[part 15 of 15: packages /ComponentTypes to /RecDataType]
AUTOSAR XML (schema 4-3-0)
package /ComponentTypes  (continued)
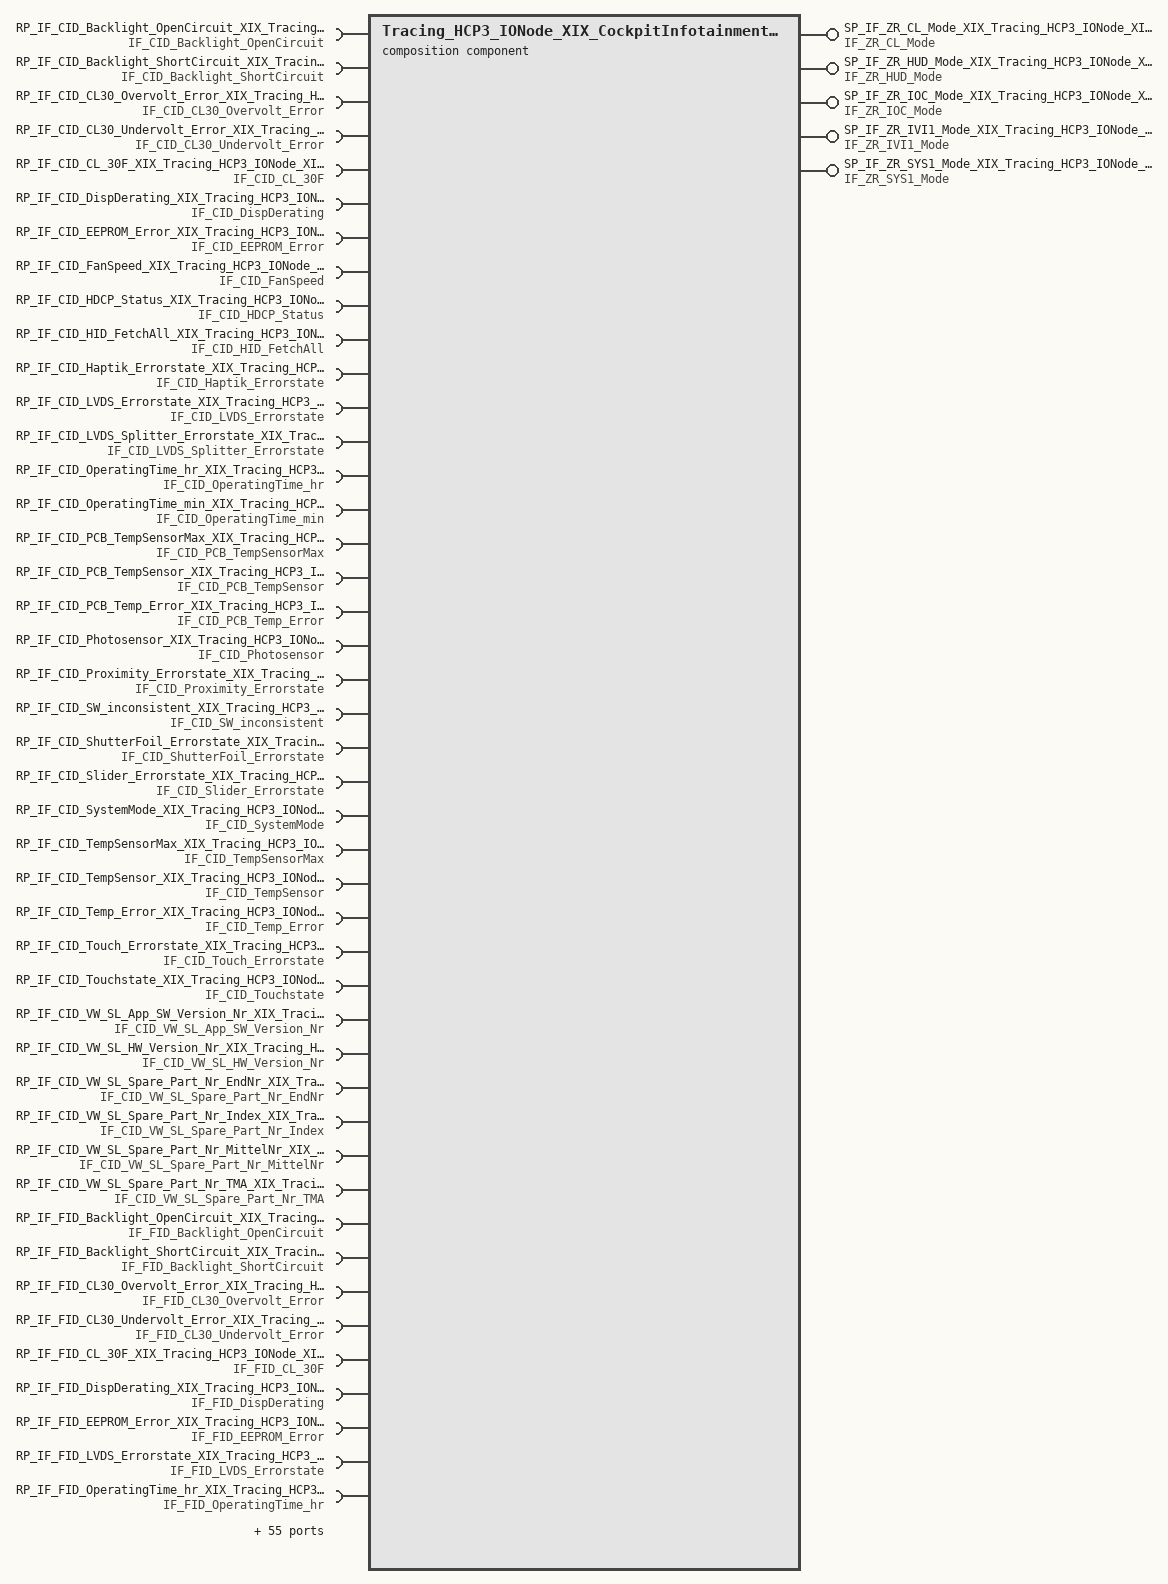
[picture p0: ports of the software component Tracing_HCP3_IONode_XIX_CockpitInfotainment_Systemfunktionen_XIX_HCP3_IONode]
  composition sw component type Tracing_HCP3_IONode_XIX_CockpitInfotainment_Systemfunktionen_XIX_HCP3_IONode
    5 x provide port:
      SP_IF_ZR_CL_Mode_XIX_Tracing_HCP3_IONode_XIX_CockpitInfotainment_Systemfunktionen_XIX_HCP3_IONode: provided-interface=IF_ZR_CL_Mode
      SP_IF_ZR_HUD_Mode_XIX_Tracing_HCP3_IONode_XIX_CockpitInfotainment_Systemfunktionen_XIX_HCP3_IONode: provided-interface=IF_ZR_HUD_Mode
      SP_IF_ZR_IOC_Mode_XIX_Tracing_HCP3_IONode_XIX_CockpitInfotainment_Systemfunktionen_XIX_HCP3_IONode: provided-interface=IF_ZR_IOC_Mode
      SP_IF_ZR_IVI1_Mode_XIX_Tracing_HCP3_IONode_XIX_CockpitInfotainment_Systemfunktionen_XIX_HCP3_IONode: provided-interface=IF_ZR_IVI1_Mode
      SP_IF_ZR_SYS1_Mode_XIX_Tracing_HCP3_IONode_XIX_CockpitInfotainment_Systemfunktionen_XIX_HCP3_IONode: provided-interface=IF_ZR_SYS1_Mode
    99 x require port:
      RP_IF_CID_Backlight_OpenCircuit_XIX_Tracing_HCP3_IONode_XIX_CockpitInfotainment_Systemfunktionen_XIX_HCP3_IONode: required-interface=IF_CID_Backlight_OpenCircuit
      RP_IF_CID_Backlight_ShortCircuit_XIX_Tracing_HCP3_IONode_XIX_CockpitInfotainment_Systemfunktionen_XIX_HCP3_IONode: required-interface=IF_CID_Backlight_ShortCircuit
      RP_IF_CID_CL30_Overvolt_Error_XIX_Tracing_HCP3_IONode_XIX_CockpitInfotainment_Systemfunktionen_XIX_HCP3_IONode: required-interface=IF_CID_CL30_Overvolt_Error
      RP_IF_CID_CL30_Undervolt_Error_XIX_Tracing_HCP3_IONode_XIX_CockpitInfotainment_Systemfunktionen_XIX_HCP3_IONode: required-interface=IF_CID_CL30_Undervolt_Error
      RP_IF_CID_CL_30F_XIX_Tracing_HCP3_IONode_XIX_CockpitInfotainment_Systemfunktionen_XIX_HCP3_IONode: required-interface=IF_CID_CL_30F
      RP_IF_CID_DispDerating_XIX_Tracing_HCP3_IONode_XIX_CockpitInfotainment_Systemfunktionen_XIX_HCP3_IONode: required-interface=IF_CID_DispDerating
      RP_IF_CID_EEPROM_Error_XIX_Tracing_HCP3_IONode_XIX_CockpitInfotainment_Systemfunktionen_XIX_HCP3_IONode: required-interface=IF_CID_EEPROM_Error
      RP_IF_CID_FanSpeed_XIX_Tracing_HCP3_IONode_XIX_CockpitInfotainment_Systemfunktionen_XIX_HCP3_IONode: required-interface=IF_CID_FanSpeed
      RP_IF_CID_HDCP_Status_XIX_Tracing_HCP3_IONode_XIX_CockpitInfotainment_Systemfunktionen_XIX_HCP3_IONode: required-interface=IF_CID_HDCP_Status
      RP_IF_CID_HID_FetchAll_XIX_Tracing_HCP3_IONode_XIX_CockpitInfotainment_Systemfunktionen_XIX_HCP3_IONode: required-interface=IF_CID_HID_FetchAll
      RP_IF_CID_Haptik_Errorstate_XIX_Tracing_HCP3_IONode_XIX_CockpitInfotainment_Systemfunktionen_XIX_HCP3_IONode: required-interface=IF_CID_Haptik_Errorstate
      RP_IF_CID_LVDS_Errorstate_XIX_Tracing_HCP3_IONode_XIX_CockpitInfotainment_Systemfunktionen_XIX_HCP3_IONode: required-interface=IF_CID_LVDS_Errorstate
      RP_IF_CID_LVDS_Splitter_Errorstate_XIX_Tracing_HCP3_IONode_XIX_CockpitInfotainment_Systemfunktionen_XIX_HCP3_IONode: required-interface=IF_CID_LVDS_Splitter_Errorstate
      RP_IF_CID_OperatingTime_hr_XIX_Tracing_HCP3_IONode_XIX_CockpitInfotainment_Systemfunktionen_XIX_HCP3_IONode: required-interface=IF_CID_OperatingTime_hr
      RP_IF_CID_OperatingTime_min_XIX_Tracing_HCP3_IONode_XIX_CockpitInfotainment_Systemfunktionen_XIX_HCP3_IONode: required-interface=IF_CID_OperatingTime_min
      RP_IF_CID_PCB_TempSensorMax_XIX_Tracing_HCP3_IONode_XIX_CockpitInfotainment_Systemfunktionen_XIX_HCP3_IONode: required-interface=IF_CID_PCB_TempSensorMax
      RP_IF_CID_PCB_TempSensor_XIX_Tracing_HCP3_IONode_XIX_CockpitInfotainment_Systemfunktionen_XIX_HCP3_IONode: required-interface=IF_CID_PCB_TempSensor
      RP_IF_CID_PCB_Temp_Error_XIX_Tracing_HCP3_IONode_XIX_CockpitInfotainment_Systemfunktionen_XIX_HCP3_IONode: required-interface=IF_CID_PCB_Temp_Error
      RP_IF_CID_Photosensor_XIX_Tracing_HCP3_IONode_XIX_CockpitInfotainment_Systemfunktionen_XIX_HCP3_IONode: required-interface=IF_CID_Photosensor
      RP_IF_CID_Proximity_Errorstate_XIX_Tracing_HCP3_IONode_XIX_CockpitInfotainment_Systemfunktionen_XIX_HCP3_IONode: required-interface=IF_CID_Proximity_Errorstate
      RP_IF_CID_SW_inconsistent_XIX_Tracing_HCP3_IONode_XIX_CockpitInfotainment_Systemfunktionen_XIX_HCP3_IONode: required-interface=IF_CID_SW_inconsistent
      RP_IF_CID_ShutterFoil_Errorstate_XIX_Tracing_HCP3_IONode_XIX_CockpitInfotainment_Systemfunktionen_XIX_HCP3_IONode: required-interface=IF_CID_ShutterFoil_Errorstate
      RP_IF_CID_Slider_Errorstate_XIX_Tracing_HCP3_IONode_XIX_CockpitInfotainment_Systemfunktionen_XIX_HCP3_IONode: required-interface=IF_CID_Slider_Errorstate
      RP_IF_CID_SystemMode_XIX_Tracing_HCP3_IONode_XIX_CockpitInfotainment_Systemfunktionen_XIX_HCP3_IONode: required-interface=IF_CID_SystemMode
      RP_IF_CID_TempSensorMax_XIX_Tracing_HCP3_IONode_XIX_CockpitInfotainment_Systemfunktionen_XIX_HCP3_IONode: required-interface=IF_CID_TempSensorMax
      RP_IF_CID_TempSensor_XIX_Tracing_HCP3_IONode_XIX_CockpitInfotainment_Systemfunktionen_XIX_HCP3_IONode: required-interface=IF_CID_TempSensor
      RP_IF_CID_Temp_Error_XIX_Tracing_HCP3_IONode_XIX_CockpitInfotainment_Systemfunktionen_XIX_HCP3_IONode: required-interface=IF_CID_Temp_Error
      RP_IF_CID_Touch_Errorstate_XIX_Tracing_HCP3_IONode_XIX_CockpitInfotainment_Systemfunktionen_XIX_HCP3_IONode: required-interface=IF_CID_Touch_Errorstate
      RP_IF_CID_Touchstate_XIX_Tracing_HCP3_IONode_XIX_CockpitInfotainment_Systemfunktionen_XIX_HCP3_IONode: required-interface=IF_CID_Touchstate
      RP_IF_CID_VW_SL_App_SW_Version_Nr_XIX_Tracing_HCP3_IONode_XIX_CockpitInfotainment_Systemfunktionen_XIX_HCP3_IONode: required-interface=IF_CID_VW_SL_App_SW_Version_Nr
      RP_IF_CID_VW_SL_HW_Version_Nr_XIX_Tracing_HCP3_IONode_XIX_CockpitInfotainment_Systemfunktionen_XIX_HCP3_IONode: required-interface=IF_CID_VW_SL_HW_Version_Nr
      RP_IF_CID_VW_SL_Spare_Part_Nr_EndNr_XIX_Tracing_HCP3_IONode_XIX_CockpitInfotainment_Systemfunktionen_XIX_HCP3_IONode: required-interface=IF_CID_VW_SL_Spare_Part_Nr_EndNr
      RP_IF_CID_VW_SL_Spare_Part_Nr_Index_XIX_Tracing_HCP3_IONode_XIX_CockpitInfotainment_Systemfunktionen_XIX_HCP3_IONode: required-interface=IF_CID_VW_SL_Spare_Part_Nr_Index
      RP_IF_CID_VW_SL_Spare_Part_Nr_MittelNr_XIX_Tracing_HCP3_IONode_XIX_CockpitInfotainment_Systemfunktionen_XIX_HCP3_IONode: required-interface=IF_CID_VW_SL_Spare_Part_Nr_MittelNr
      RP_IF_CID_VW_SL_Spare_Part_Nr_TMA_XIX_Tracing_HCP3_IONode_XIX_CockpitInfotainment_Systemfunktionen_XIX_HCP3_IONode: required-interface=IF_CID_VW_SL_Spare_Part_Nr_TMA
      RP_IF_FID_Backlight_OpenCircuit_XIX_Tracing_HCP3_IONode_XIX_CockpitInfotainment_Systemfunktionen_XIX_HCP3_IONode: required-interface=IF_FID_Backlight_OpenCircuit
      RP_IF_FID_Backlight_ShortCircuit_XIX_Tracing_HCP3_IONode_XIX_CockpitInfotainment_Systemfunktionen_XIX_HCP3_IONode: required-interface=IF_FID_Backlight_ShortCircuit
      RP_IF_FID_CL30_Overvolt_Error_XIX_Tracing_HCP3_IONode_XIX_CockpitInfotainment_Systemfunktionen_XIX_HCP3_IONode: required-interface=IF_FID_CL30_Overvolt_Error
      RP_IF_FID_CL30_Undervolt_Error_XIX_Tracing_HCP3_IONode_XIX_CockpitInfotainment_Systemfunktionen_XIX_HCP3_IONode: required-interface=IF_FID_CL30_Undervolt_Error
      RP_IF_FID_CL_30F_XIX_Tracing_HCP3_IONode_XIX_CockpitInfotainment_Systemfunktionen_XIX_HCP3_IONode: required-interface=IF_FID_CL_30F
      RP_IF_FID_DispDerating_XIX_Tracing_HCP3_IONode_XIX_CockpitInfotainment_Systemfunktionen_XIX_HCP3_IONode: required-interface=IF_FID_DispDerating
      RP_IF_FID_EEPROM_Error_XIX_Tracing_HCP3_IONode_XIX_CockpitInfotainment_Systemfunktionen_XIX_HCP3_IONode: required-interface=IF_FID_EEPROM_Error
      RP_IF_FID_LVDS_Errorstate_XIX_Tracing_HCP3_IONode_XIX_CockpitInfotainment_Systemfunktionen_XIX_HCP3_IONode: required-interface=IF_FID_LVDS_Errorstate
      RP_IF_FID_OperatingTime_hr_XIX_Tracing_HCP3_IONode_XIX_CockpitInfotainment_Systemfunktionen_XIX_HCP3_IONode: required-interface=IF_FID_OperatingTime_hr
      RP_IF_FID_OperatingTime_min_XIX_Tracing_HCP3_IONode_XIX_CockpitInfotainment_Systemfunktionen_XIX_HCP3_IONode: required-interface=IF_FID_OperatingTime_min
      RP_IF_FID_PCB_TempSensorMax_XIX_Tracing_HCP3_IONode_XIX_CockpitInfotainment_Systemfunktionen_XIX_HCP3_IONode: required-interface=IF_FID_PCB_TempSensorMax
      RP_IF_FID_PCB_TempSensor_XIX_Tracing_HCP3_IONode_XIX_CockpitInfotainment_Systemfunktionen_XIX_HCP3_IONode: required-interface=IF_FID_PCB_TempSensor
      RP_IF_FID_PCB_Temp_Error_XIX_Tracing_HCP3_IONode_XIX_CockpitInfotainment_Systemfunktionen_XIX_HCP3_IONode: required-interface=IF_FID_PCB_Temp_Error
      RP_IF_FID_Photosensor_XIX_Tracing_HCP3_IONode_XIX_CockpitInfotainment_Systemfunktionen_XIX_HCP3_IONode: required-interface=IF_FID_Photosensor
      RP_IF_FID_SW_inconsistent_XIX_Tracing_HCP3_IONode_XIX_CockpitInfotainment_Systemfunktionen_XIX_HCP3_IONode: required-interface=IF_FID_SW_inconsistent
      RP_IF_FID_SystemMode_XIX_Tracing_HCP3_IONode_XIX_CockpitInfotainment_Systemfunktionen_XIX_HCP3_IONode: required-interface=IF_FID_SystemMode
      RP_IF_FID_TempSensorMax_XIX_Tracing_HCP3_IONode_XIX_CockpitInfotainment_Systemfunktionen_XIX_HCP3_IONode: required-interface=IF_FID_TempSensorMax
      RP_IF_FID_TempSensor_XIX_Tracing_HCP3_IONode_XIX_CockpitInfotainment_Systemfunktionen_XIX_HCP3_IONode: required-interface=IF_FID_TempSensor
      RP_IF_FID_Temp_Error_XIX_Tracing_HCP3_IONode_XIX_CockpitInfotainment_Systemfunktionen_XIX_HCP3_IONode: required-interface=IF_FID_Temp_Error
      RP_IF_LSR_CL30_Overvolt_Error_XIX_Tracing_HCP3_IONode_XIX_CockpitInfotainment_Systemfunktionen_XIX_HCP3_IONode: required-interface=IF_LSR_CL30_Overvolt_Error
      RP_IF_LSR_CL30_Undervoltage_Error_XIX_Tracing_HCP3_IONode_XIX_CockpitInfotainment_Systemfunktionen_XIX_HCP3_IONode: required-interface=IF_LSR_CL30_Undervoltage_Error
      RP_IF_LSR_SystemMode_XIX_Tracing_HCP3_IONode_XIX_CockpitInfotainment_Systemfunktionen_XIX_HCP3_IONode: required-interface=IF_LSR_SystemMode
      RP_IF_LSR_VW_SL_App_SW_Version_Nr_XIX_Tracing_HCP3_IONode_XIX_CockpitInfotainment_Systemfunktionen_XIX_HCP3_IONode: required-interface=IF_LSR_VW_SL_App_SW_Version_Nr
      RP_IF_LSR_VW_SL_HW_Version_Nr_XIX_Tracing_HCP3_IONode_XIX_CockpitInfotainment_Systemfunktionen_XIX_HCP3_IONode: required-interface=IF_LSR_VW_SL_HW_Version_Nr
      RP_IF_LSR_VW_SL_Spare_Part_Nr_EndNr_XIX_Tracing_HCP3_IONode_XIX_CockpitInfotainment_Systemfunktionen_XIX_HCP3_IONode: required-interface=IF_LSR_VW_SL_Spare_Part_Nr_EndNr
      RP_IF_LSR_VW_SL_Spare_Part_Nr_Index_XIX_Tracing_HCP3_IONode_XIX_CockpitInfotainment_Systemfunktionen_XIX_HCP3_IONode: required-interface=IF_LSR_VW_SL_Spare_Part_Nr_Index
      RP_IF_LSR_VW_SL_Spare_Part_Nr_MittelNr_XIX_Tracing_HCP3_IONode_XIX_CockpitInfotainment_Systemfunktionen_XIX_HCP3_IONode: required-interface=IF_LSR_VW_SL_Spare_Part_Nr_MittelNr
      RP_IF_LSR_VW_SL_Spare_Part_Nr_TMA_XIX_Tracing_HCP3_IONode_XIX_CockpitInfotainment_Systemfunktionen_XIX_HCP3_IONode: required-interface=IF_LSR_VW_SL_Spare_Part_Nr_TMA
      RP_IF_LSR_dimming_PWM_XIX_Tracing_HCP3_IONode_XIX_CockpitInfotainment_Systemfunktionen_XIX_HCP3_IONode: required-interface=IF_LSR_dimming_PWM
      RP_IF_LSR_dimming_post_carriage_XIX_Tracing_HCP3_IONode_XIX_CockpitInfotainment_Systemfunktionen_XIX_HCP3_IONode: required-interface=IF_LSR_dimming_post_carriage
      RP_IF_PID_Backlight_OpenCircuit_XIX_Tracing_HCP3_IONode_XIX_CockpitInfotainment_Systemfunktionen_XIX_HCP3_IONode: required-interface=IF_PID_Backlight_OpenCircuit
      RP_IF_PID_Backlight_ShortCircuit_XIX_Tracing_HCP3_IONode_XIX_CockpitInfotainment_Systemfunktionen_XIX_HCP3_IONode: required-interface=IF_PID_Backlight_ShortCircuit
      RP_IF_PID_CL30_Overvoltage_Error_XIX_Tracing_HCP3_IONode_XIX_CockpitInfotainment_Systemfunktionen_XIX_HCP3_IONode: required-interface=IF_PID_CL30_Overvoltage_Error
      RP_IF_PID_CL30_Undervoltage_Error_XIX_Tracing_HCP3_IONode_XIX_CockpitInfotainment_Systemfunktionen_XIX_HCP3_IONode: required-interface=IF_PID_CL30_Undervoltage_Error
      RP_IF_PID_CL_30F_XIX_Tracing_HCP3_IONode_XIX_CockpitInfotainment_Systemfunktionen_XIX_HCP3_IONode: required-interface=IF_PID_CL_30F
      RP_IF_PID_DispDerating_XIX_Tracing_HCP3_IONode_XIX_CockpitInfotainment_Systemfunktionen_XIX_HCP3_IONode: required-interface=IF_PID_DispDerating
      RP_IF_PID_EEPROM_Error_XIX_Tracing_HCP3_IONode_XIX_CockpitInfotainment_Systemfunktionen_XIX_HCP3_IONode: required-interface=IF_PID_EEPROM_Error
      RP_IF_PID_FanSpeed_XIX_Tracing_HCP3_IONode_XIX_CockpitInfotainment_Systemfunktionen_XIX_HCP3_IONode: required-interface=IF_PID_FanSpeed
      RP_IF_PID_HDCP_Status_XIX_Tracing_HCP3_IONode_XIX_CockpitInfotainment_Systemfunktionen_XIX_HCP3_IONode: required-interface=IF_PID_HDCP_Status
      RP_IF_PID_Haptik_Errorstate_XIX_Tracing_HCP3_IONode_XIX_CockpitInfotainment_Systemfunktionen_XIX_HCP3_IONode: required-interface=IF_PID_Haptik_Errorstate
      RP_IF_PID_LVDS_Errorstate_XIX_Tracing_HCP3_IONode_XIX_CockpitInfotainment_Systemfunktionen_XIX_HCP3_IONode: required-interface=IF_PID_LVDS_Errorstate
      RP_IF_PID_LVDS_Splitter_Errorstate_XIX_Tracing_HCP3_IONode_XIX_CockpitInfotainment_Systemfunktionen_XIX_HCP3_IONode: required-interface=IF_PID_LVDS_Splitter_Errorstate
      RP_IF_PID_OperatingTime_hr_XIX_Tracing_HCP3_IONode_XIX_CockpitInfotainment_Systemfunktionen_XIX_HCP3_IONode: required-interface=IF_PID_OperatingTime_hr
      RP_IF_PID_OperatingTime_min_XIX_Tracing_HCP3_IONode_XIX_CockpitInfotainment_Systemfunktionen_XIX_HCP3_IONode: required-interface=IF_PID_OperatingTime_min
      RP_IF_PID_PCB_TempSensorMax_XIX_Tracing_HCP3_IONode_XIX_CockpitInfotainment_Systemfunktionen_XIX_HCP3_IONode: required-interface=IF_PID_PCB_TempSensorMax
      RP_IF_PID_PCB_TempSensor_XIX_Tracing_HCP3_IONode_XIX_CockpitInfotainment_Systemfunktionen_XIX_HCP3_IONode: required-interface=IF_PID_PCB_TempSensor
      RP_IF_PID_PCB_Temp_Error_XIX_Tracing_HCP3_IONode_XIX_CockpitInfotainment_Systemfunktionen_XIX_HCP3_IONode: required-interface=IF_PID_PCB_Temp_Error
      RP_IF_PID_Photosensor_XIX_Tracing_HCP3_IONode_XIX_CockpitInfotainment_Systemfunktionen_XIX_HCP3_IONode: required-interface=IF_PID_Photosensor
      RP_IF_PID_Proximity_Errorstate_XIX_Tracing_HCP3_IONode_XIX_CockpitInfotainment_Systemfunktionen_XIX_HCP3_IONode: required-interface=IF_PID_Proximity_Errorstate
      RP_IF_PID_SW_inconsistent_XIX_Tracing_HCP3_IONode_XIX_CockpitInfotainment_Systemfunktionen_XIX_HCP3_IONode: required-interface=IF_PID_SW_inconsistent
      RP_IF_PID_ShutterFoil_Errorstate_XIX_Tracing_HCP3_IONode_XIX_CockpitInfotainment_Systemfunktionen_XIX_HCP3_IONode: required-interface=IF_PID_ShutterFoil_Errorstate
      RP_IF_PID_Slider_Errorstate_XIX_Tracing_HCP3_IONode_XIX_CockpitInfotainment_Systemfunktionen_XIX_HCP3_IONode: required-interface=IF_PID_Slider_Errorstate
      RP_IF_PID_SystemMode_XIX_Tracing_HCP3_IONode_XIX_CockpitInfotainment_Systemfunktionen_XIX_HCP3_IONode: required-interface=IF_PID_SystemMode
      RP_IF_PID_TempSensorMax_XIX_Tracing_HCP3_IONode_XIX_CockpitInfotainment_Systemfunktionen_XIX_HCP3_IONode: required-interface=IF_PID_TempSensorMax
      RP_IF_PID_TempSensor_XIX_Tracing_HCP3_IONode_XIX_CockpitInfotainment_Systemfunktionen_XIX_HCP3_IONode: required-interface=IF_PID_TempSensor
      RP_IF_PID_Temp_Error_XIX_Tracing_HCP3_IONode_XIX_CockpitInfotainment_Systemfunktionen_XIX_HCP3_IONode: required-interface=IF_PID_Temp_Error
      RP_IF_PID_Touch_Errorstate_XIX_Tracing_HCP3_IONode_XIX_CockpitInfotainment_Systemfunktionen_XIX_HCP3_IONode: required-interface=IF_PID_Touch_Errorstate
      RP_IF_PID_Touchstate_XIX_Tracing_HCP3_IONode_XIX_CockpitInfotainment_Systemfunktionen_XIX_HCP3_IONode: required-interface=IF_PID_Touchstate
      RP_IF_PID_VW_SL_App_SW_Version_Nr_XIX_Tracing_HCP3_IONode_XIX_CockpitInfotainment_Systemfunktionen_XIX_HCP3_IONode: required-interface=IF_PID_VW_SL_App_SW_Version_Nr
      RP_IF_PID_VW_SL_HW_Version_Nr_XIX_Tracing_HCP3_IONode_XIX_CockpitInfotainment_Systemfunktionen_XIX_HCP3_IONode: required-interface=IF_PID_VW_SL_HW_Version_Nr
      RP_IF_PID_VW_SL_Spare_Part_Nr_EndNr_XIX_Tracing_HCP3_IONode_XIX_CockpitInfotainment_Systemfunktionen_XIX_HCP3_IONode: required-interface=IF_PID_VW_SL_Spare_Part_Nr_EndNr
      RP_IF_PID_VW_SL_Spare_Part_Nr_Index_XIX_Tracing_HCP3_IONode_XIX_CockpitInfotainment_Systemfunktionen_XIX_HCP3_IONode: required-interface=IF_PID_VW_SL_Spare_Part_Nr_Index
      RP_IF_PID_VW_SL_Spare_Part_Nr_MittelNr_XIX_Tracing_HCP3_IONode_XIX_CockpitInfotainment_Systemfunktionen_XIX_HCP3_IONode: required-interface=IF_PID_VW_SL_Spare_Part_Nr_MittelNr
      RP_IF_PID_VW_SL_Spare_Part_Nr_TMA_XIX_Tracing_HCP3_IONode_XIX_CockpitInfotainment_Systemfunktionen_XIX_HCP3_IONode: required-interface=IF_PID_VW_SL_Spare_Part_Nr_TMA
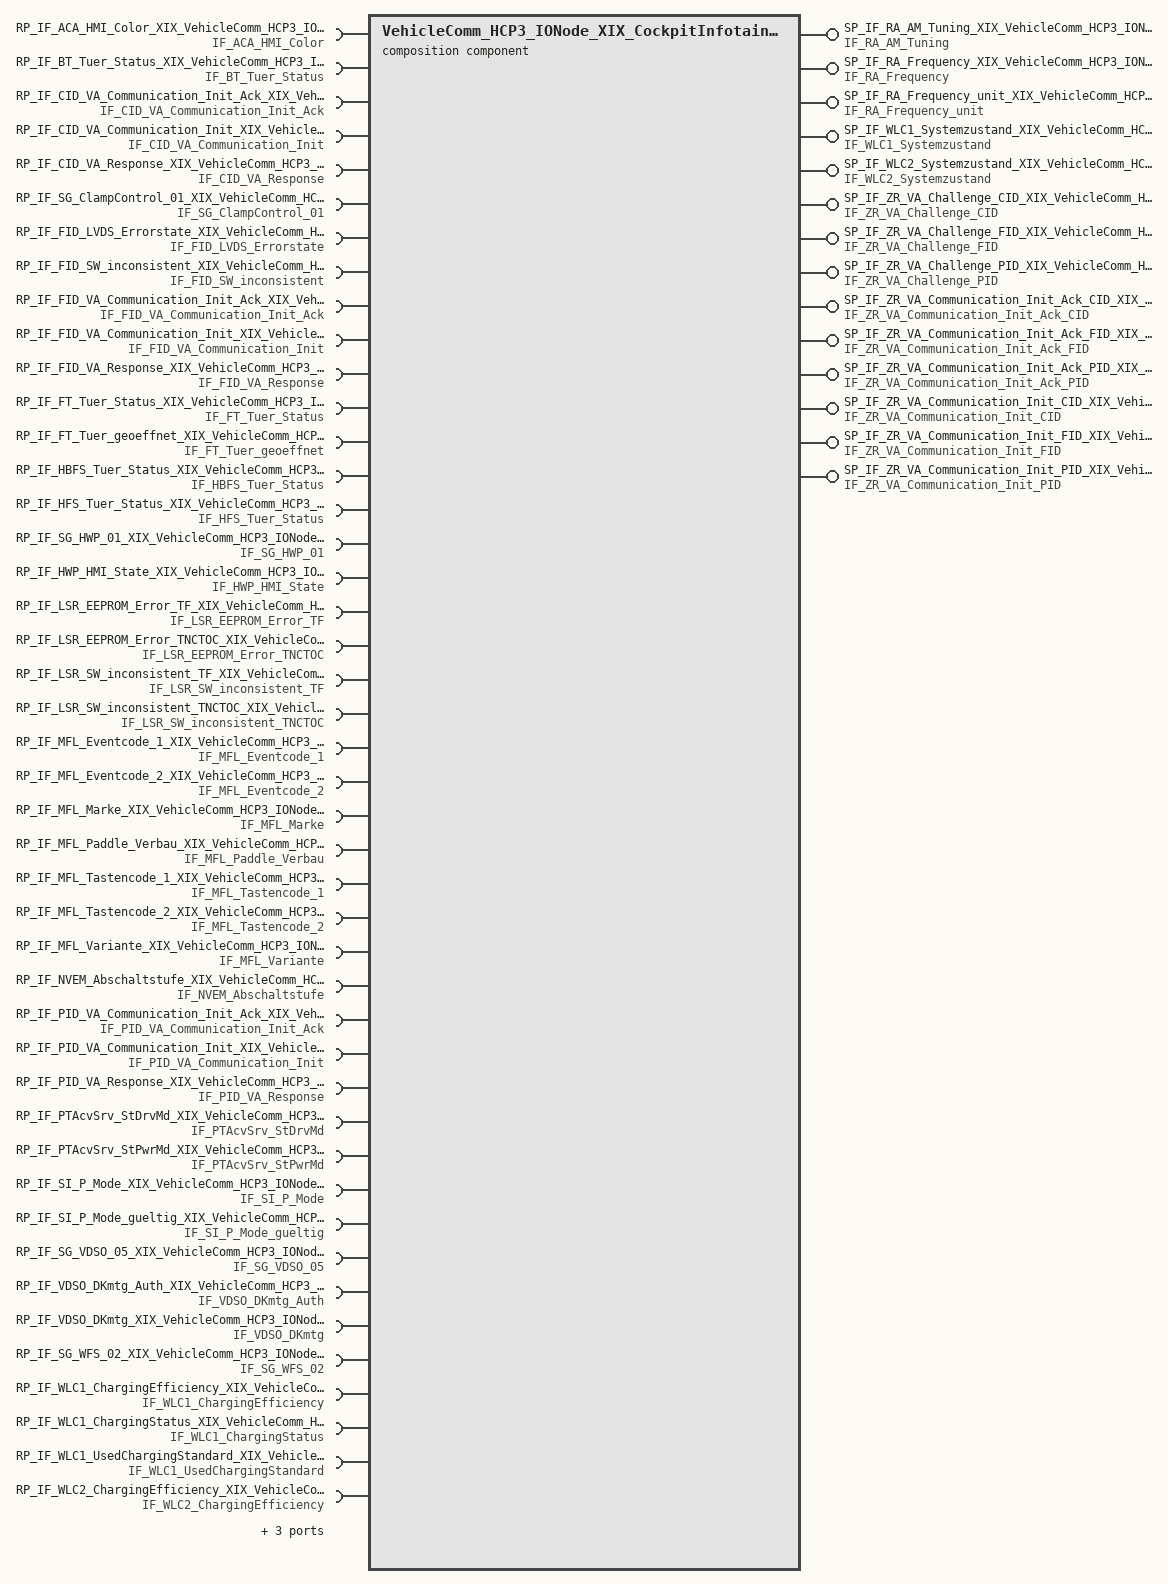
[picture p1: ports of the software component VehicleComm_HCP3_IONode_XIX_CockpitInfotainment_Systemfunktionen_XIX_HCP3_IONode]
  composition sw component type VehicleComm_HCP3_IONode_XIX_CockpitInfotainment_Systemfunktionen_XIX_HCP3_IONode
    14 x provide port:
      SP_IF_RA_AM_Tuning_XIX_VehicleComm_HCP3_IONode_XIX_CockpitInfotainment_Systemfunktionen_XIX_HCP3_IONode: provided-interface=IF_RA_AM_Tuning
      SP_IF_RA_Frequency_XIX_VehicleComm_HCP3_IONode_XIX_CockpitInfotainment_Systemfunktionen_XIX_HCP3_IONode: provided-interface=IF_RA_Frequency
      SP_IF_RA_Frequency_unit_XIX_VehicleComm_HCP3_IONode_XIX_CockpitInfotainment_Systemfunktionen_XIX_HCP3_IONode: provided-interface=IF_RA_Frequency_unit
      SP_IF_WLC1_Systemzustand_XIX_VehicleComm_HCP3_IONode_XIX_CockpitInfotainment_Systemfunktionen_XIX_HCP3_IONode: provided-interface=IF_WLC1_Systemzustand
      SP_IF_WLC2_Systemzustand_XIX_VehicleComm_HCP3_IONode_XIX_CockpitInfotainment_Systemfunktionen_XIX_HCP3_IONode: provided-interface=IF_WLC2_Systemzustand
      SP_IF_ZR_VA_Challenge_CID_XIX_VehicleComm_HCP3_IONode_XIX_CockpitInfotainment_Systemfunktionen_XIX_HCP3_IONode: provided-interface=IF_ZR_VA_Challenge_CID
      SP_IF_ZR_VA_Challenge_FID_XIX_VehicleComm_HCP3_IONode_XIX_CockpitInfotainment_Systemfunktionen_XIX_HCP3_IONode: provided-interface=IF_ZR_VA_Challenge_FID
      SP_IF_ZR_VA_Challenge_PID_XIX_VehicleComm_HCP3_IONode_XIX_CockpitInfotainment_Systemfunktionen_XIX_HCP3_IONode: provided-interface=IF_ZR_VA_Challenge_PID
      SP_IF_ZR_VA_Communication_Init_Ack_CID_XIX_VehicleComm_HCP3_IONode_XIX_CockpitInfotainment_Systemfunktionen_XIX_HCP3_IONode: provided-interface=IF_ZR_VA_Communication_Init_Ack_CID
      SP_IF_ZR_VA_Communication_Init_Ack_FID_XIX_VehicleComm_HCP3_IONode_XIX_CockpitInfotainment_Systemfunktionen_XIX_HCP3_IONode: provided-interface=IF_ZR_VA_Communication_Init_Ack_FID
      SP_IF_ZR_VA_Communication_Init_Ack_PID_XIX_VehicleComm_HCP3_IONode_XIX_CockpitInfotainment_Systemfunktionen_XIX_HCP3_IONode: provided-interface=IF_ZR_VA_Communication_Init_Ack_PID
      SP_IF_ZR_VA_Communication_Init_CID_XIX_VehicleComm_HCP3_IONode_XIX_CockpitInfotainment_Systemfunktionen_XIX_HCP3_IONode: provided-interface=IF_ZR_VA_Communication_Init_CID
      SP_IF_ZR_VA_Communication_Init_FID_XIX_VehicleComm_HCP3_IONode_XIX_CockpitInfotainment_Systemfunktionen_XIX_HCP3_IONode: provided-interface=IF_ZR_VA_Communication_Init_FID
      SP_IF_ZR_VA_Communication_Init_PID_XIX_VehicleComm_HCP3_IONode_XIX_CockpitInfotainment_Systemfunktionen_XIX_HCP3_IONode: provided-interface=IF_ZR_VA_Communication_Init_PID
    47 x require port:
      RP_IF_ACA_HMI_Color_XIX_VehicleComm_HCP3_IONode_XIX_CockpitInfotainment_Systemfunktionen_XIX_HCP3_IONode: required-interface=IF_ACA_HMI_Color
      RP_IF_BT_Tuer_Status_XIX_VehicleComm_HCP3_IONode_XIX_CockpitInfotainment_Systemfunktionen_XIX_HCP3_IONode: required-interface=IF_BT_Tuer_Status
      RP_IF_CID_VA_Communication_Init_Ack_XIX_VehicleComm_HCP3_IONode_XIX_CockpitInfotainment_Systemfunktionen_XIX_HCP3_IONode: required-interface=IF_CID_VA_Communication_Init_Ack
      RP_IF_CID_VA_Communication_Init_XIX_VehicleComm_HCP3_IONode_XIX_CockpitInfotainment_Systemfunktionen_XIX_HCP3_IONode: required-interface=IF_CID_VA_Communication_Init
      RP_IF_CID_VA_Response_XIX_VehicleComm_HCP3_IONode_XIX_CockpitInfotainment_Systemfunktionen_XIX_HCP3_IONode: required-interface=IF_CID_VA_Response
      RP_IF_SG_ClampControl_01_XIX_VehicleComm_HCP3_IONode_XIX_CockpitInfotainment_Systemfunktionen_XIX_HCP3_IONode: required-interface=IF_SG_ClampControl_01
      RP_IF_FID_LVDS_Errorstate_XIX_VehicleComm_HCP3_IONode_XIX_CockpitInfotainment_Systemfunktionen_XIX_HCP3_IONode: required-interface=IF_FID_LVDS_Errorstate
      RP_IF_FID_SW_inconsistent_XIX_VehicleComm_HCP3_IONode_XIX_CockpitInfotainment_Systemfunktionen_XIX_HCP3_IONode: required-interface=IF_FID_SW_inconsistent
      RP_IF_FID_VA_Communication_Init_Ack_XIX_VehicleComm_HCP3_IONode_XIX_CockpitInfotainment_Systemfunktionen_XIX_HCP3_IONode: required-interface=IF_FID_VA_Communication_Init_Ack
      RP_IF_FID_VA_Communication_Init_XIX_VehicleComm_HCP3_IONode_XIX_CockpitInfotainment_Systemfunktionen_XIX_HCP3_IONode: required-interface=IF_FID_VA_Communication_Init
      RP_IF_FID_VA_Response_XIX_VehicleComm_HCP3_IONode_XIX_CockpitInfotainment_Systemfunktionen_XIX_HCP3_IONode: required-interface=IF_FID_VA_Response
      RP_IF_FT_Tuer_Status_XIX_VehicleComm_HCP3_IONode_XIX_CockpitInfotainment_Systemfunktionen_XIX_HCP3_IONode: required-interface=IF_FT_Tuer_Status
      RP_IF_FT_Tuer_geoeffnet_XIX_VehicleComm_HCP3_IONode_XIX_CockpitInfotainment_Systemfunktionen_XIX_HCP3_IONode: required-interface=IF_FT_Tuer_geoeffnet
      RP_IF_HBFS_Tuer_Status_XIX_VehicleComm_HCP3_IONode_XIX_CockpitInfotainment_Systemfunktionen_XIX_HCP3_IONode: required-interface=IF_HBFS_Tuer_Status
      RP_IF_HFS_Tuer_Status_XIX_VehicleComm_HCP3_IONode_XIX_CockpitInfotainment_Systemfunktionen_XIX_HCP3_IONode: required-interface=IF_HFS_Tuer_Status
      RP_IF_SG_HWP_01_XIX_VehicleComm_HCP3_IONode_XIX_CockpitInfotainment_Systemfunktionen_XIX_HCP3_IONode: required-interface=IF_SG_HWP_01
      RP_IF_HWP_HMI_State_XIX_VehicleComm_HCP3_IONode_XIX_CockpitInfotainment_Systemfunktionen_XIX_HCP3_IONode: required-interface=IF_HWP_HMI_State
      RP_IF_LSR_EEPROM_Error_TF_XIX_VehicleComm_HCP3_IONode_XIX_CockpitInfotainment_Systemfunktionen_XIX_HCP3_IONode: required-interface=IF_LSR_EEPROM_Error_TF
      RP_IF_LSR_EEPROM_Error_TNCTOC_XIX_VehicleComm_HCP3_IONode_XIX_CockpitInfotainment_Systemfunktionen_XIX_HCP3_IONode: required-interface=IF_LSR_EEPROM_Error_TNCTOC
      RP_IF_LSR_SW_inconsistent_TF_XIX_VehicleComm_HCP3_IONode_XIX_CockpitInfotainment_Systemfunktionen_XIX_HCP3_IONode: required-interface=IF_LSR_SW_inconsistent_TF
      RP_IF_LSR_SW_inconsistent_TNCTOC_XIX_VehicleComm_HCP3_IONode_XIX_CockpitInfotainment_Systemfunktionen_XIX_HCP3_IONode: required-interface=IF_LSR_SW_inconsistent_TNCTOC
      RP_IF_MFL_Eventcode_1_XIX_VehicleComm_HCP3_IONode_XIX_CockpitInfotainment_Systemfunktionen_XIX_HCP3_IONode: required-interface=IF_MFL_Eventcode_1
      RP_IF_MFL_Eventcode_2_XIX_VehicleComm_HCP3_IONode_XIX_CockpitInfotainment_Systemfunktionen_XIX_HCP3_IONode: required-interface=IF_MFL_Eventcode_2
      RP_IF_MFL_Marke_XIX_VehicleComm_HCP3_IONode_XIX_CockpitInfotainment_Systemfunktionen_XIX_HCP3_IONode: required-interface=IF_MFL_Marke
      RP_IF_MFL_Paddle_Verbau_XIX_VehicleComm_HCP3_IONode_XIX_CockpitInfotainment_Systemfunktionen_XIX_HCP3_IONode: required-interface=IF_MFL_Paddle_Verbau
      RP_IF_MFL_Tastencode_1_XIX_VehicleComm_HCP3_IONode_XIX_CockpitInfotainment_Systemfunktionen_XIX_HCP3_IONode: required-interface=IF_MFL_Tastencode_1
      RP_IF_MFL_Tastencode_2_XIX_VehicleComm_HCP3_IONode_XIX_CockpitInfotainment_Systemfunktionen_XIX_HCP3_IONode: required-interface=IF_MFL_Tastencode_2
      RP_IF_MFL_Variante_XIX_VehicleComm_HCP3_IONode_XIX_CockpitInfotainment_Systemfunktionen_XIX_HCP3_IONode: required-interface=IF_MFL_Variante
      RP_IF_NVEM_Abschaltstufe_XIX_VehicleComm_HCP3_IONode_XIX_CockpitInfotainment_Systemfunktionen_XIX_HCP3_IONode: required-interface=IF_NVEM_Abschaltstufe
      RP_IF_PID_VA_Communication_Init_Ack_XIX_VehicleComm_HCP3_IONode_XIX_CockpitInfotainment_Systemfunktionen_XIX_HCP3_IONode: required-interface=IF_PID_VA_Communication_Init_Ack
      RP_IF_PID_VA_Communication_Init_XIX_VehicleComm_HCP3_IONode_XIX_CockpitInfotainment_Systemfunktionen_XIX_HCP3_IONode: required-interface=IF_PID_VA_Communication_Init
      RP_IF_PID_VA_Response_XIX_VehicleComm_HCP3_IONode_XIX_CockpitInfotainment_Systemfunktionen_XIX_HCP3_IONode: required-interface=IF_PID_VA_Response
      RP_IF_PTAcvSrv_StDrvMd_XIX_VehicleComm_HCP3_IONode_XIX_CockpitInfotainment_Systemfunktionen_XIX_HCP3_IONode: required-interface=IF_PTAcvSrv_StDrvMd
      RP_IF_PTAcvSrv_StPwrMd_XIX_VehicleComm_HCP3_IONode_XIX_CockpitInfotainment_Systemfunktionen_XIX_HCP3_IONode: required-interface=IF_PTAcvSrv_StPwrMd
      RP_IF_SI_P_Mode_XIX_VehicleComm_HCP3_IONode_XIX_CockpitInfotainment_Systemfunktionen_XIX_HCP3_IONode: required-interface=IF_SI_P_Mode
      RP_IF_SI_P_Mode_gueltig_XIX_VehicleComm_HCP3_IONode_XIX_CockpitInfotainment_Systemfunktionen_XIX_HCP3_IONode: required-interface=IF_SI_P_Mode_gueltig
      RP_IF_SG_VDSO_05_XIX_VehicleComm_HCP3_IONode_XIX_CockpitInfotainment_Systemfunktionen_XIX_HCP3_IONode: required-interface=IF_SG_VDSO_05
      RP_IF_VDSO_DKmtg_Auth_XIX_VehicleComm_HCP3_IONode_XIX_CockpitInfotainment_Systemfunktionen_XIX_HCP3_IONode: required-interface=IF_VDSO_DKmtg_Auth
      RP_IF_VDSO_DKmtg_XIX_VehicleComm_HCP3_IONode_XIX_CockpitInfotainment_Systemfunktionen_XIX_HCP3_IONode: required-interface=IF_VDSO_DKmtg
      RP_IF_SG_WFS_02_XIX_VehicleComm_HCP3_IONode_XIX_CockpitInfotainment_Systemfunktionen_XIX_HCP3_IONode: required-interface=IF_SG_WFS_02
      RP_IF_WLC1_ChargingEfficiency_XIX_VehicleComm_HCP3_IONode_XIX_CockpitInfotainment_Systemfunktionen_XIX_HCP3_IONode: required-interface=IF_WLC1_ChargingEfficiency
      RP_IF_WLC1_ChargingStatus_XIX_VehicleComm_HCP3_IONode_XIX_CockpitInfotainment_Systemfunktionen_XIX_HCP3_IONode: required-interface=IF_WLC1_ChargingStatus
      RP_IF_WLC1_UsedChargingStandard_XIX_VehicleComm_HCP3_IONode_XIX_CockpitInfotainment_Systemfunktionen_XIX_HCP3_IONode: required-interface=IF_WLC1_UsedChargingStandard
      RP_IF_WLC2_ChargingEfficiency_XIX_VehicleComm_HCP3_IONode_XIX_CockpitInfotainment_Systemfunktionen_XIX_HCP3_IONode: required-interface=IF_WLC2_ChargingEfficiency
      RP_IF_WLC2_ChargingStatus_XIX_VehicleComm_HCP3_IONode_XIX_CockpitInfotainment_Systemfunktionen_XIX_HCP3_IONode: required-interface=IF_WLC2_ChargingStatus
      RP_IF_WLC2_UsedChargingStandard_XIX_VehicleComm_HCP3_IONode_XIX_CockpitInfotainment_Systemfunktionen_XIX_HCP3_IONode: required-interface=IF_WLC2_UsedChargingStandard
      RP_IF_ZV_Heck_offen_XIX_VehicleComm_HCP3_IONode_XIX_CockpitInfotainment_Systemfunktionen_XIX_HCP3_IONode: required-interface=IF_ZV_Heck_offen
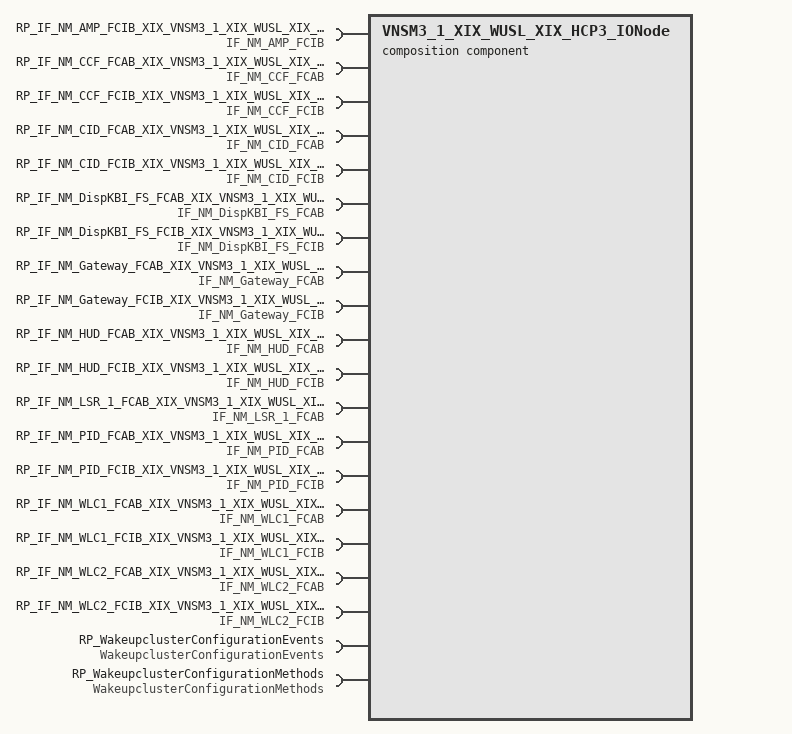
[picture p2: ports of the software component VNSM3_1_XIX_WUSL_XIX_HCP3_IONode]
  composition sw component type VNSM3_1_XIX_WUSL_XIX_HCP3_IONode
    20 x require port:
      RP_IF_NM_AMP_FCIB_XIX_VNSM3_1_XIX_WUSL_XIX_HCP3_IONode: required-interface=IF_NM_AMP_FCIB
      RP_IF_NM_CCF_FCAB_XIX_VNSM3_1_XIX_WUSL_XIX_HCP3_IONode: required-interface=IF_NM_CCF_FCAB
      RP_IF_NM_CCF_FCIB_XIX_VNSM3_1_XIX_WUSL_XIX_HCP3_IONode: required-interface=IF_NM_CCF_FCIB
      RP_IF_NM_CID_FCAB_XIX_VNSM3_1_XIX_WUSL_XIX_HCP3_IONode: required-interface=IF_NM_CID_FCAB
      RP_IF_NM_CID_FCIB_XIX_VNSM3_1_XIX_WUSL_XIX_HCP3_IONode: required-interface=IF_NM_CID_FCIB
      RP_IF_NM_DispKBI_FS_FCAB_XIX_VNSM3_1_XIX_WUSL_XIX_HCP3_IONode: required-interface=IF_NM_DispKBI_FS_FCAB
      RP_IF_NM_DispKBI_FS_FCIB_XIX_VNSM3_1_XIX_WUSL_XIX_HCP3_IONode: required-interface=IF_NM_DispKBI_FS_FCIB
      RP_IF_NM_Gateway_FCAB_XIX_VNSM3_1_XIX_WUSL_XIX_HCP3_IONode: required-interface=IF_NM_Gateway_FCAB
      RP_IF_NM_Gateway_FCIB_XIX_VNSM3_1_XIX_WUSL_XIX_HCP3_IONode: required-interface=IF_NM_Gateway_FCIB
      RP_IF_NM_HUD_FCAB_XIX_VNSM3_1_XIX_WUSL_XIX_HCP3_IONode: required-interface=IF_NM_HUD_FCAB
      RP_IF_NM_HUD_FCIB_XIX_VNSM3_1_XIX_WUSL_XIX_HCP3_IONode: required-interface=IF_NM_HUD_FCIB
      RP_IF_NM_LSR_1_FCAB_XIX_VNSM3_1_XIX_WUSL_XIX_HCP3_IONode: required-interface=IF_NM_LSR_1_FCAB
      RP_IF_NM_PID_FCAB_XIX_VNSM3_1_XIX_WUSL_XIX_HCP3_IONode: required-interface=IF_NM_PID_FCAB
      RP_IF_NM_PID_FCIB_XIX_VNSM3_1_XIX_WUSL_XIX_HCP3_IONode: required-interface=IF_NM_PID_FCIB
      RP_IF_NM_WLC1_FCAB_XIX_VNSM3_1_XIX_WUSL_XIX_HCP3_IONode: required-interface=IF_NM_WLC1_FCAB
      RP_IF_NM_WLC1_FCIB_XIX_VNSM3_1_XIX_WUSL_XIX_HCP3_IONode: required-interface=IF_NM_WLC1_FCIB
      RP_IF_NM_WLC2_FCAB_XIX_VNSM3_1_XIX_WUSL_XIX_HCP3_IONode: required-interface=IF_NM_WLC2_FCAB
      RP_IF_NM_WLC2_FCIB_XIX_VNSM3_1_XIX_WUSL_XIX_HCP3_IONode: required-interface=IF_NM_WLC2_FCIB
      RP_WakeupclusterConfigurationEvents: required-interface=WakeupclusterConfigurationEvents
      RP_WakeupclusterConfigurationMethods: required-interface=WakeupclusterConfigurationMethods
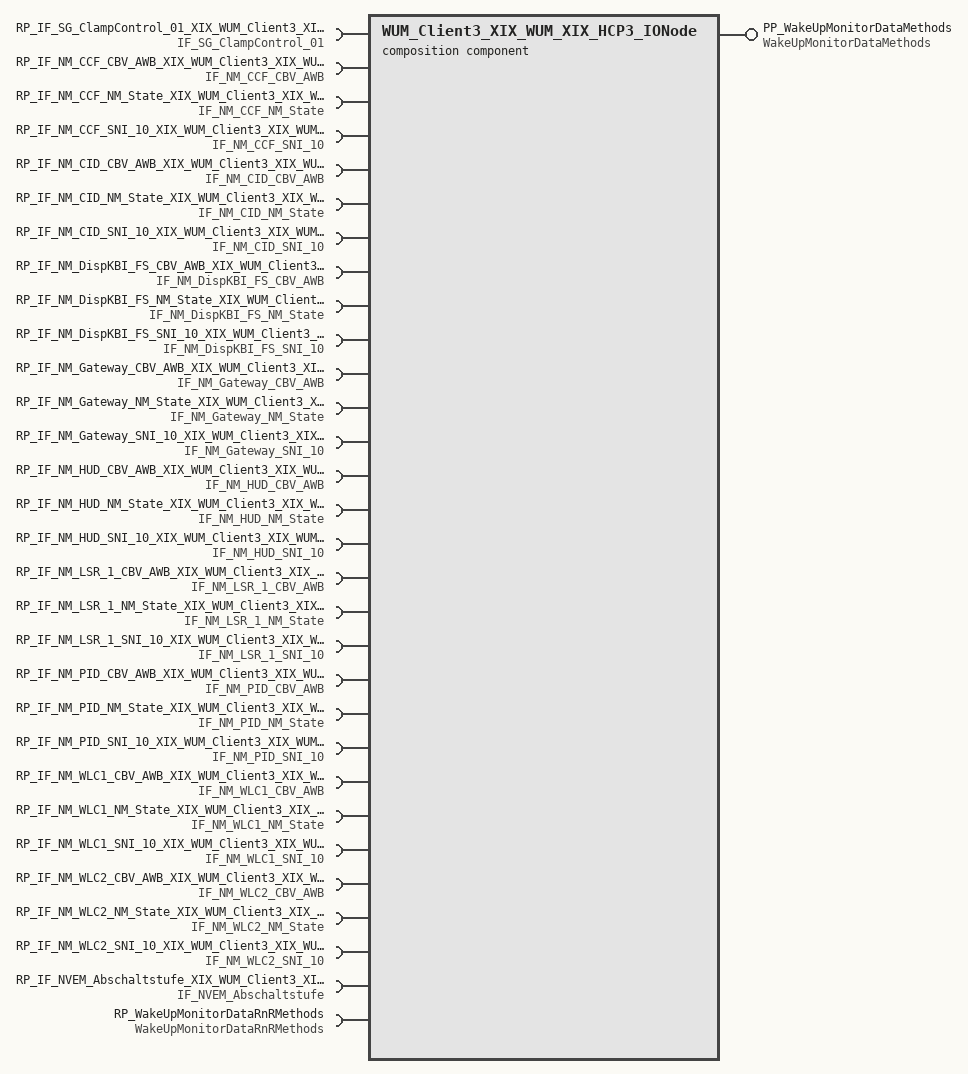
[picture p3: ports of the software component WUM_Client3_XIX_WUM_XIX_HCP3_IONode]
  composition sw component type WUM_Client3_XIX_WUM_XIX_HCP3_IONode
    provide port PP_WakeUpMonitorDataMethods: provided-interface=WakeUpMonitorDataMethods
    30 x require port:
      RP_IF_SG_ClampControl_01_XIX_WUM_Client3_XIX_WUM_XIX_HCP3_IONode: required-interface=IF_SG_ClampControl_01
      RP_IF_NM_CCF_CBV_AWB_XIX_WUM_Client3_XIX_WUM_XIX_HCP3_IONode: required-interface=IF_NM_CCF_CBV_AWB
      RP_IF_NM_CCF_NM_State_XIX_WUM_Client3_XIX_WUM_XIX_HCP3_IONode: required-interface=IF_NM_CCF_NM_State
      RP_IF_NM_CCF_SNI_10_XIX_WUM_Client3_XIX_WUM_XIX_HCP3_IONode: required-interface=IF_NM_CCF_SNI_10
      RP_IF_NM_CID_CBV_AWB_XIX_WUM_Client3_XIX_WUM_XIX_HCP3_IONode: required-interface=IF_NM_CID_CBV_AWB
      RP_IF_NM_CID_NM_State_XIX_WUM_Client3_XIX_WUM_XIX_HCP3_IONode: required-interface=IF_NM_CID_NM_State
      RP_IF_NM_CID_SNI_10_XIX_WUM_Client3_XIX_WUM_XIX_HCP3_IONode: required-interface=IF_NM_CID_SNI_10
      RP_IF_NM_DispKBI_FS_CBV_AWB_XIX_WUM_Client3_XIX_WUM_XIX_HCP3_IONode: required-interface=IF_NM_DispKBI_FS_CBV_AWB
      RP_IF_NM_DispKBI_FS_NM_State_XIX_WUM_Client3_XIX_WUM_XIX_HCP3_IONode: required-interface=IF_NM_DispKBI_FS_NM_State
      RP_IF_NM_DispKBI_FS_SNI_10_XIX_WUM_Client3_XIX_WUM_XIX_HCP3_IONode: required-interface=IF_NM_DispKBI_FS_SNI_10
      RP_IF_NM_Gateway_CBV_AWB_XIX_WUM_Client3_XIX_WUM_XIX_HCP3_IONode: required-interface=IF_NM_Gateway_CBV_AWB
      RP_IF_NM_Gateway_NM_State_XIX_WUM_Client3_XIX_WUM_XIX_HCP3_IONode: required-interface=IF_NM_Gateway_NM_State
      RP_IF_NM_Gateway_SNI_10_XIX_WUM_Client3_XIX_WUM_XIX_HCP3_IONode: required-interface=IF_NM_Gateway_SNI_10
      RP_IF_NM_HUD_CBV_AWB_XIX_WUM_Client3_XIX_WUM_XIX_HCP3_IONode: required-interface=IF_NM_HUD_CBV_AWB
      RP_IF_NM_HUD_NM_State_XIX_WUM_Client3_XIX_WUM_XIX_HCP3_IONode: required-interface=IF_NM_HUD_NM_State
      RP_IF_NM_HUD_SNI_10_XIX_WUM_Client3_XIX_WUM_XIX_HCP3_IONode: required-interface=IF_NM_HUD_SNI_10
      RP_IF_NM_LSR_1_CBV_AWB_XIX_WUM_Client3_XIX_WUM_XIX_HCP3_IONode: required-interface=IF_NM_LSR_1_CBV_AWB
      RP_IF_NM_LSR_1_NM_State_XIX_WUM_Client3_XIX_WUM_XIX_HCP3_IONode: required-interface=IF_NM_LSR_1_NM_State
      RP_IF_NM_LSR_1_SNI_10_XIX_WUM_Client3_XIX_WUM_XIX_HCP3_IONode: required-interface=IF_NM_LSR_1_SNI_10
      RP_IF_NM_PID_CBV_AWB_XIX_WUM_Client3_XIX_WUM_XIX_HCP3_IONode: required-interface=IF_NM_PID_CBV_AWB
      RP_IF_NM_PID_NM_State_XIX_WUM_Client3_XIX_WUM_XIX_HCP3_IONode: required-interface=IF_NM_PID_NM_State
      RP_IF_NM_PID_SNI_10_XIX_WUM_Client3_XIX_WUM_XIX_HCP3_IONode: required-interface=IF_NM_PID_SNI_10
      RP_IF_NM_WLC1_CBV_AWB_XIX_WUM_Client3_XIX_WUM_XIX_HCP3_IONode: required-interface=IF_NM_WLC1_CBV_AWB
      RP_IF_NM_WLC1_NM_State_XIX_WUM_Client3_XIX_WUM_XIX_HCP3_IONode: required-interface=IF_NM_WLC1_NM_State
      RP_IF_NM_WLC1_SNI_10_XIX_WUM_Client3_XIX_WUM_XIX_HCP3_IONode: required-interface=IF_NM_WLC1_SNI_10
      RP_IF_NM_WLC2_CBV_AWB_XIX_WUM_Client3_XIX_WUM_XIX_HCP3_IONode: required-interface=IF_NM_WLC2_CBV_AWB
      RP_IF_NM_WLC2_NM_State_XIX_WUM_Client3_XIX_WUM_XIX_HCP3_IONode: required-interface=IF_NM_WLC2_NM_State
      RP_IF_NM_WLC2_SNI_10_XIX_WUM_Client3_XIX_WUM_XIX_HCP3_IONode: required-interface=IF_NM_WLC2_SNI_10
      RP_IF_NVEM_Abschaltstufe_XIX_WUM_Client3_XIX_WUM_XIX_HCP3_IONode: required-interface=IF_NVEM_Abschaltstufe
      RP_WakeUpMonitorDataRnRMethods: required-interface=WakeUpMonitorDataRnRMethods
package /AUTOSAR_PlatformTypes/DataConstraints
  range DataConstr_sint8: phys -128..127, raw -128..127
  range DataConstr_sint16: phys -32768..32767, raw -32768..32767
  range DataConstr_sint32: phys -2147483648..2147483647, raw -2147483648..2147483647
  range DataConstr_sint64: phys -9223372036854775808..9223372036854775807, raw -9223372036854775808..9223372036854775807
  range DataConstr_uint8: phys 0..255, raw 0..255
  range DataConstr_uint16: phys 0..65535, raw 0..65535
  range DataConstr_uint32: phys 0..4294967295, raw 0..4294967295
  range DataConstr_uint64: phys 0..18446744073709551615, raw 0..18446744073709551615
package /vwg/common/datatypes
  app type booleanApp: category=BOOLEAN, compu {0=false (CompuMethod_boolean_false), 1=true (CompuMethod_boolean_true)}, range raw 0..1
  base type string: category=FIXED_LENGTH, base-type-size=8, base-type-encoding=UTF-8
  sw record layout StringDescriptor: sw-record-layout-group={short-label=StringDescriptorGroup, sw-record-layout-v={short-label=size, sw-record-layout-v-axis=STRING, sw-record-layout-v-prop=COUNT}, sw-record-layout-group={short-label=chars, sw-record-layout-group-axis=STRING, sw-record-layout-group-from=0, sw-record-layout-group-to=-1, sw-record-layout-v={short-label=char, sw-record-layout-v-prop=VALUE}}}
package /vwg/common/deployment
  data type mapping set CommonMappings: data-type-map{application-data-type=booleanApp, implementation-data-type=boolean}
package /vwg/services/WakeupclusterConfiguration/datatypes
  compu method AT_OperationStatusCM: 0=Cx0_success (AT_OperationStatusCM_Cx0_success), 202=Cxca_accepted (AT_OperationStatusCM_Cxca_accepted), 300=Cx12c_multiple_choice (AT_OperationStatusCM_Cx12c_multiple_choice), 304=Cx130_not_modified (AT_OperationStatusCM_Cx130_not_modified), 401=Cx191_unauthorized (AT_OperationStatusCM_Cx191_unauthorized), 403=Cx193_forbidden (AT_OperationStatusCM_Cx193_forbidden), 404=Cx194_not_found (AT_OperationStatusCM_Cx194_not_found), 408=Cx198_request_time_out (AT_OperationStatusCM_Cx198_request_time_out), 409=Cx199_conflict (AT_OperationStatusCM_Cx199_conflict), 414=Cx19e_request_too_large (AT_OperationStatusCM_Cx19e_request_too_large), 429=Cx1ad_too_many_requests (AT_OperationStatusCM_Cx1ad_too_many_requests), 431=Cx1af_request_header_fields_too_large (AT_OperationStatusCM_Cx1af_request_header_fields_too_large), 451=Cx1c3_unavailable_for_legal_reasons (AT_OperationStatusCM_Cx1c3_unavailable_for_legal_reasons), 500=Cx1f4_internal_server_error (AT_OperationStatusCM_Cx1f4_internal_server_error), 503=Cx1f7_service_unavailable (AT_OperationStatusCM_Cx1f7_service_unavailable), 504=Cx1f8_gateway_time_out (AT_OperationStatusCM_Cx1f8_gateway_time_out), 511=Cx1ff_network_authentication_required (AT_OperationStatusCM_Cx1ff_network_authentication_required), 65534=Cxfffe_operation_timeout (AT_OperationStatusCM_Cxfffe_operation_timeout), 65535=Cxffff_protocol_error (AT_OperationStatusCM_Cxffff_protocol_error)
  compu method AT_SubscriptionStatusCM: 0=Cx0_accepted (AT_SubscriptionStatusCM_Cx0_accepted), 1=Cx1_running (AT_SubscriptionStatusCM_Cx1_running), 2=Cx2_cancelled (AT_SubscriptionStatusCM_Cx2_cancelled), 3=Cx3_target_deleted (AT_SubscriptionStatusCM_Cx3_target_deleted), 65534=Cxfffe_subscription_timeout (AT_SubscriptionStatusCM_Cxfffe_subscription_timeout), 65535=Cxffff_subscription_error (AT_SubscriptionStatusCM_Cxffff_subscription_error)
  compu method AT_SubscriptionTypeCM: 0=Cx0_singleUpdate (AT_SubscriptionTypeCM_Cx0_singleUpdate), 1=Cx1_singleInitialEvent (AT_SubscriptionTypeCM_Cx1_singleInitialEvent), 2=Cx2_resourceFullUpdate (AT_SubscriptionTypeCM_Cx2_resourceFullUpdate), 3=Cx3_resourceInitialEvent (AT_SubscriptionTypeCM_Cx3_resourceInitialEvent)
  compu method AT_vnsmInstancesCM: 0=Cx0_vnsmHcp1 (AT_vnsmInstancesCM_Cx0_vnsmHcp1), 1=Cx1_vnsmHcp21 (AT_vnsmInstancesCM_Cx1_vnsmHcp21), 2=Cx2_vnsmHcp22 (AT_vnsmInstancesCM_Cx2_vnsmHcp22), 3=Cx3_vnsmHcp3 (AT_vnsmInstancesCM_Cx3_vnsmHcp3), 4=Cx4_vnsmHcp4 (AT_vnsmInstancesCM_Cx4_vnsmHcp4), 5=Cx5_vnsmHcp5 (AT_vnsmInstancesCM_Cx5_vnsmHcp5)
  22 x impl type:
    AT_ConfigurationsCreate: category=STRUCTURE
      element vnsmInstance: implementation-data-type=AT_vnsmInstances
      element pncVector: implementation-data-type=AT_PncVectorType
      symbol props SymbolProps: symbol=WakeupclusterConfiguration_AT_ConfigurationsCreate
    AT_ConfigurationsCreateResponse: category=STRUCTURE
      element availabilityBitfield: category=ARRAY, array-size-semantics=FIXED-SIZE
        element availabilityBitfieldArrayType: array-size=1, implementation-data-type=uint8
      element status: implementation-data-type=AT_OperationStatus
      element key: implementation-data-type=AT_vnsmInstances
      symbol props SymbolProps: symbol=WakeupclusterConfiguration_AT_ConfigurationsCreateResponse
    AT_ConfigurationsEvent: category=STRUCTURE
      8 x element, all with category=TYPE_REFERENCE:
        subscriptionId: implementation-data-type=ConfigurationsEvent_subscriptionId_type
        updateCounter: implementation-data-type=ConfigurationsEvent_updateCounter_type
        totalNoOfMessages: implementation-data-type=ConfigurationsEvent_totalNoOfMessages_type
        eventMessageCounter: implementation-data-type=ConfigurationsEvent_eventMessageCounter_type
        noOfResourceElements: implementation-data-type=ConfigurationsEvent_noOfResourceElements_type
        type: implementation-data-type=AT_SubscriptionType
        subscriptionStatus: implementation-data-type=AT_SubscriptionStatus
        element: implementation-data-type=AT_reconfigurationType
      symbol props SymbolProps: symbol=WakeupclusterConfiguration_AT_ConfigurationsEvent
    AT_ConfigurationsResponse: category=STRUCTURE
      element status: implementation-data-type=AT_OperationStatus
      element listconfigurations: implementation-data-type=AT_ConfigurationsVector
      symbol props SymbolProps: symbol=WakeupclusterConfiguration_AT_ConfigurationsResponse
    AT_ConfigurationsSet: category=STRUCTURE
      element availabilityBitfield: category=ARRAY, array-size-semantics=FIXED-SIZE
        element availabilityBitfieldArrayType: array-size=1, implementation-data-type=uint8
      element pncVector: implementation-data-type=AT_PncVectorType
      symbol props SymbolProps: symbol=WakeupclusterConfiguration_AT_ConfigurationsSet
    AT_ConfigurationsVector: category=STRUCTURE, dynamic-array-size-profile=VSA_LINEAR
      element size: implementation-data-type=uint8
      element payload: category=ARRAY
        element AT_reconfigurationType: array-size=6, array-size-handling=ALL-INDICES-SAME-ARRAY-SIZE, array-size-semantics=VARIABLE-SIZE, implementation-data-type=AT_reconfigurationType
      symbol props SymbolProps: symbol=WakeupclusterConfiguration_AT_ConfigurationsVector
    AT_OperationStatus: compu-method=AT_OperationStatusCM, range raw 0..65535, implementation-data-type=uint16
      symbol props SymbolProps: symbol=WakeupclusterConfiguration_AT_OperationStatus
    AT_PncVectorType: category=STRUCTURE
      48 x element, all with category=TYPE_REFERENCE, implementation-data-type=boolean:
        carWakeUp
        basefunctionPowertrain
        basefunctionChassis
        basefunctionDrivingAssistance
        basefunctionInfotainment
        basefunctionComfortLight
        basefunctionCrossSection
        basefunctionConnectivity
        powertrain
        chassis
        gearSelector
        airbag
        infotainmentExtensions
        instrumentclusterDisplay
        infotainmentDisplay
        audio
        virtualSideMirrors
        doorsAndHatches
        optionalComfort
        airSuspension
        exteriorLights
        climate
        thermoManagement
        accessSystemSensors
        highVoltageAndCharging
        timemasterAndTimer
        onBoardTesterAndDataCollector
        steeringColumnLock
        energyManagement
        multifunctionalSteeringWheel
        onlineAccess
        externalWirelessCommunication
        gpsLocalization
        exteriorSound
        preheater
        highVoltageWirelessChargingStation
        diagnosisEnergy
        diagnosisPowertrain
        diagnosisFlexRay
        diagnosisDrivingAssistance
        diagnosisInfotainment
        diagnosisComfort
        diagnosisLight
        diagnosisComfortLINs
        diagnosisClimateTmeLINs
        lockAndUnlock
        dimming
        chargingStatus
      symbol props SymbolProps: symbol=WakeupclusterConfiguration_AT_PncVectorType
    AT_SubscriptionStatus: compu-method=AT_SubscriptionStatusCM, range raw 0..65535, implementation-data-type=uint16
      symbol props SymbolProps: symbol=WakeupclusterConfiguration_AT_SubscriptionStatus
    AT_SubscriptionType: compu-method=AT_SubscriptionTypeCM, range raw 0..3, implementation-data-type=uint8
      symbol props SymbolProps: symbol=WakeupclusterConfiguration_AT_SubscriptionType
    AT_WakeupclusterConfigurationSubscriptionResponse: category=STRUCTURE
      element subscriptionId: implementation-data-type=WakeupclusterConfigurationSubscriptionResponse_subscriptionId_type
      element status: implementation-data-type=AT_SubscriptionStatus
      symbol props SymbolProps: symbol=WakeupclusterConfiguration_AT_WakeupclusterConfigurationSubscriptionResponse
    AT_configurationsResponseSingle: category=STRUCTURE
      element status: implementation-data-type=AT_OperationStatus
      element element: implementation-data-type=AT_reconfigurationType
      symbol props SymbolProps: symbol=WakeupclusterConfiguration_AT_configurationsResponseSingle
    AT_reconfigurationType: category=STRUCTURE
      element vnsmInstance: implementation-data-type=AT_vnsmInstances
      element pncVector: implementation-data-type=AT_PncVectorType
      symbol props SymbolProps: symbol=WakeupclusterConfiguration_AT_reconfigurationType
    AT_vnsmInstances: compu-method=AT_vnsmInstancesCM, range raw 0..5, implementation-data-type=uint8
      symbol props SymbolProps: symbol=WakeupclusterConfiguration_AT_vnsmInstances
    ConfigurationsEvent_eventMessageCounter_type: range phys 0..65535, raw 0..65535, implementation-data-type=uint16
      symbol props SymbolProps: symbol=WakeupclusterConfiguration_ConfigurationsEvent_eventMessageCounter_type
    ConfigurationsEvent_noOfResourceElements_type: range phys 0..65535, raw 0..65535, implementation-data-type=uint16
      symbol props SymbolProps: symbol=WakeupclusterConfiguration_ConfigurationsEvent_noOfResourceElements_type
    ConfigurationsEvent_subscriptionId_type: range phys 0..4294967295, raw 0..4294967295, implementation-data-type=uint32
      symbol props SymbolProps: symbol=WakeupclusterConfiguration_ConfigurationsEvent_subscriptionId_type
    ConfigurationsEvent_totalNoOfMessages_type: range phys 0..65535, raw 0..65535, implementation-data-type=uint16
      symbol props SymbolProps: symbol=WakeupclusterConfiguration_ConfigurationsEvent_totalNoOfMessages_type
    ConfigurationsEvent_updateCounter_type: range phys 0..4294967295, raw 0..4294967295, implementation-data-type=uint32
      symbol props SymbolProps: symbol=WakeupclusterConfiguration_ConfigurationsEvent_updateCounter_type
    UUIDApp: category=ARRAY
      element UUIDAppBase: array-size=16, array-size-semantics=FIXED-SIZE, implementation-data-type=uint8
      symbol props SymbolProps: symbol=WakeupclusterConfiguration_UUIDApp
    WakeupclusterConfigurationSubscriptionResponse_subscriptionId_type: range phys 0..4294967295, raw 0..4294967295, implementation-data-type=uint32
      symbol props SymbolProps: symbol=WakeupclusterConfiguration_WakeupclusterConfigurationSubscriptionResponse_subscriptionId_type
    unsubscribeConfigurations_subscriptionId_type: range phys 0..4294967295, raw 0..4294967295, implementation-data-type=uint32
      symbol props SymbolProps: symbol=WakeupclusterConfiguration_unsubscribeConfigurations_subscriptionId_type
  application array data type AT_ConfigurationsVectorApp: category=ARRAY, dynamic-array-size-profile=VSA_LINEAR
    element AT_reconfigurationType: category=VALUE, type=AT_reconfigurationTypeApp, array-size-handling=ALL-INDICES-SAME-ARRAY-SIZE, array-size-semantics=VARIABLE-SIZE, max-number-of-elements=6
  application array data type UUIDAppApp: category=ARRAY
    element uint8: category=VALUE, type=uint8App, array-size-semantics=FIXED-SIZE, max-number-of-elements=16
  12 x app type, all with category=VALUE:
    AT_OperationStatusApp: compu-method=AT_OperationStatusCM, range raw 0..65535
    AT_SubscriptionStatusApp: compu-method=AT_SubscriptionStatusCM, range raw 0..65535
    AT_SubscriptionTypeApp: compu-method=AT_SubscriptionTypeCM, range raw 0..3
    AT_vnsmInstancesApp: compu-method=AT_vnsmInstancesCM, range raw 0..5
    ConfigurationsEvent_eventMessageCounter_typeApp: compu {identical}, range phys 0..65535, raw 0..65535
    ConfigurationsEvent_noOfResourceElements_typeApp: compu {identical}, range phys 0..65535, raw 0..65535
    ConfigurationsEvent_subscriptionId_typeApp: compu {identical}, range phys 0..4294967295, raw 0..4294967295
    ConfigurationsEvent_totalNoOfMessages_typeApp: compu {identical}, range phys 0..65535, raw 0..65535
    ConfigurationsEvent_updateCounter_typeApp: compu {identical}, range phys 0..4294967295, raw 0..4294967295
    uint8App
    unsubscribeConfigurations_subscriptionId_typeApp: compu {identical}, range phys 0..4294967295, raw 0..4294967295
    WakeupclusterConfigurationSubscriptionResponse_subscriptionId_typeApp: compu {identical}, range phys 0..4294967295, raw 0..4294967295
  9 x application record data type, all with category=STRUCTURE:
    AT_ConfigurationsCreateApp
      application record element vnsmInstance: category=VALUE, type=AT_vnsmInstancesApp
      application record element pncVector: category=STRUCTURE, type=AT_PncVectorTypeApp
    AT_ConfigurationsCreateResponseApp
      application record element status: category=VALUE, type=AT_OperationStatusApp
      application record element key: category=VALUE, type=AT_vnsmInstancesApp
    AT_ConfigurationsEventApp
      8 x application record element:
        subscriptionId: category=VALUE, type=ConfigurationsEvent_subscriptionId_typeApp
        updateCounter: category=VALUE, type=ConfigurationsEvent_updateCounter_typeApp
        totalNoOfMessages: category=VALUE, type=ConfigurationsEvent_totalNoOfMessages_typeApp
        eventMessageCounter: category=VALUE, type=ConfigurationsEvent_eventMessageCounter_typeApp
        noOfResourceElements: category=VALUE, type=ConfigurationsEvent_noOfResourceElements_typeApp
        type: category=VALUE, type=AT_SubscriptionTypeApp
        subscriptionStatus: category=VALUE, type=AT_SubscriptionStatusApp
        element: category=STRUCTURE, type=AT_reconfigurationTypeApp
    AT_ConfigurationsResponseApp
      application record element status: category=VALUE, type=AT_OperationStatusApp
      application record element listconfigurations: category=ARRAY, type=AT_ConfigurationsVectorApp
    AT_configurationsResponseSingleApp
      application record element status: category=VALUE, type=AT_OperationStatusApp
      application record element element: category=STRUCTURE, type=AT_reconfigurationTypeApp
    AT_ConfigurationsSetApp
      application record element pncVector: category=STRUCTURE, type=AT_PncVectorTypeApp
    AT_PncVectorTypeApp
      48 x application record element, all with category=BOOLEAN, type=booleanApp:
        carWakeUp
        basefunctionPowertrain
        basefunctionChassis
        basefunctionDrivingAssistance
        basefunctionInfotainment
        basefunctionComfortLight
        basefunctionCrossSection
        basefunctionConnectivity
        powertrain
        chassis
        gearSelector
        airbag
        infotainmentExtensions
        instrumentclusterDisplay
        infotainmentDisplay
        audio
        virtualSideMirrors
        doorsAndHatches
        optionalComfort
        airSuspension
        exteriorLights
        climate
        thermoManagement
        accessSystemSensors
        highVoltageAndCharging
        timemasterAndTimer
        onBoardTesterAndDataCollector
        steeringColumnLock
        energyManagement
        multifunctionalSteeringWheel
        onlineAccess
        externalWirelessCommunication
        gpsLocalization
        exteriorSound
        preheater
        highVoltageWirelessChargingStation
        diagnosisEnergy
        diagnosisPowertrain
        diagnosisFlexRay
        diagnosisDrivingAssistance
        diagnosisInfotainment
        diagnosisComfort
        diagnosisLight
        diagnosisComfortLINs
        diagnosisClimateTmeLINs
        lockAndUnlock
        dimming
        chargingStatus
    AT_reconfigurationTypeApp
      application record element vnsmInstance: category=VALUE, type=AT_vnsmInstancesApp
      application record element pncVector: category=STRUCTURE, type=AT_PncVectorTypeApp
    AT_WakeupclusterConfigurationSubscriptionResponseApp
      application record element subscriptionId: category=VALUE, type=WakeupclusterConfigurationSubscriptionResponse_subscriptionId_typeApp
      application record element status: category=VALUE, type=AT_SubscriptionStatusApp
package /vwg/services/WakeupclusterConfiguration/deployment
  data type mapping set WakeupclusterConfigurationMappings
    data-type-maps:
      application-data-type=AT_ConfigurationsVectorApp, implementation-data-type=AT_ConfigurationsVector
      application-data-type=UUIDAppApp, implementation-data-type=UUIDApp
      application-data-type=AT_OperationStatusApp, implementation-data-type=AT_OperationStatus
      application-data-type=AT_SubscriptionStatusApp, implementation-data-type=AT_SubscriptionStatus
      application-data-type=AT_SubscriptionTypeApp, implementation-data-type=AT_SubscriptionType
      application-data-type=AT_vnsmInstancesApp, implementation-data-type=AT_vnsmInstances
      application-data-type=ConfigurationsEvent_eventMessageCounter_typeApp, implementation-data-type=ConfigurationsEvent_eventMessageCounter_type
      application-data-type=ConfigurationsEvent_noOfResourceElements_typeApp, implementation-data-type=ConfigurationsEvent_noOfResourceElements_type
      application-data-type=ConfigurationsEvent_subscriptionId_typeApp, implementation-data-type=ConfigurationsEvent_subscriptionId_type
      application-data-type=ConfigurationsEvent_totalNoOfMessages_typeApp, implementation-data-type=ConfigurationsEvent_totalNoOfMessages_type
      application-data-type=ConfigurationsEvent_updateCounter_typeApp, implementation-data-type=ConfigurationsEvent_updateCounter_type
      application-data-type=uint8App, implementation-data-type=uint8
      application-data-type=unsubscribeConfigurations_subscriptionId_typeApp, implementation-data-type=unsubscribeConfigurations_subscriptionId_type
      application-data-type=WakeupclusterConfigurationSubscriptionResponse_subscriptionId_typeApp, implementation-data-type=WakeupclusterConfigurationSubscriptionResponse_subscriptionId_type
      application-data-type=AT_ConfigurationsCreateApp, implementation-data-type=AT_ConfigurationsCreate
      application-data-type=AT_ConfigurationsCreateResponseApp, implementation-data-type=AT_ConfigurationsCreateResponse
      application-data-type=AT_ConfigurationsEventApp, implementation-data-type=AT_ConfigurationsEvent
      application-data-type=AT_ConfigurationsResponseApp, implementation-data-type=AT_ConfigurationsResponse
      application-data-type=AT_configurationsResponseSingleApp, implementation-data-type=AT_configurationsResponseSingle
      application-data-type=AT_ConfigurationsSetApp, implementation-data-type=AT_ConfigurationsSet
      application-data-type=AT_PncVectorTypeApp, implementation-data-type=AT_PncVectorType
      application-data-type=AT_reconfigurationTypeApp, implementation-data-type=AT_reconfigurationType
      application-data-type=AT_WakeupclusterConfigurationSubscriptionResponseApp, implementation-data-type=AT_WakeupclusterConfigurationSubscriptionResponse
package /vwg/services/WakeUpMonitorData/datatypes
  38 x impl type:
    AT_BusActiveTimes: category=STRUCTURE
      4 x element, all with category=TYPE_REFERENCE:
        totalNumberOfEntries: implementation-data-type=BusActiveTimes_totalNumberOfEntries_type
        busIdentifier: implementation-data-type=BusActiveTimes_busIdentifier_type
        totalBusActiveTime: implementation-data-type=BusActiveTimes_totalBusActiveTime_type
        totalWakeUpCounts: implementation-data-type=BusActiveTimes_totalWakeUpCounts_type
      symbol props SymbolProps: symbol=WakeUpMonitorData_AT_BusActiveTimes
    AT_ConfigurationTable: category=STRUCTURE
      10 x element, all with category=TYPE_REFERENCE:
        wakeUpMasterCycleCount: implementation-data-type=ConfigurationTable_wakeUpMasterCycleCount_type
        activationWakeUpMonitorAll: implementation-data-type=boolean
        activationBusactivityMonitor: implementation-data-type=boolean
        activationNetworkManagementKeepAliveMonitor: implementation-data-type=boolean
        activationNetworkManagementWakeUpsMonitor: implementation-data-type=boolean
        activationHostComActivityMonitor: implementation-data-type=boolean
        activationHostLocalActivityMonitor: implementation-data-type=boolean
        activationSystemfunctionActivityMonitor: implementation-data-type=boolean
        startDelay: implementation-data-type=ConfigurationTable_startDelay_type
        wakeDelay: implementation-data-type=ConfigurationTable_wakeDelay_type
      symbol props SymbolProps: symbol=WakeUpMonitorData_AT_ConfigurationTable
    AT_HostCommunicationActiveTimes: category=STRUCTURE
      4 x element, all with category=TYPE_REFERENCE:
        totalNumberOfEntries: implementation-data-type=HostCommunicationActiveTimes_totalNumberOfEntries_type
        userNumber: implementation-data-type=HostCommunicationActiveTimes_userNumber_type
        keepAliveTime: implementation-data-type=HostCommunicationActiveTimes_keepAliveTime_type
        wakeUpCount: implementation-data-type=HostCommunicationActiveTimes_wakeUpCount_type
      symbol props SymbolProps: symbol=WakeUpMonitorData_AT_HostCommunicationActiveTimes
    AT_HostLocalActiveTimes: category=STRUCTURE
      element totalNumberOfEntries: implementation-data-type=HostLocalActiveTimes_totalNumberOfEntries_type
      element userNumber: implementation-data-type=HostLocalActiveTimes_userNumber_type
      element keepAliveTime: implementation-data-type=HostLocalActiveTimes_keepAliveTime_type
      symbol props SymbolProps: symbol=WakeUpMonitorData_AT_HostLocalActiveTimes
    AT_NetworkManagementActiveTimes: category=STRUCTURE
      5 x element, all with category=TYPE_REFERENCE:
        totalNumberOfEntries: implementation-data-type=NetworkManagementActiveTimes_totalNumberOfEntries_type
        sourceNodeIdentifier: implementation-data-type=NetworkManagementActiveTimes_sourceNodeIdentifier_type
        busIdentifier: implementation-data-type=NetworkManagementActiveTimes_busIdentifier_type
        keepAliveTime: implementation-data-type=NetworkManagementActiveTimes_keepAliveTime_type
        wakeUpCount: implementation-data-type=NetworkManagementActiveTimes_wakeUpCount_type
      symbol props SymbolProps: symbol=WakeUpMonitorData_AT_NetworkManagementActiveTimes
    AT_SystemFunctionActiveTimes: category=STRUCTURE
      element totalNumberOfEntries: implementation-data-type=SystemFunctionActiveTimes_totalNumberOfEntries_type
      element functionIdentifier: implementation-data-type=SystemFunctionActiveTimes_functionIdentifier_type
      element activeTime: implementation-data-type=SystemFunctionActiveTimes_activeTime_type
      symbol props SymbolProps: symbol=WakeUpMonitorData_AT_SystemFunctionActiveTimes
    BusActiveTimes_busIdentifier_type: range phys 0..255, raw 0..255, implementation-data-type=uint8
      symbol props SymbolProps: symbol=WakeUpMonitorData_BusActiveTimes_busIdentifier_type
    BusActiveTimes_totalBusActiveTime_type: range phys 0..255, raw 0..255, implementation-data-type=uint8
      symbol props SymbolProps: symbol=WakeUpMonitorData_BusActiveTimes_totalBusActiveTime_type
    BusActiveTimes_totalNumberOfEntries_type: range phys 0..255, raw 0..255, implementation-data-type=uint8
      symbol props SymbolProps: symbol=WakeUpMonitorData_BusActiveTimes_totalNumberOfEntries_type
    BusActiveTimes_totalWakeUpCounts_type: range phys 0..255, raw 0..255, implementation-data-type=uint8
      symbol props SymbolProps: symbol=WakeUpMonitorData_BusActiveTimes_totalWakeUpCounts_type
    ConfigurationTable_startDelay_type: range phys 0..255, raw 0..255, implementation-data-type=uint8
      symbol props SymbolProps: symbol=WakeUpMonitorData_ConfigurationTable_startDelay_type
    ConfigurationTable_wakeDelay_type: range phys 0..255, raw 0..255, implementation-data-type=uint8
      symbol props SymbolProps: symbol=WakeUpMonitorData_ConfigurationTable_wakeDelay_type
    ConfigurationTable_wakeUpMasterCycleCount_type: range phys 0..4294967295, raw 0..4294967295, implementation-data-type=uint32
      symbol props SymbolProps: symbol=WakeUpMonitorData_ConfigurationTable_wakeUpMasterCycleCount_type
    HostCommunicationActiveTimes_keepAliveTime_type: range phys 0..255, raw 0..255, implementation-data-type=uint8
      symbol props SymbolProps: symbol=WakeUpMonitorData_HostCommunicationActiveTimes_keepAliveTime_type
    HostCommunicationActiveTimes_totalNumberOfEntries_type: range phys 0..255, raw 0..255, implementation-data-type=uint8
      symbol props SymbolProps: symbol=WakeUpMonitorData_HostCommunicationActiveTimes_totalNumberOfEntries_type
    HostCommunicationActiveTimes_userNumber_type: range phys 0..255, raw 0..255, implementation-data-type=uint8
      symbol props SymbolProps: symbol=WakeUpMonitorData_HostCommunicationActiveTimes_userNumber_type
    HostCommunicationActiveTimes_wakeUpCount_type: range phys 0..255, raw 0..255, implementation-data-type=uint8
      symbol props SymbolProps: symbol=WakeUpMonitorData_HostCommunicationActiveTimes_wakeUpCount_type
    HostLocalActiveTimes_keepAliveTime_type: range phys 0..255, raw 0..255, implementation-data-type=uint8
      symbol props SymbolProps: symbol=WakeUpMonitorData_HostLocalActiveTimes_keepAliveTime_type
    HostLocalActiveTimes_totalNumberOfEntries_type: range phys 0..255, raw 0..255, implementation-data-type=uint8
      symbol props SymbolProps: symbol=WakeUpMonitorData_HostLocalActiveTimes_totalNumberOfEntries_type
    HostLocalActiveTimes_userNumber_type: range phys 0..255, raw 0..255, implementation-data-type=uint8
      symbol props SymbolProps: symbol=WakeUpMonitorData_HostLocalActiveTimes_userNumber_type
    NetworkManagementActiveTimes_busIdentifier_type: range phys 0..255, raw 0..255, implementation-data-type=uint8
      symbol props SymbolProps: symbol=WakeUpMonitorData_NetworkManagementActiveTimes_busIdentifier_type
    NetworkManagementActiveTimes_keepAliveTime_type: range phys 0..255, raw 0..255, implementation-data-type=uint8
      symbol props SymbolProps: symbol=WakeUpMonitorData_NetworkManagementActiveTimes_keepAliveTime_type
    NetworkManagementActiveTimes_sourceNodeIdentifier_type: range phys 0..65535, raw 0..65535, implementation-data-type=uint16
      symbol props SymbolProps: symbol=WakeUpMonitorData_NetworkManagementActiveTimes_sourceNodeIdentifier_type
    NetworkManagementActiveTimes_totalNumberOfEntries_type: range phys 0..255, raw 0..255, implementation-data-type=uint8
      symbol props SymbolProps: symbol=WakeUpMonitorData_NetworkManagementActiveTimes_totalNumberOfEntries_type
    NetworkManagementActiveTimes_wakeUpCount_type: range phys 0..255, raw 0..255, implementation-data-type=uint8
      symbol props SymbolProps: symbol=WakeUpMonitorData_NetworkManagementActiveTimes_wakeUpCount_type
    SystemFunctionActiveTimes_activeTime_type: range phys 0..255, raw 0..255, implementation-data-type=uint8
      symbol props SymbolProps: symbol=WakeUpMonitorData_SystemFunctionActiveTimes_activeTime_type
    SystemFunctionActiveTimes_functionIdentifier_type: range phys 0..255, raw 0..255, implementation-data-type=uint8
      symbol props SymbolProps: symbol=WakeUpMonitorData_SystemFunctionActiveTimes_functionIdentifier_type
    SystemFunctionActiveTimes_totalNumberOfEntries_type: range phys 0..255, raw 0..255, implementation-data-type=uint8
      symbol props SymbolProps: symbol=WakeUpMonitorData_SystemFunctionActiveTimes_totalNumberOfEntries_type
    WakeUpMonitorData_UUIDApp: category=ARRAY
      element UUIDAppBase: array-size=16, array-size-semantics=FIXED-SIZE, implementation-data-type=uint8
      symbol props SymbolProps: symbol=WakeUpMonitorData_UUIDApp
    getTable_busActiveTimes: category=STRUCTURE, dynamic-array-size-profile=VSA_LINEAR
      element size: implementation-data-type=uint8
      element payload: category=ARRAY
        element AT_BusActiveTimes: array-size=5, array-size-handling=ALL-INDICES-SAME-ARRAY-SIZE, array-size-semantics=VARIABLE-SIZE, implementation-data-type=AT_BusActiveTimes
      symbol props SymbolProps: symbol=WakeUpMonitorData_getTable_busActiveTimes
    getTable_cycleCounterAcknowledgement_type: range phys 0..4294967295, raw 0..4294967295, implementation-data-type=uint32
      symbol props SymbolProps: symbol=WakeUpMonitorData_getTable_cycleCounterAcknowledgement_type
    getTable_cycleCounterRequested_type: range phys 0..4294967295, raw 0..4294967295, implementation-data-type=uint32
      symbol props SymbolProps: symbol=WakeUpMonitorData_getTable_cycleCounterRequested_type
    getTable_hostCommunicationActiveTimes: category=STRUCTURE, dynamic-array-size-profile=VSA_LINEAR
      element size: implementation-data-type=uint8
      element payload: category=ARRAY
        element AT_HostCommunicationActiveTimes: array-size=5, array-size-handling=ALL-INDICES-SAME-ARRAY-SIZE, array-size-semantics=VARIABLE-SIZE, implementation-data-type=AT_HostCommunicationActiveTimes
      symbol props SymbolProps: symbol=WakeUpMonitorData_getTable_hostCommunicationActiveTimes
    getTable_hostLocalActiveTimes: category=STRUCTURE, dynamic-array-size-profile=VSA_LINEAR
      element size: implementation-data-type=uint8
      element payload: category=ARRAY
        element AT_HostLocalActiveTimes: array-size=5, array-size-handling=ALL-INDICES-SAME-ARRAY-SIZE, array-size-semantics=VARIABLE-SIZE, implementation-data-type=AT_HostLocalActiveTimes
      symbol props SymbolProps: symbol=WakeUpMonitorData_getTable_hostLocalActiveTimes
    getTable_networkManagementActiveTimes: category=STRUCTURE, dynamic-array-size-profile=VSA_LINEAR
      element size: implementation-data-type=uint8
      element payload: category=ARRAY
        element AT_NetworkManagementActiveTimes: array-size=5, array-size-handling=ALL-INDICES-SAME-ARRAY-SIZE, array-size-semantics=VARIABLE-SIZE, implementation-data-type=AT_NetworkManagementActiveTimes
      symbol props SymbolProps: symbol=WakeUpMonitorData_getTable_networkManagementActiveTimes
    getTable_systemfunctionActiveTimes: category=STRUCTURE, dynamic-array-size-profile=VSA_LINEAR
      element size: implementation-data-type=uint8
      element payload: category=ARRAY
        element AT_SystemFunctionActiveTimes: array-size=5, array-size-handling=ALL-INDICES-SAME-ARRAY-SIZE, array-size-semantics=VARIABLE-SIZE, implementation-data-type=AT_SystemFunctionActiveTimes
      symbol props SymbolProps: symbol=WakeUpMonitorData_getTable_systemfunctionActiveTimes
    startCycle_cycleCounterAcknowledgement_type: range phys 0..4294967295, raw 0..4294967295, implementation-data-type=uint32
      symbol props SymbolProps: symbol=WakeUpMonitorData_startCycle_cycleCounterAcknowledgement_type
    startCycle_cycleCounterRequested_type: range phys 0..4294967295, raw 0..4294967295, implementation-data-type=uint32
      symbol props SymbolProps: symbol=WakeUpMonitorData_startCycle_cycleCounterRequested_type
  6 x application array data type, all with category=ARRAY:
    getTable_busActiveTimesApp: dynamic-array-size-profile=VSA_LINEAR
      element AT_BusActiveTimes: category=VALUE, type=AT_BusActiveTimesApp, array-size-handling=ALL-INDICES-SAME-ARRAY-SIZE, array-size-semantics=VARIABLE-SIZE, max-number-of-elements=5
    getTable_hostCommunicationActiveTimesApp: dynamic-array-size-profile=VSA_LINEAR
      element AT_HostCommunicationActiveTimes: category=VALUE, type=AT_HostCommunicationActiveTimesApp, array-size-handling=ALL-INDICES-SAME-ARRAY-SIZE, array-size-semantics=VARIABLE-SIZE, max-number-of-elements=5
    getTable_hostLocalActiveTimesApp: dynamic-array-size-profile=VSA_LINEAR
      element AT_HostLocalActiveTimes: category=VALUE, type=AT_HostLocalActiveTimesApp, array-size-handling=ALL-INDICES-SAME-ARRAY-SIZE, array-size-semantics=VARIABLE-SIZE, max-number-of-elements=5
    getTable_networkManagementActiveTimesApp: dynamic-array-size-profile=VSA_LINEAR
      element AT_NetworkManagementActiveTimes: category=VALUE, type=AT_NetworkManagementActiveTimesApp, array-size-handling=ALL-INDICES-SAME-ARRAY-SIZE, array-size-semantics=VARIABLE-SIZE, max-number-of-elements=5
    getTable_systemfunctionActiveTimesApp: dynamic-array-size-profile=VSA_LINEAR
      element AT_SystemFunctionActiveTimes: category=VALUE, type=AT_SystemFunctionActiveTimesApp, array-size-handling=ALL-INDICES-SAME-ARRAY-SIZE, array-size-semantics=VARIABLE-SIZE, max-number-of-elements=5
    WakeUpMonitorData_UUIDAppApp
      element uint8: category=VALUE, type=WakeUpMonitorData_uint8App, array-size-semantics=FIXED-SIZE, max-number-of-elements=16
  27 x app type, all with category=VALUE:
    BusActiveTimes_busIdentifier_typeApp: compu {identical}, range phys 0..255, raw 0..255
    BusActiveTimes_totalBusActiveTime_typeApp: compu {identical}, range phys 0..255, raw 0..255
    BusActiveTimes_totalNumberOfEntries_typeApp: compu {identical}, range phys 0..255, raw 0..255
    BusActiveTimes_totalWakeUpCounts_typeApp: compu {identical}, range phys 0..255, raw 0..255
    ConfigurationTable_startDelay_typeApp: compu {identical}, range phys 0..255, raw 0..255
    ConfigurationTable_wakeDelay_typeApp: compu {identical}, range phys 0..255, raw 0..255
    ConfigurationTable_wakeUpMasterCycleCount_typeApp: compu {identical}, range phys 0..4294967295, raw 0..4294967295
    getTable_cycleCounterAcknowledgement_typeApp: compu {identical}, range phys 0..4294967295, raw 0..4294967295
    getTable_cycleCounterRequested_typeApp: compu {identical}, range phys 0..4294967295, raw 0..4294967295
    HostCommunicationActiveTimes_keepAliveTime_typeApp: compu {identical}, range phys 0..255, raw 0..255
    HostCommunicationActiveTimes_totalNumberOfEntries_typeApp: compu {identical}, range phys 0..255, raw 0..255
    HostCommunicationActiveTimes_userNumber_typeApp: compu {identical}, range phys 0..255, raw 0..255
    HostCommunicationActiveTimes_wakeUpCount_typeApp: compu {identical}, range phys 0..255, raw 0..255
    HostLocalActiveTimes_keepAliveTime_typeApp: compu {identical}, range phys 0..255, raw 0..255
    HostLocalActiveTimes_totalNumberOfEntries_typeApp: compu {identical}, range phys 0..255, raw 0..255
    HostLocalActiveTimes_userNumber_typeApp: compu {identical}, range phys 0..255, raw 0..255
    NetworkManagementActiveTimes_busIdentifier_typeApp: compu {identical}, range phys 0..255, raw 0..255
    NetworkManagementActiveTimes_keepAliveTime_typeApp: compu {identical}, range phys 0..255, raw 0..255
    NetworkManagementActiveTimes_sourceNodeIdentifier_typeApp: compu {identical}, range phys 0..65535, raw 0..65535
    NetworkManagementActiveTimes_totalNumberOfEntries_typeApp: compu {identical}, range phys 0..255, raw 0..255
    NetworkManagementActiveTimes_wakeUpCount_typeApp: compu {identical}, range phys 0..255, raw 0..255
    startCycle_cycleCounterAcknowledgement_typeApp: compu {identical}, range phys 0..4294967295, raw 0..4294967295
    startCycle_cycleCounterRequested_typeApp: compu {identical}, range phys 0..4294967295, raw 0..4294967295
    SystemFunctionActiveTimes_activeTime_typeApp: compu {identical}, range phys 0..255, raw 0..255
    SystemFunctionActiveTimes_functionIdentifier_typeApp: compu {identical}, range phys 0..255, raw 0..255
    SystemFunctionActiveTimes_totalNumberOfEntries_typeApp: compu {identical}, range phys 0..255, raw 0..255
    WakeUpMonitorData_uint8App
  6 x application record data type, all with category=STRUCTURE:
    AT_BusActiveTimesApp
      4 x application record element, all with category=VALUE:
        totalNumberOfEntries: type=BusActiveTimes_totalNumberOfEntries_typeApp
        busIdentifier: type=BusActiveTimes_busIdentifier_typeApp
        totalBusActiveTime: type=BusActiveTimes_totalBusActiveTime_typeApp
        totalWakeUpCounts: type=BusActiveTimes_totalWakeUpCounts_typeApp
    AT_ConfigurationTableApp
      10 x application record element:
        wakeUpMasterCycleCount: category=VALUE, type=ConfigurationTable_wakeUpMasterCycleCount_typeApp
        activationWakeUpMonitorAll: category=BOOLEAN, type=booleanApp
        activationBusactivityMonitor: category=BOOLEAN, type=booleanApp
        activationNetworkManagementKeepAliveMonitor: category=BOOLEAN, type=booleanApp
        activationNetworkManagementWakeUpsMonitor: category=BOOLEAN, type=booleanApp
        activationHostComActivityMonitor: category=BOOLEAN, type=booleanApp
        activationHostLocalActivityMonitor: category=BOOLEAN, type=booleanApp
        activationSystemfunctionActivityMonitor: category=BOOLEAN, type=booleanApp
        startDelay: category=VALUE, type=ConfigurationTable_startDelay_typeApp
        wakeDelay: category=VALUE, type=ConfigurationTable_wakeDelay_typeApp
    AT_HostCommunicationActiveTimesApp
      4 x application record element, all with category=VALUE:
        totalNumberOfEntries: type=HostCommunicationActiveTimes_totalNumberOfEntries_typeApp
        userNumber: type=HostCommunicationActiveTimes_userNumber_typeApp
        keepAliveTime: type=HostCommunicationActiveTimes_keepAliveTime_typeApp
        wakeUpCount: type=HostCommunicationActiveTimes_wakeUpCount_typeApp
    AT_HostLocalActiveTimesApp
      application record element totalNumberOfEntries: category=VALUE, type=HostLocalActiveTimes_totalNumberOfEntries_typeApp
      application record element userNumber: category=VALUE, type=HostLocalActiveTimes_userNumber_typeApp
      application record element keepAliveTime: category=VALUE, type=HostLocalActiveTimes_keepAliveTime_typeApp
    AT_NetworkManagementActiveTimesApp
      5 x application record element, all with category=VALUE:
        totalNumberOfEntries: type=NetworkManagementActiveTimes_totalNumberOfEntries_typeApp
        sourceNodeIdentifier: type=NetworkManagementActiveTimes_sourceNodeIdentifier_typeApp
        busIdentifier: type=NetworkManagementActiveTimes_busIdentifier_typeApp
        keepAliveTime: type=NetworkManagementActiveTimes_keepAliveTime_typeApp
        wakeUpCount: type=NetworkManagementActiveTimes_wakeUpCount_typeApp
    AT_SystemFunctionActiveTimesApp
      application record element totalNumberOfEntries: category=VALUE, type=SystemFunctionActiveTimes_totalNumberOfEntries_typeApp
      application record element functionIdentifier: category=VALUE, type=SystemFunctionActiveTimes_functionIdentifier_typeApp
      application record element activeTime: category=VALUE, type=SystemFunctionActiveTimes_activeTime_typeApp
package /vwg/services/WakeUpMonitorData/deployment
  data type mapping set WakeUpMonitorDataMappings
    data-type-maps:
      application-data-type=getTable_busActiveTimesApp, implementation-data-type=getTable_busActiveTimes
      application-data-type=getTable_hostCommunicationActiveTimesApp, implementation-data-type=getTable_hostCommunicationActiveTimes
      application-data-type=getTable_hostLocalActiveTimesApp, implementation-data-type=getTable_hostLocalActiveTimes
      application-data-type=getTable_networkManagementActiveTimesApp, implementation-data-type=getTable_networkManagementActiveTimes
      application-data-type=getTable_systemfunctionActiveTimesApp, implementation-data-type=getTable_systemfunctionActiveTimes
      application-data-type=WakeUpMonitorData_UUIDAppApp, implementation-data-type=WakeUpMonitorData_UUIDApp
      application-data-type=BusActiveTimes_busIdentifier_typeApp, implementation-data-type=BusActiveTimes_busIdentifier_type
      application-data-type=BusActiveTimes_totalBusActiveTime_typeApp, implementation-data-type=BusActiveTimes_totalBusActiveTime_type
      application-data-type=BusActiveTimes_totalNumberOfEntries_typeApp, implementation-data-type=BusActiveTimes_totalNumberOfEntries_type
      application-data-type=BusActiveTimes_totalWakeUpCounts_typeApp, implementation-data-type=BusActiveTimes_totalWakeUpCounts_type
      application-data-type=ConfigurationTable_startDelay_typeApp, implementation-data-type=ConfigurationTable_startDelay_type
      application-data-type=ConfigurationTable_wakeDelay_typeApp, implementation-data-type=ConfigurationTable_wakeDelay_type
      application-data-type=ConfigurationTable_wakeUpMasterCycleCount_typeApp, implementation-data-type=ConfigurationTable_wakeUpMasterCycleCount_type
      application-data-type=getTable_cycleCounterAcknowledgement_typeApp, implementation-data-type=getTable_cycleCounterAcknowledgement_type
      application-data-type=getTable_cycleCounterRequested_typeApp, implementation-data-type=getTable_cycleCounterRequested_type
      application-data-type=HostCommunicationActiveTimes_keepAliveTime_typeApp, implementation-data-type=HostCommunicationActiveTimes_keepAliveTime_type
      application-data-type=HostCommunicationActiveTimes_totalNumberOfEntries_typeApp, implementation-data-type=HostCommunicationActiveTimes_totalNumberOfEntries_type
      application-data-type=HostCommunicationActiveTimes_userNumber_typeApp, implementation-data-type=HostCommunicationActiveTimes_userNumber_type
      application-data-type=HostCommunicationActiveTimes_wakeUpCount_typeApp, implementation-data-type=HostCommunicationActiveTimes_wakeUpCount_type
      application-data-type=HostLocalActiveTimes_keepAliveTime_typeApp, implementation-data-type=HostLocalActiveTimes_keepAliveTime_type
      application-data-type=HostLocalActiveTimes_totalNumberOfEntries_typeApp, implementation-data-type=HostLocalActiveTimes_totalNumberOfEntries_type
      application-data-type=HostLocalActiveTimes_userNumber_typeApp, implementation-data-type=HostLocalActiveTimes_userNumber_type
      application-data-type=NetworkManagementActiveTimes_busIdentifier_typeApp, implementation-data-type=NetworkManagementActiveTimes_busIdentifier_type
      application-data-type=NetworkManagementActiveTimes_keepAliveTime_typeApp, implementation-data-type=NetworkManagementActiveTimes_keepAliveTime_type
      application-data-type=NetworkManagementActiveTimes_sourceNodeIdentifier_typeApp, implementation-data-type=NetworkManagementActiveTimes_sourceNodeIdentifier_type
      application-data-type=NetworkManagementActiveTimes_totalNumberOfEntries_typeApp, implementation-data-type=NetworkManagementActiveTimes_totalNumberOfEntries_type
      application-data-type=NetworkManagementActiveTimes_wakeUpCount_typeApp, implementation-data-type=NetworkManagementActiveTimes_wakeUpCount_type
      application-data-type=startCycle_cycleCounterAcknowledgement_typeApp, implementation-data-type=startCycle_cycleCounterAcknowledgement_type
      application-data-type=startCycle_cycleCounterRequested_typeApp, implementation-data-type=startCycle_cycleCounterRequested_type
      application-data-type=SystemFunctionActiveTimes_activeTime_typeApp, implementation-data-type=SystemFunctionActiveTimes_activeTime_type
      application-data-type=SystemFunctionActiveTimes_functionIdentifier_typeApp, implementation-data-type=SystemFunctionActiveTimes_functionIdentifier_type
      application-data-type=SystemFunctionActiveTimes_totalNumberOfEntries_typeApp, implementation-data-type=SystemFunctionActiveTimes_totalNumberOfEntries_type
      application-data-type=WakeUpMonitorData_uint8App, implementation-data-type=uint8
      application-data-type=AT_BusActiveTimesApp, implementation-data-type=AT_BusActiveTimes
      application-data-type=AT_ConfigurationTableApp, implementation-data-type=AT_ConfigurationTable
      application-data-type=AT_HostCommunicationActiveTimesApp, implementation-data-type=AT_HostCommunicationActiveTimes
      application-data-type=AT_HostLocalActiveTimesApp, implementation-data-type=AT_HostLocalActiveTimes
      application-data-type=AT_NetworkManagementActiveTimesApp, implementation-data-type=AT_NetworkManagementActiveTimes
      application-data-type=AT_SystemFunctionActiveTimesApp, implementation-data-type=AT_SystemFunctionActiveTimes
package /vwg/services/SOMEIPTestabilityClient/datatypes
  30 x impl type:
    AT_RnRTestStructThreeArguments: category=STRUCTURE
      element rnrArg{1..3}: implementation-data-type=RnRTestStructThreeArguments_rnrArg{1..3}_type
      symbol props SymbolProps: symbol=SOMEIPTestabilityClient_AT_RnRTestStructThreeArguments
    AT_TestComplexStruct: category=STRUCTURE
      4 x element:
        availabilityBitfield: category=ARRAY, array-size-semantics=FIXED-SIZE
          element availabilityBitfieldArrayType: array-size=1, implementation-data-type=uint8
        a: implementation-data-type=TestComplexStruct_a_type
        b: implementation-data-type=TestComplexStruct_b_type
        c: implementation-data-type=TestComplexStruct_c
      symbol props SymbolProps: symbol=SOMEIPTestabilityClient_AT_TestComplexStruct
    AT_TestStruct: category=STRUCTURE
      element availabilityBitfield: category=ARRAY, array-size-semantics=FIXED-SIZE
        element availabilityBitfieldArrayType: array-size=1, implementation-data-type=uint8
      element a: implementation-data-type=TestStruct_a_type
      element b: implementation-data-type=TestStruct_b_type
      symbol props SymbolProps: symbol=SOMEIPTestabilityClient_AT_TestStruct
    RnRTestStructThreeArguments_rnrArg1_type: range phys 0..255, raw 0..255, implementation-data-type=uint8
      symbol props SymbolProps: symbol=SOMEIPTestabilityClient_RnRTestStructThreeArguments_rnrArg1_type
    RnRTestStructThreeArguments_rnrArg2_type: range phys 0..65535, raw 0..65535, implementation-data-type=uint16
      symbol props SymbolProps: symbol=SOMEIPTestabilityClient_RnRTestStructThreeArguments_rnrArg2_type
    RnRTestStructThreeArguments_rnrArg3_type: range phys 0..4294967295, raw 0..4294967295, implementation-data-type=uint32
      symbol props SymbolProps: symbol=SOMEIPTestabilityClient_RnRTestStructThreeArguments_rnrArg3_type
    TestComplexStruct_a_type: range phys 0..255, raw 0..255, implementation-data-type=uint8
      symbol props SymbolProps: symbol=SOMEIPTestabilityClient_TestComplexStruct_a_type
    TestComplexStruct_b_type: category=STRUCTURE, dynamic-array-size-profile=VSA_LINEAR
      element size: implementation-data-type=uint8
      element string: category=ARRAY
        element character: array-size=64, array-size-handling=ALL-INDICES-SAME-ARRAY-SIZE, array-size-semantics=VARIABLE-SIZE, implementation-data-type=uint8
      symbol props SymbolProps: symbol=SOMEIPTestabilityClient_TestComplexStruct_b_type
    TestComplexStruct_c: category=STRUCTURE, dynamic-array-size-profile=VSA_LINEAR
      element size: implementation-data-type=uint8
      element payload: category=ARRAY
        element TestComplexStruct_c_base_type: array-size=5, array-size-handling=ALL-INDICES-SAME-ARRAY-SIZE, array-size-semantics=VARIABLE-SIZE, implementation-data-type=TestComplexStruct_c_base_type
      symbol props SymbolProps: symbol=SOMEIPTestabilityClient_TestComplexStruct_c
    TestComplexStruct_c_base_type: range phys 0..255, raw 0..255, implementation-data-type=uint8
      symbol props SymbolProps: symbol=SOMEIPTestabilityClient_TestComplexStruct_c_base_type
    TestFieldUInt8_type: range phys 0..255, raw 0..255, implementation-data-type=uint8
      symbol props SymbolProps: symbol=SOMEIPTestabilityClient_TestFieldUInt8_type
    TestStruct_a_type: range phys 0..255, raw 0..255, implementation-data-type=uint8
      symbol props SymbolProps: symbol=SOMEIPTestabilityClient_TestStruct_a_type
    TestStruct_b_type: range phys 0..65535, raw 0..65535, implementation-data-type=uint16
      symbol props SymbolProps: symbol=SOMEIPTestabilityClient_TestStruct_b_type
    SOMEIPTestabilityClient_UUIDApp: category=ARRAY
      element UUIDAppBase: array-size=16, array-size-semantics=FIXED-SIZE, implementation-data-type=uint8
      symbol props SymbolProps: symbol=SOMEIPTestabilityClient_UUIDApp
    echoComplexDynamicArray_inArray: category=STRUCTURE, dynamic-array-size-profile=VSA_LINEAR
      element size: implementation-data-type=uint8
      element payload: category=ARRAY
        element AT_TestStruct: array-size=5, array-size-handling=ALL-INDICES-SAME-ARRAY-SIZE, array-size-semantics=VARIABLE-SIZE, implementation-data-type=AT_TestStruct
      symbol props SymbolProps: symbol=SOMEIPTestabilityClient_echoComplexDynamicArray_inArray
    echoComplexDynamicArray_outArray: category=STRUCTURE, dynamic-array-size-profile=VSA_LINEAR
      element size: implementation-data-type=uint8
      element payload: category=ARRAY
        element AT_TestStruct: array-size=5, array-size-handling=ALL-INDICES-SAME-ARRAY-SIZE, array-size-semantics=VARIABLE-SIZE, implementation-data-type=AT_TestStruct
      symbol props SymbolProps: symbol=SOMEIPTestabilityClient_echoComplexDynamicArray_outArray
    echoFloat32_inFloat32_type: range phys -1000..1000, raw -1000..1000, implementation-data-type=float32
      symbol props SymbolProps: symbol=SOMEIPTestabilityClient_echoFloat32_inFloat32_type
    echoFloat32_outFloat32_type: range phys -1000..1000, raw -1000..1000, implementation-data-type=float32
      symbol props SymbolProps: symbol=SOMEIPTestabilityClient_echoFloat32_outFloat32_type
    echoUInt8UInt16UInt32_inUInt16_type: range phys 0..65535, raw 0..65535, implementation-data-type=uint16
      symbol props SymbolProps: symbol=SOMEIPTestabilityClient_echoUInt8UInt16UInt32_inUInt16_type
    echoUInt8UInt16UInt32_inUInt32_type: range phys 0..4294967295, raw 0..4294967295, implementation-data-type=uint32
      symbol props SymbolProps: symbol=SOMEIPTestabilityClient_echoUInt8UInt16UInt32_inUInt32_type
    echoUInt8UInt16UInt32_inUInt8_type: range phys 0..255, raw 0..255, implementation-data-type=uint8
      symbol props SymbolProps: symbol=SOMEIPTestabilityClient_echoUInt8UInt16UInt32_inUInt8_type
    echoUInt8UInt16UInt32_outUInt16_type: range phys 0..65535, raw 0..65535, implementation-data-type=uint16
      symbol props SymbolProps: symbol=SOMEIPTestabilityClient_echoUInt8UInt16UInt32_outUInt16_type
    echoUInt8UInt16UInt32_outUInt32_type: range phys 0..4294967295, raw 0..4294967295, implementation-data-type=uint32
      symbol props SymbolProps: symbol=SOMEIPTestabilityClient_echoUInt8UInt16UInt32_outUInt32_type
    echoUInt8UInt16UInt32_outUInt8_type: range phys 0..255, raw 0..255, implementation-data-type=uint8
      symbol props SymbolProps: symbol=SOMEIPTestabilityClient_echoUInt8UInt16UInt32_outUInt8_type
    echoUInt8_inUInt8_type: range phys 0..255, raw 0..255, implementation-data-type=uint8
      symbol props SymbolProps: symbol=SOMEIPTestabilityClient_echoUInt8_inUInt8_type
    echoUInt8_outUInt8_type: range phys 0..255, raw 0..255, implementation-data-type=uint8
      symbol props SymbolProps: symbol=SOMEIPTestabilityClient_echoUInt8_outUInt8_type
    noResponseUInt8_inUInt8_type: range phys 0..255, raw 0..255, implementation-data-type=uint8
      symbol props SymbolProps: symbol=SOMEIPTestabilityClient_noResponseUInt8_inUInt8_type
    rnrEchoComplexDynamicArray_arg1ComplexDynArray: category=STRUCTURE, dynamic-array-size-profile=VSA_LINEAR
      element size: implementation-data-type=uint8
      element payload: category=ARRAY
        element AT_TestStruct: array-size=5, array-size-handling=ALL-INDICES-SAME-ARRAY-SIZE, array-size-semantics=VARIABLE-SIZE, implementation-data-type=AT_TestStruct
      symbol props SymbolProps: symbol=SOMEIPTestabilityClient_rnrEchoComplexDynamicArray_arg1ComplexDynArray
    rnrEchoFloat32_arg1Float32_type: range phys -1000..1000, raw -1000..1000, implementation-data-type=float32
      symbol props SymbolProps: symbol=SOMEIPTestabilityClient_rnrEchoFloat32_arg1Float32_type
    testEventUInt8_data_type: range phys 0..255, raw 0..255, implementation-data-type=uint8
      symbol props SymbolProps: symbol=SOMEIPTestabilityClient_testEventUInt8_data_type
  5 x application array data type, all with category=ARRAY:
    echoComplexDynamicArray_inArrayApp: dynamic-array-size-profile=VSA_LINEAR
      element AT_TestStruct: category=VALUE, type=AT_TestStructApp, array-size-handling=ALL-INDICES-SAME-ARRAY-SIZE, array-size-semantics=VARIABLE-SIZE, max-number-of-elements=5
    echoComplexDynamicArray_outArrayApp: dynamic-array-size-profile=VSA_LINEAR
      element AT_TestStruct: category=VALUE, type=AT_TestStructApp, array-size-handling=ALL-INDICES-SAME-ARRAY-SIZE, array-size-semantics=VARIABLE-SIZE, max-number-of-elements=5
    rnrEchoComplexDynamicArray_arg1ComplexDynArrayApp: dynamic-array-size-profile=VSA_LINEAR
      element AT_TestStruct: category=VALUE, type=AT_TestStructApp, array-size-handling=ALL-INDICES-SAME-ARRAY-SIZE, array-size-semantics=VARIABLE-SIZE, max-number-of-elements=5
    TestComplexStruct_cApp: dynamic-array-size-profile=VSA_LINEAR
      element TestComplexStruct_c_base_type: category=VALUE, type=TestComplexStruct_c_base_typeApp, array-size-handling=ALL-INDICES-SAME-ARRAY-SIZE, array-size-semantics=VARIABLE-SIZE, max-number-of-elements=5
    SOMEIPTestabilityClient_UUIDAppApp
      element uint8: category=VALUE, type=SOMEIPTestabilityClient_uint8App, array-size-semantics=FIXED-SIZE, max-number-of-elements=16
  23 x app type:
    echoFloat32_inFloat32_typeApp: category=VALUE, compu {identical}, range phys -1000..1000, raw -1000..1000, sw-intended-resolution=0.00001
    echoFloat32_outFloat32_typeApp: category=VALUE, compu {identical}, range phys -1000..1000, raw -1000..1000, sw-intended-resolution=0.00001
    echoUInt8_inUInt8_typeApp: category=VALUE, compu {identical}, range phys 0..255, raw 0..255
    echoUInt8_outUInt8_typeApp: category=VALUE, compu {identical}, range phys 0..255, raw 0..255
    echoUInt8UInt16UInt32_inUInt16_typeApp: category=VALUE, compu {identical}, range phys 0..65535, raw 0..65535
    echoUInt8UInt16UInt32_inUInt32_typeApp: category=VALUE, compu {identical}, range phys 0..4294967295, raw 0..4294967295
    echoUInt8UInt16UInt32_inUInt8_typeApp: category=VALUE, compu {identical}, range phys 0..255, raw 0..255
    echoUInt8UInt16UInt32_outUInt16_typeApp: category=VALUE, compu {identical}, range phys 0..65535, raw 0..65535
    echoUInt8UInt16UInt32_outUInt32_typeApp: category=VALUE, compu {identical}, range phys 0..4294967295, raw 0..4294967295
    echoUInt8UInt16UInt32_outUInt8_typeApp: category=VALUE, compu {identical}, range phys 0..255, raw 0..255
    noResponseUInt8_inUInt8_typeApp: category=VALUE, compu {identical}, range phys 0..255, raw 0..255
    rnrEchoFloat32_arg1Float32_typeApp: category=VALUE, compu {identical}, range phys -1000..1000, raw -1000..1000, sw-intended-resolution=0.00001
    RnRTestStructThreeArguments_rnrArg1_typeApp: category=VALUE, compu {identical}, range phys 0..255, raw 0..255
    RnRTestStructThreeArguments_rnrArg2_typeApp: category=VALUE, compu {identical}, range phys 0..65535, raw 0..65535
    RnRTestStructThreeArguments_rnrArg3_typeApp: category=VALUE, compu {identical}, range phys 0..4294967295, raw 0..4294967295
    TestComplexStruct_a_typeApp: category=VALUE, compu {identical}, range phys 0..255, raw 0..255
    TestComplexStruct_c_base_typeApp: category=VALUE, compu {identical}, range phys 0..255, raw 0..255
    testEventUInt8_data_typeApp: category=VALUE, compu {identical}, range phys 0..255, raw 0..255
    TestFieldUInt8_typeApp: category=VALUE, compu {identical}, range phys 0..255, raw 0..255
    TestStruct_a_typeApp: category=VALUE, compu {identical}, range phys 0..255, raw 0..255
    TestStruct_b_typeApp: category=VALUE, compu {identical}, range phys 0..65535, raw 0..65535
    SOMEIPTestabilityClient_uint8App: category=VALUE
    TestComplexStruct_b_typeApp: category=STRING, sw-text-props={array-size-semantics=VARIABLE-SIZE, sw-max-text-size=16, base-type=string}, sw-record-layout=StringDescriptor
  application record data type AT_RnRTestStructThreeArgumentsApp: category=STRUCTURE
    application record element rnrArg{1..3}: category=VALUE, type=RnRTestStructThreeArguments_rnrArg{1..3}_typeApp
  application record data type AT_TestComplexStructApp: category=STRUCTURE
    application record element a: category=VALUE, type=TestComplexStruct_a_typeApp
    application record element b: category=STRING, type=TestComplexStruct_b_typeApp
    application record element c: category=ARRAY, type=TestComplexStruct_cApp
  application record data type AT_TestStructApp: category=STRUCTURE
    application record element a: category=VALUE, type=TestStruct_a_typeApp
    application record element b: category=VALUE, type=TestStruct_b_typeApp
package /vwg/services/SOMEIPTestabilityClient/deployment
  data type mapping set SOMEIPTestabilityClientMappings
    data-type-maps:
      application-data-type=echoComplexDynamicArray_inArrayApp, implementation-data-type=echoComplexDynamicArray_inArray
      application-data-type=echoComplexDynamicArray_outArrayApp, implementation-data-type=echoComplexDynamicArray_outArray
      application-data-type=rnrEchoComplexDynamicArray_arg1ComplexDynArrayApp, implementation-data-type=rnrEchoComplexDynamicArray_arg1ComplexDynArray
      application-data-type=TestComplexStruct_cApp, implementation-data-type=TestComplexStruct_c
      application-data-type=SOMEIPTestabilityClient_UUIDAppApp, implementation-data-type=SOMEIPTestabilityClient_UUIDApp
      application-data-type=echoFloat32_inFloat32_typeApp, implementation-data-type=echoFloat32_inFloat32_type
      application-data-type=echoFloat32_outFloat32_typeApp, implementation-data-type=echoFloat32_outFloat32_type
      application-data-type=echoUInt8_inUInt8_typeApp, implementation-data-type=echoUInt8_inUInt8_type
      application-data-type=echoUInt8_outUInt8_typeApp, implementation-data-type=echoUInt8_outUInt8_type
      application-data-type=echoUInt8UInt16UInt32_inUInt16_typeApp, implementation-data-type=echoUInt8UInt16UInt32_inUInt16_type
      application-data-type=echoUInt8UInt16UInt32_inUInt32_typeApp, implementation-data-type=echoUInt8UInt16UInt32_inUInt32_type
      application-data-type=echoUInt8UInt16UInt32_inUInt8_typeApp, implementation-data-type=echoUInt8UInt16UInt32_inUInt8_type
      application-data-type=echoUInt8UInt16UInt32_outUInt16_typeApp, implementation-data-type=echoUInt8UInt16UInt32_outUInt16_type
      application-data-type=echoUInt8UInt16UInt32_outUInt32_typeApp, implementation-data-type=echoUInt8UInt16UInt32_outUInt32_type
      application-data-type=echoUInt8UInt16UInt32_outUInt8_typeApp, implementation-data-type=echoUInt8UInt16UInt32_outUInt8_type
      application-data-type=noResponseUInt8_inUInt8_typeApp, implementation-data-type=noResponseUInt8_inUInt8_type
      application-data-type=rnrEchoFloat32_arg1Float32_typeApp, implementation-data-type=rnrEchoFloat32_arg1Float32_type
      application-data-type=RnRTestStructThreeArguments_rnrArg{1..3}_typeApp, implementation-data-type=RnRTestStructThreeArguments_rnrArg{1..3}_type
      application-data-type=TestComplexStruct_a_typeApp, implementation-data-type=TestComplexStruct_a_type
      application-data-type=TestComplexStruct_c_base_typeApp, implementation-data-type=TestComplexStruct_c_base_type
      application-data-type=testEventUInt8_data_typeApp, implementation-data-type=testEventUInt8_data_type
      application-data-type=TestFieldUInt8_typeApp, implementation-data-type=TestFieldUInt8_type
      application-data-type=TestStruct_a_typeApp, implementation-data-type=TestStruct_a_type
      application-data-type=TestStruct_b_typeApp, implementation-data-type=TestStruct_b_type
      application-data-type=SOMEIPTestabilityClient_uint8App, implementation-data-type=uint8
      application-data-type=TestComplexStruct_b_typeApp, implementation-data-type=TestComplexStruct_b_type
      application-data-type=AT_RnRTestStructThreeArgumentsApp, implementation-data-type=AT_RnRTestStructThreeArguments
      application-data-type=AT_TestComplexStructApp, implementation-data-type=AT_TestComplexStruct
      application-data-type=AT_TestStructApp, implementation-data-type=AT_TestStruct
package /vwg/services/SOMEIPTestabilityReliable/datatypes
  compu method AT_EnumOperationTypeCM: 0=Cx0_performSummatory (AT_EnumOperationTypeCM_Cx0_performSummatory), 1=Cx1_returnMemoryAlignment (AT_EnumOperationTypeCM_Cx1_returnMemoryAlignment)
  compu method AT_EnumTsClientTypeCM: 0=Cx0_TsClientBaseCSI (AT_EnumTsClientTypeCM_Cx0_TsClientBaseCSI), 1=Cx1_TsClientBaseCSIReliable (AT_EnumTsClientTypeCM_Cx1_TsClientBaseCSIReliable), 2=Cx2_TsClientExtCSISegmented (AT_EnumTsClientTypeCM_Cx2_TsClientExtCSISegmented), 3=Cx3_TsClientExtCSIMulticast (AT_EnumTsClientTypeCM_Cx3_TsClientExtCSIMulticast), 4=Cx4_TsClientMaxNumConsumer (AT_EnumTsClientTypeCM_Cx4_TsClientMaxNumConsumer)
  compu method SOMEIPTestabilityReliable_activateTsClient_ReturnCM: 33=Cx21_ActivateTsClientClientInterfaceActivationFailed (SOMEIPTestabilityReliable_activateTsClient_ReturnCM_Cx21_ActivateTsClientClientInterfaceActivationFailed)
  compu method SOMEIPTestabilityReliable_deactivateTsClient_ReturnCM: 34=Cx22_DeactivateTsClientClientInterfaceDeactivationFailed (SOMEIPTestabilityReliable_deactivateTsClient_ReturnCM_Cx22_DeactivateTsClientClientInterfaceDeactivationFailed)
  compu method SOMEIPTestabilityReliable_enableSubscription_ReturnCM: 32=Cx20_EnableSubscriptionClientInterfaceSubscriptionFailed (SOMEIPTestabilityReliable_enableSubscription_ReturnCM_Cx20_EnableSubscriptionClientInterfaceSubscriptionFailed)
  compu method SOMEIPTestabilityReliable_resetInterface_ReturnCM: 35=Cx23_ResetInterfaceResetInterfaceFailed (SOMEIPTestabilityReliable_resetInterface_ReturnCM_Cx23_ResetInterfaceResetInterfaceFailed)
  89 x impl type:
    AT_EnumOperationType: compu-method=AT_EnumOperationTypeCM, range raw 0..1, implementation-data-type=uint8
      symbol props SymbolProps: symbol=SOMEIPTestabilityReliable_AT_EnumOperationType
    AT_EnumTsClientType: compu-method=AT_EnumTsClientTypeCM, range raw 0..4, implementation-data-type=uint8
      symbol props SymbolProps: symbol=SOMEIPTestabilityReliable_AT_EnumTsClientType
    SOMEIPTestabilityReliable_AT_RnRTestStructThreeArguments: category=STRUCTURE
      element rnrArg{1..3}: implementation-data-type=SOMEIPTestabilityReliable_RnRTestStructThreeArguments_rnrArg{1..3}_type
      symbol props SymbolProps: symbol=SOMEIPTestabilityReliable_AT_RnRTestStructThreeArguments
    AT_RnRTriggerEchoLDACmdType: category=STRUCTURE
      element client: implementation-data-type=AT_EnumTsClientType
      element numElements: implementation-data-type=RnRTriggerEchoLDACmdType_numElements_type
      symbol props SymbolProps: symbol=SOMEIPTestabilityReliable_AT_RnRTriggerEchoLDACmdType
    SOMEIPTestabilityReliable_AT_TestComplexStruct: category=STRUCTURE
      4 x element:
        availabilityBitfield: category=ARRAY, array-size-semantics=FIXED-SIZE
          element availabilityBitfieldArrayType: array-size=1, implementation-data-type=uint8
        a: implementation-data-type=SOMEIPTestabilityReliable_TestComplexStruct_a_type
        b: implementation-data-type=SOMEIPTestabilityReliable_TestComplexStruct_b_type
        c: implementation-data-type=SOMEIPTestabilityReliable_TestComplexStruct_c
      symbol props SymbolProps: symbol=SOMEIPTestabilityReliable_AT_TestComplexStruct
    SOMEIPTestabilityReliable_AT_TestStruct: category=STRUCTURE
      element availabilityBitfield: category=ARRAY, array-size-semantics=FIXED-SIZE
        element availabilityBitfieldArrayType: array-size=1, implementation-data-type=uint8
      element a: implementation-data-type=SOMEIPTestabilityReliable_TestStruct_a_type
      element b: implementation-data-type=SOMEIPTestabilityReliable_TestStruct_b_type
      symbol props SymbolProps: symbol=SOMEIPTestabilityReliable_AT_TestStruct
    AT_TestStructInStruct: category=STRUCTURE
      5 x element, all with category=TYPE_REFERENCE:
        a: implementation-data-type=TestStructInStruct_a_type
        b: implementation-data-type=TestStructInStruct_b_type
        c: implementation-data-type=TestStructInStruct_c_type
        d: implementation-data-type=TestStructInStruct_d_type
        e: implementation-data-type=SOMEIPTestabilityReliable_AT_TestStruct
      symbol props SymbolProps: symbol=SOMEIPTestabilityReliable_AT_TestStructInStruct
    SOMEIPTestabilityReliable_RnRTestStructThreeArguments_rnrArg1_type: range phys 0..255, raw 0..255, implementation-data-type=uint8
      symbol props SymbolProps: symbol=SOMEIPTestabilityReliable_RnRTestStructThreeArguments_rnrArg1_type
    SOMEIPTestabilityReliable_RnRTestStructThreeArguments_rnrArg2_type: range phys 0..65535, raw 0..65535, implementation-data-type=uint16
      symbol props SymbolProps: symbol=SOMEIPTestabilityReliable_RnRTestStructThreeArguments_rnrArg2_type
    SOMEIPTestabilityReliable_RnRTestStructThreeArguments_rnrArg3_type: range phys 0..4294967295, raw 0..4294967295, implementation-data-type=uint32
      symbol props SymbolProps: symbol=SOMEIPTestabilityReliable_RnRTestStructThreeArguments_rnrArg3_type
    RnRTriggerEchoLDACmdType_numElements_type: range phys 0..1141, raw 0..1141, implementation-data-type=uint16
      symbol props SymbolProps: symbol=SOMEIPTestabilityReliable_RnRTriggerEchoLDACmdType_numElements_type
    SOMEIPTestabilityReliable_activateTsClient_Return: compu-method=SOMEIPTestabilityReliable_activateTsClient_ReturnCM, range raw 33, implementation-data-type=uint8
      symbol props SymbolProps: symbol=SOMEIPTestabilityReliable_SOMEIPTestabilityReliable_activateTsClient_Return
    SOMEIPTestabilityReliable_deactivateTsClient_Return: compu-method=SOMEIPTestabilityReliable_deactivateTsClient_ReturnCM, range raw 34, implementation-data-type=uint8
      symbol props SymbolProps: symbol=SOMEIPTestabilityReliable_SOMEIPTestabilityReliable_deactivateTsClient_Return
    SOMEIPTestabilityReliable_enableSubscription_Return: compu-method=SOMEIPTestabilityReliable_enableSubscription_ReturnCM, range raw 32, implementation-data-type=uint8
      symbol props SymbolProps: symbol=SOMEIPTestabilityReliable_SOMEIPTestabilityReliable_enableSubscription_Return
    SOMEIPTestabilityReliable_resetInterface_Return: compu-method=SOMEIPTestabilityReliable_resetInterface_ReturnCM, range raw 35, implementation-data-type=uint8
      symbol props SymbolProps: symbol=SOMEIPTestabilityReliable_SOMEIPTestabilityReliable_resetInterface_Return
    SOMEIPTestabilityReliable_TestComplexStruct_a_type: range phys 0..255, raw 0..255, implementation-data-type=uint8
      symbol props SymbolProps: symbol=SOMEIPTestabilityReliable_TestComplexStruct_a_type
    SOMEIPTestabilityReliable_TestComplexStruct_b_type: category=STRUCTURE, dynamic-array-size-profile=VSA_LINEAR
      element size: implementation-data-type=uint8
      element string: category=ARRAY
        element character: array-size=64, array-size-handling=ALL-INDICES-SAME-ARRAY-SIZE, array-size-semantics=VARIABLE-SIZE, implementation-data-type=uint8
      symbol props SymbolProps: symbol=SOMEIPTestabilityReliable_TestComplexStruct_b_type
    SOMEIPTestabilityReliable_TestComplexStruct_c: category=STRUCTURE, dynamic-array-size-profile=VSA_LINEAR
      element size: implementation-data-type=uint8
      element payload: category=ARRAY
        element TestComplexStruct_c_base_type: array-size=5, array-size-handling=ALL-INDICES-SAME-ARRAY-SIZE, array-size-semantics=VARIABLE-SIZE, implementation-data-type=SOMEIPTestabilityReliable_TestComplexStruct_c_base_type
      symbol props SymbolProps: symbol=SOMEIPTestabilityReliable_TestComplexStruct_c
    SOMEIPTestabilityReliable_TestComplexStruct_c_base_type: range phys 0..255, raw 0..255, implementation-data-type=uint8
      symbol props SymbolProps: symbol=SOMEIPTestabilityReliable_TestComplexStruct_c_base_type
    TestFieldUInt64_type: range phys 0..18446744073709551615, raw 0..18446744073709551615, implementation-data-type=uint64
      symbol props SymbolProps: symbol=SOMEIPTestabilityReliable_TestFieldUInt64_type
    SOMEIPTestabilityReliable_TestFieldUInt8_type: range phys 0..255, raw 0..255, implementation-data-type=uint8
      symbol props SymbolProps: symbol=SOMEIPTestabilityReliable_TestFieldUInt8_type
    TestStructInStruct_a_type: range phys 0..255, raw 0..255, implementation-data-type=uint8
      symbol props SymbolProps: symbol=SOMEIPTestabilityReliable_TestStructInStruct_a_type
    TestStructInStruct_b_type: range phys 0..65535, raw 0..65535, implementation-data-type=uint16
      symbol props SymbolProps: symbol=SOMEIPTestabilityReliable_TestStructInStruct_b_type
    TestStructInStruct_c_type: range phys 0..4294967295, raw 0..4294967295, implementation-data-type=uint32
      symbol props SymbolProps: symbol=SOMEIPTestabilityReliable_TestStructInStruct_c_type
    TestStructInStruct_d_type: range phys -1000..1000, raw -1000..1000, implementation-data-type=float32
      symbol props SymbolProps: symbol=SOMEIPTestabilityReliable_TestStructInStruct_d_type
    SOMEIPTestabilityReliable_TestStruct_a_type: range phys 0..255, raw 0..255, implementation-data-type=uint8
      symbol props SymbolProps: symbol=SOMEIPTestabilityReliable_TestStruct_a_type
    SOMEIPTestabilityReliable_TestStruct_b_type: range phys 0..65535, raw 0..65535, implementation-data-type=uint16
      symbol props SymbolProps: symbol=SOMEIPTestabilityReliable_TestStruct_b_type
    SOMEIPTestabilityReliable_UUIDApp: category=ARRAY
      element UUIDAppBase: array-size=16, array-size-semantics=FIXED-SIZE, implementation-data-type=uint8
      symbol props SymbolProps: symbol=SOMEIPTestabilityReliable_UUIDApp
    activateTsClient_startDelay_type: range phys 0..255, raw 0..255, implementation-data-type=uint8
      symbol props SymbolProps: symbol=SOMEIPTestabilityReliable_activateTsClient_startDelay_type
    checkByteOrder_inUInt16_type: range phys 0..65535, raw 0..65535, implementation-data-type=uint16
      symbol props SymbolProps: symbol=SOMEIPTestabilityReliable_checkByteOrder_inUInt16_type
    checkByteOrder_inUInt32_type: range phys 0..4294967295, raw 0..4294967295, implementation-data-type=uint32
      symbol props SymbolProps: symbol=SOMEIPTestabilityReliable_checkByteOrder_inUInt32_type
    checkByteOrder_outUInt16_type: range phys 0..65535, raw 0..65535, implementation-data-type=uint16
      symbol props SymbolProps: symbol=SOMEIPTestabilityReliable_checkByteOrder_outUInt16_type
    checkByteOrder_outUInt32_type: range phys 0..4294967295, raw 0..4294967295, implementation-data-type=uint32
      symbol props SymbolProps: symbol=SOMEIPTestabilityReliable_checkByteOrder_outUInt32_type
    deactivateTsClient_delay_type: range phys 0..255, raw 0..255, implementation-data-type=uint8
      symbol props SymbolProps: symbol=SOMEIPTestabilityReliable_deactivateTsClient_delay_type
    SOMEIPTestabilityReliable_echoComplexDynamicArray_inArray: category=STRUCTURE, dynamic-array-size-profile=VSA_LINEAR
      element size: implementation-data-type=uint8
      element payload: category=ARRAY
        element AT_TestStruct: array-size=5, array-size-handling=ALL-INDICES-SAME-ARRAY-SIZE, array-size-semantics=VARIABLE-SIZE, implementation-data-type=SOMEIPTestabilityReliable_AT_TestStruct
      symbol props SymbolProps: symbol=SOMEIPTestabilityReliable_echoComplexDynamicArray_inArray
    SOMEIPTestabilityReliable_echoComplexDynamicArray_outArray: category=STRUCTURE, dynamic-array-size-profile=VSA_LINEAR
      element size: implementation-data-type=uint8
      element payload: category=ARRAY
        element AT_TestStruct: array-size=5, array-size-handling=ALL-INDICES-SAME-ARRAY-SIZE, array-size-semantics=VARIABLE-SIZE, implementation-data-type=SOMEIPTestabilityReliable_AT_TestStruct
      symbol props SymbolProps: symbol=SOMEIPTestabilityReliable_echoComplexDynamicArray_outArray
    SOMEIPTestabilityReliable_echoFloat32_inFloat32_type: range phys -1000..1000, raw -1000..1000, implementation-data-type=float32
      symbol props SymbolProps: symbol=SOMEIPTestabilityReliable_echoFloat32_inFloat32_type
    SOMEIPTestabilityReliable_echoFloat32_outFloat32_type: range phys -1000..1000, raw -1000..1000, implementation-data-type=float32
      symbol props SymbolProps: symbol=SOMEIPTestabilityReliable_echoFloat32_outFloat32_type
    echoFloat64_inFloat64_type: range phys -10000..10000, raw -10000..10000, implementation-data-type=float64
      symbol props SymbolProps: symbol=SOMEIPTestabilityReliable_echoFloat64_inFloat64_type
    echoFloat64_outFloat64_type: range phys -10000..10000, raw -10000..10000, implementation-data-type=float64
      symbol props SymbolProps: symbol=SOMEIPTestabilityReliable_echoFloat64_outFloat64_type
    echoInverseBitField_inBitfield1_type: range phys 0..255, raw 0..255, implementation-data-type=uint8
      symbol props SymbolProps: symbol=SOMEIPTestabilityReliable_echoInverseBitField_inBitfield1_type
    echoInverseBitField_inBitfield2_type: range phys 0..255, raw 0..255, implementation-data-type=uint8
      symbol props SymbolProps: symbol=SOMEIPTestabilityReliable_echoInverseBitField_inBitfield2_type
    echoInverseBitField_outBitfield1_type: range phys 0..255, raw 0..255, implementation-data-type=uint8
      symbol props SymbolProps: symbol=SOMEIPTestabilityReliable_echoInverseBitField_outBitfield1_type
    echoInverseBitField_outBitfield2_type: range phys 0..255, raw 0..255, implementation-data-type=uint8
      symbol props SymbolProps: symbol=SOMEIPTestabilityReliable_echoInverseBitField_outBitfield2_type
    echoInverseDynamicArray_inArray: category=STRUCTURE, dynamic-array-size-profile=VSA_LINEAR
      element size: implementation-data-type=uint8
      element payload: category=ARRAY
        element echoInverseDynamicArray_inArray_base_type: array-size=5, array-size-handling=ALL-INDICES-SAME-ARRAY-SIZE, array-size-semantics=VARIABLE-SIZE, implementation-data-type=echoInverseDynamicArray_inArray_base_type
      symbol props SymbolProps: symbol=SOMEIPTestabilityReliable_echoInverseDynamicArray_inArray
    echoInverseDynamicArray_inArray_base_type: range phys 0..255, raw 0..255, implementation-data-type=uint8
      symbol props SymbolProps: symbol=SOMEIPTestabilityReliable_echoInverseDynamicArray_inArray_base_type
    echoInverseDynamicArray_outArray: category=STRUCTURE, dynamic-array-size-profile=VSA_LINEAR
      element size: implementation-data-type=uint8
      element payload: category=ARRAY
        element echoInverseDynamicArray_outArray_base_type: array-size=5, array-size-handling=ALL-INDICES-SAME-ARRAY-SIZE, array-size-semantics=VARIABLE-SIZE, implementation-data-type=echoInverseDynamicArray_outArray_base_type
      symbol props SymbolProps: symbol=SOMEIPTestabilityReliable_echoInverseDynamicArray_outArray
    echoInverseDynamicArray_outArray_base_type: range phys 0..255, raw 0..255, implementation-data-type=uint8
      symbol props SymbolProps: symbol=SOMEIPTestabilityReliable_echoInverseDynamicArray_outArray_base_type
    echoInverseDynamicMultidimensionalArray_inArray: category=STRUCTURE, dynamic-array-size-profile=VSA_FULLY_FLEXIBLE
      element size: implementation-data-type=uint8
      element payload: category=ARRAY
        element array: category=STRUCTURE, array-size=5, array-size-handling=ALL-INDICES-DIFFERENT-ARRAY-SIZE, array-size-semantics=VARIABLE-SIZE
          element size: implementation-data-type=uint8
          element payload: category=ARRAY
            element element: array-size=5, array-size-handling=ALL-INDICES-SAME-ARRAY-SIZE, array-size-semantics=VARIABLE-SIZE, implementation-data-type=uint8
      symbol props SymbolProps: symbol=SOMEIPTestabilityReliable_echoInverseDynamicMultidimensionalArray_inArray
    echoInverseDynamicMultidimensionalArray_outArray: category=STRUCTURE, dynamic-array-size-profile=VSA_FULLY_FLEXIBLE
      element size: implementation-data-type=uint8
      element payload: category=ARRAY
        element array: category=STRUCTURE, array-size=5, array-size-handling=ALL-INDICES-DIFFERENT-ARRAY-SIZE, array-size-semantics=VARIABLE-SIZE
          element size: implementation-data-type=uint8
          element payload: category=ARRAY
            element element: array-size=5, array-size-handling=ALL-INDICES-SAME-ARRAY-SIZE, array-size-semantics=VARIABLE-SIZE, implementation-data-type=uint8
      symbol props SymbolProps: symbol=SOMEIPTestabilityReliable_echoInverseDynamicMultidimensionalArray_outArray
    echoSInt16_inSInt16_type: range phys -32768..32767, raw -32768..32767, implementation-data-type=sint16
      symbol props SymbolProps: symbol=SOMEIPTestabilityReliable_echoSInt16_inSInt16_type
    echoSInt16_outSInt16_type: range phys -32768..32767, raw -32768..32767, implementation-data-type=sint16
      symbol props SymbolProps: symbol=SOMEIPTestabilityReliable_echoSInt16_outSInt16_type
    echoSInt32_inSInt32_type: range phys -2147483648..2147483647, raw -2147483648..2147483647, implementation-data-type=sint32
      symbol props SymbolProps: symbol=SOMEIPTestabilityReliable_echoSInt32_inSInt32_type
    echoSInt32_outSInt32_type: range phys -2147483648..2147483647, raw -2147483648..2147483647, implementation-data-type=sint32
      symbol props SymbolProps: symbol=SOMEIPTestabilityReliable_echoSInt32_outSInt32_type
    echoSInt64_inSInt64_type: range phys -9223372036854775808..9223372036854775807, raw -9223372036854775808..9223372036854775807, implementation-data-type=sint64
      symbol props SymbolProps: symbol=SOMEIPTestabilityReliable_echoSInt64_inSInt64_type
    echoSInt64_outSInt64_type: range phys -9223372036854775808..-9223372036854775807, raw -9223372036854775808..-9223372036854775807, implementation-data-type=sint64
      symbol props SymbolProps: symbol=SOMEIPTestabilityReliable_echoSInt64_outSInt64_type
    echoSInt8_inSInt8_type: range phys -128..127, raw -128..127, implementation-data-type=sint8
      symbol props SymbolProps: symbol=SOMEIPTestabilityReliable_echoSInt8_inSInt8_type
    echoSInt8_outSInt8_type: range phys -128..127, raw -128..127, implementation-data-type=sint8
      symbol props SymbolProps: symbol=SOMEIPTestabilityReliable_echoSInt8_outSInt8_type
    echoUInt16_inUInt16_type: range phys 0..65535, raw 0..65535, implementation-data-type=uint16
      symbol props SymbolProps: symbol=SOMEIPTestabilityReliable_echoUInt16_inUInt16_type
    echoUInt16_outUInt16_type: range phys 0..65535, raw 0..65535, implementation-data-type=uint16
      symbol props SymbolProps: symbol=SOMEIPTestabilityReliable_echoUInt16_outUInt16_type
    echoUInt32_inUInt32_type: range phys 0..4294967295, raw 0..4294967295, implementation-data-type=uint32
      symbol props SymbolProps: symbol=SOMEIPTestabilityReliable_echoUInt32_inUInt32_type
    echoUInt32_outUInt32_type: range phys 0..4294967295, raw 0..4294967295, implementation-data-type=uint32
      symbol props SymbolProps: symbol=SOMEIPTestabilityReliable_echoUInt32_outUInt32_type
    echoUInt64_inUInt64_type: range phys 0..18446744073709551615, raw 0..18446744073709551615, implementation-data-type=uint64
      symbol props SymbolProps: symbol=SOMEIPTestabilityReliable_echoUInt64_inUInt64_type
    echoUInt64_outUInt64_type: range phys 0..18446744073709551615, raw 0..18446744073709551615, implementation-data-type=uint64
      symbol props SymbolProps: symbol=SOMEIPTestabilityReliable_echoUInt64_outUInt64_type
    SOMEIPTestabilityReliable_echoUInt8UInt16UInt32_inUInt16_type: range phys 0..65535, raw 0..65535, implementation-data-type=uint16
      symbol props SymbolProps: symbol=SOMEIPTestabilityReliable_echoUInt8UInt16UInt32_inUInt16_type
    SOMEIPTestabilityReliable_echoUInt8UInt16UInt32_inUInt32_type: range phys 0..4294967295, raw 0..4294967295, implementation-data-type=uint32
      symbol props SymbolProps: symbol=SOMEIPTestabilityReliable_echoUInt8UInt16UInt32_inUInt32_type
    SOMEIPTestabilityReliable_echoUInt8UInt16UInt32_inUInt8_type: range phys 0..255, raw 0..255, implementation-data-type=uint8
      symbol props SymbolProps: symbol=SOMEIPTestabilityReliable_echoUInt8UInt16UInt32_inUInt8_type
    SOMEIPTestabilityReliable_echoUInt8UInt16UInt32_outUInt16_type: range phys 0..65535, raw 0..65535, implementation-data-type=uint16
      symbol props SymbolProps: symbol=SOMEIPTestabilityReliable_echoUInt8UInt16UInt32_outUInt16_type
    SOMEIPTestabilityReliable_echoUInt8UInt16UInt32_outUInt32_type: range phys 0..4294967295, raw 0..4294967295, implementation-data-type=uint32
      symbol props SymbolProps: symbol=SOMEIPTestabilityReliable_echoUInt8UInt16UInt32_outUInt32_type
    SOMEIPTestabilityReliable_echoUInt8UInt16UInt32_outUInt8_type: range phys 0..255, raw 0..255, implementation-data-type=uint8
      symbol props SymbolProps: symbol=SOMEIPTestabilityReliable_echoUInt8UInt16UInt32_outUInt8_type
    SOMEIPTestabilityReliable_echoUInt8_inUInt8_type: range phys 0..255, raw 0..255, implementation-data-type=uint8
      symbol props SymbolProps: symbol=SOMEIPTestabilityReliable_echoUInt8_inUInt8_type
    SOMEIPTestabilityReliable_echoUInt8_outUInt8_type: range phys 0..255, raw 0..255, implementation-data-type=uint8
      symbol props SymbolProps: symbol=SOMEIPTestabilityReliable_echoUInt8_outUInt8_type
    echoUTF8String_inString_type: category=STRUCTURE, dynamic-array-size-profile=VSA_LINEAR
      element size: implementation-data-type=uint8
      element string: category=ARRAY
        element character: array-size=64, array-size-handling=ALL-INDICES-SAME-ARRAY-SIZE, array-size-semantics=VARIABLE-SIZE, implementation-data-type=uint8
      symbol props SymbolProps: symbol=SOMEIPTestabilityReliable_echoUTF8String_inString_type
    echoUTF8String_outString_type: category=STRUCTURE, dynamic-array-size-profile=VSA_LINEAR
      element size: implementation-data-type=uint8
      element string: category=ARRAY
        element character: array-size=64, array-size-handling=ALL-INDICES-SAME-ARRAY-SIZE, array-size-semantics=VARIABLE-SIZE, implementation-data-type=uint8
      symbol props SymbolProps: symbol=SOMEIPTestabilityReliable_echoUTF8String_outString_type
    enableSubscription_eventGroupId_type: range phys 0..65535, raw 0..65535, implementation-data-type=uint16
      symbol props SymbolProps: symbol=SOMEIPTestabilityReliable_enableSubscription_eventGroupId_type
    getLastValueEventUInt8_outEventValue_type: range phys 0..255, raw 0..255, implementation-data-type=uint8
      symbol props SymbolProps: symbol=SOMEIPTestabilityReliable_getLastValueEventUInt8_outEventValue_type
    getLastValueFieldMulticast_lastValue_type: range phys 0..65535, raw 0..65535, implementation-data-type=uint16
      symbol props SymbolProps: symbol=SOMEIPTestabilityReliable_getLastValueFieldMulticast_lastValue_type
    getSupportedFunctions_ids: category=STRUCTURE, dynamic-array-size-profile=VSA_LINEAR
      element size: implementation-data-type=uint8
      element payload: category=ARRAY
        element getSupportedFunctions_ids_base_type: array-size=128, array-size-handling=ALL-INDICES-SAME-ARRAY-SIZE, array-size-semantics=VARIABLE-SIZE, implementation-data-type=getSupportedFunctions_ids_base_type
      symbol props SymbolProps: symbol=SOMEIPTestabilityReliable_getSupportedFunctions_ids
    getSupportedFunctions_ids_base_type: range phys 0..65535, raw 0..65535, implementation-data-type=uint16
      symbol props SymbolProps: symbol=SOMEIPTestabilityReliable_getSupportedFunctions_ids_base_type
    SOMEIPTestabilityReliable_noResponseUInt8_inUInt8_type: range phys 0..255, raw 0..255, implementation-data-type=uint8
      symbol props SymbolProps: symbol=SOMEIPTestabilityReliable_noResponseUInt8_inUInt8_type
    resetInterface_delay_type: range phys 0..255, raw 0..255, implementation-data-type=uint8
      symbol props SymbolProps: symbol=SOMEIPTestabilityReliable_resetInterface_delay_type
    SOMEIPTestabilityReliable_testEventUInt8_data_type: range phys 0..255, raw 0..255, implementation-data-type=uint8
      symbol props SymbolProps: symbol=SOMEIPTestabilityReliable_testEventUInt8_data_type
    triggerEchoComplexDynamicArray_arg1ComplexDynArray: category=STRUCTURE, dynamic-array-size-profile=VSA_LINEAR
      element size: implementation-data-type=uint8
      element payload: category=ARRAY
        element AT_TestStruct: array-size=5, array-size-handling=ALL-INDICES-SAME-ARRAY-SIZE, array-size-semantics=VARIABLE-SIZE, implementation-data-type=SOMEIPTestabilityReliable_AT_TestStruct
      symbol props SymbolProps: symbol=SOMEIPTestabilityReliable_triggerEchoComplexDynamicArray_arg1ComplexDynArray
    triggerEchoFloat32_arg1Float32_type: range phys -1000..1000, raw -1000..1000, implementation-data-type=float32
      symbol props SymbolProps: symbol=SOMEIPTestabilityReliable_triggerEchoFloat32_arg1Float32_type
    triggerEchoUInt8_inUInt8_type: range phys 0..255, raw 0..255, implementation-data-type=uint8
      symbol props SymbolProps: symbol=SOMEIPTestabilityReliable_triggerEchoUInt8_inUInt8_type
    triggerEventUInt8_n_type: range phys 0..255, raw 0..255, implementation-data-type=uint8
      symbol props SymbolProps: symbol=SOMEIPTestabilityReliable_triggerEventUInt8_n_type
    triggerFieldMulticast_n_type: range phys 0..1141, raw 0..1141, implementation-data-type=uint16
      symbol props SymbolProps: symbol=SOMEIPTestabilityReliable_triggerFieldMulticast_n_type
    triggerFireForgetUInt8_inUInt8_type: range phys 0..255, raw 0..255, implementation-data-type=uint8
      symbol props SymbolProps: symbol=SOMEIPTestabilityReliable_triggerFireForgetUInt8_inUInt8_type
    triggerSetterUInt8_inUInt8_type: range phys 0..255, raw 0..255, implementation-data-type=uint8
      symbol props SymbolProps: symbol=SOMEIPTestabilityReliable_triggerSetterUInt8_inUInt8_type
  12 x application array data type, all with category=ARRAY:
    SOMEIPTestabilityReliable_echoComplexDynamicArray_inArrayApp: dynamic-array-size-profile=VSA_LINEAR
      element AT_TestStruct: category=VALUE, type=SOMEIPTestabilityReliable_AT_TestStructApp, array-size-handling=ALL-INDICES-SAME-ARRAY-SIZE, array-size-semantics=VARIABLE-SIZE, max-number-of-elements=5
    SOMEIPTestabilityReliable_echoComplexDynamicArray_outArrayApp: dynamic-array-size-profile=VSA_LINEAR
      element AT_TestStruct: category=VALUE, type=SOMEIPTestabilityReliable_AT_TestStructApp, array-size-handling=ALL-INDICES-SAME-ARRAY-SIZE, array-size-semantics=VARIABLE-SIZE, max-number-of-elements=5
    echoInverseDynamicArray_inArrayApp: dynamic-array-size-profile=VSA_LINEAR
      element echoInverseDynamicArray_inArray_base_type: category=VALUE, type=echoInverseDynamicArray_inArray_base_typeApp, array-size-handling=ALL-INDICES-SAME-ARRAY-SIZE, array-size-semantics=VARIABLE-SIZE, max-number-of-elements=5
    echoInverseDynamicArray_outArrayApp: dynamic-array-size-profile=VSA_LINEAR
      element echoInverseDynamicArray_outArray_base_type: category=VALUE, type=echoInverseDynamicArray_outArray_base_typeApp, array-size-handling=ALL-INDICES-SAME-ARRAY-SIZE, array-size-semantics=VARIABLE-SIZE, max-number-of-elements=5
    echoInverseDynamicMultidimensionalArray_inArray_Sub1App: dynamic-array-size-profile=VSA_LINEAR
      element echoInverseDynamicMultidimensionalArray_inArray_Sub1_base_type: category=VALUE, type=echoInverseDynamicMultidimensionalArray_inArray_Sub1_base_typeApp, array-size-handling=ALL-INDICES-SAME-ARRAY-SIZE, array-size-semantics=VARIABLE-SIZE, max-number-of-elements=5
    echoInverseDynamicMultidimensionalArray_inArrayApp: dynamic-array-size-profile=VSA_FULLY_FLEXIBLE
      element echoInverseDynamicMultidimensionalArray_inArray_Sub1: category=VALUE, type=echoInverseDynamicMultidimensionalArray_inArray_Sub1App, array-size-handling=ALL-INDICES-DIFFERENT-ARRAY-SIZE, array-size-semantics=VARIABLE-SIZE, max-number-of-elements=5
    echoInverseDynamicMultidimensionalArray_outArray_Sub1App: dynamic-array-size-profile=VSA_LINEAR
      element echoInverseDynamicMultidimensionalArray_outArray_Sub1_base_type: category=VALUE, type=echoInverseDynamicMultidimensionalArray_outArray_Sub1_base_typeApp, array-size-handling=ALL-INDICES-SAME-ARRAY-SIZE, array-size-semantics=VARIABLE-SIZE, max-number-of-elements=5
    echoInverseDynamicMultidimensionalArray_outArrayApp: dynamic-array-size-profile=VSA_FULLY_FLEXIBLE
      element echoInverseDynamicMultidimensionalArray_outArray_Sub1: category=VALUE, type=echoInverseDynamicMultidimensionalArray_outArray_Sub1App, array-size-handling=ALL-INDICES-DIFFERENT-ARRAY-SIZE, array-size-semantics=VARIABLE-SIZE, max-number-of-elements=5
    getSupportedFunctions_idsApp: dynamic-array-size-profile=VSA_LINEAR
      element getSupportedFunctions_ids_base_type: category=VALUE, type=getSupportedFunctions_ids_base_typeApp, array-size-handling=ALL-INDICES-SAME-ARRAY-SIZE, array-size-semantics=VARIABLE-SIZE, max-number-of-elements=128
    SOMEIPTestabilityReliable_TestComplexStruct_cApp: dynamic-array-size-profile=VSA_LINEAR
      element TestComplexStruct_c_base_type: category=VALUE, type=SOMEIPTestabilityReliable_TestComplexStruct_c_base_typeApp, array-size-handling=ALL-INDICES-SAME-ARRAY-SIZE, array-size-semantics=VARIABLE-SIZE, max-number-of-elements=5
    triggerEchoComplexDynamicArray_arg1ComplexDynArrayApp: dynamic-array-size-profile=VSA_LINEAR
      element AT_TestStruct: category=VALUE, type=SOMEIPTestabilityReliable_AT_TestStructApp, array-size-handling=ALL-INDICES-SAME-ARRAY-SIZE, array-size-semantics=VARIABLE-SIZE, max-number-of-elements=5
    SOMEIPTestabilityReliable_UUIDAppApp
      element uint8: category=VALUE, type=SOMEIPTestabilityReliable_uint8App, array-size-semantics=FIXED-SIZE, max-number-of-elements=16
  77 x app type:
    activateTsClient_startDelay_typeApp: category=VALUE, compu {identical}, range phys 0..255, raw 0..255
    AT_EnumOperationTypeApp: category=VALUE, compu-method=AT_EnumOperationTypeCM, range raw 0..1
    AT_EnumTsClientTypeApp: category=VALUE, compu-method=AT_EnumTsClientTypeCM, range raw 0..4
    checkByteOrder_inUInt16_typeApp: category=VALUE, compu {identical}, range phys 0..65535, raw 0..65535
    checkByteOrder_inUInt32_typeApp: category=VALUE, compu {identical}, range phys 0..4294967295, raw 0..4294967295
    checkByteOrder_outUInt16_typeApp: category=VALUE, compu {identical}, range phys 0..65535, raw 0..65535
    checkByteOrder_outUInt32_typeApp: category=VALUE, compu {identical}, range phys 0..4294967295, raw 0..4294967295
    deactivateTsClient_delay_typeApp: category=VALUE, compu {identical}, range phys 0..255, raw 0..255
    SOMEIPTestabilityReliable_echoFloat32_inFloat32_typeApp: category=VALUE, compu {identical}, range phys -1000..1000, raw -1000..1000, sw-intended-resolution=0.00001
    SOMEIPTestabilityReliable_echoFloat32_outFloat32_typeApp: category=VALUE, compu {identical}, range phys -1000..1000, raw -1000..1000, sw-intended-resolution=0.00001
    echoFloat64_inFloat64_typeApp: category=VALUE, compu {identical}, range phys -10000..10000, raw -10000..10000, sw-intended-resolution=1E-10
    echoFloat64_outFloat64_typeApp: category=VALUE, compu {identical}, range phys -10000..10000, raw -10000..10000, sw-intended-resolution=1E-10
    echoInverseBitField_inBitfield1_typeApp: category=VALUE, compu {identical}, range phys 0..255, raw 0..255
    echoInverseBitField_inBitfield2_typeApp: category=VALUE, compu {identical}, range phys 0..255, raw 0..255
    echoInverseBitField_outBitfield1_typeApp: category=VALUE, compu {identical}, range phys 0..255, raw 0..255
    echoInverseBitField_outBitfield2_typeApp: category=VALUE, compu {identical}, range phys 0..255, raw 0..255
    echoInverseDynamicArray_inArray_base_typeApp: category=VALUE, compu {identical}, range phys 0..255, raw 0..255
    echoInverseDynamicArray_outArray_base_typeApp: category=VALUE, compu {identical}, range phys 0..255, raw 0..255
    echoInverseDynamicMultidimensionalArray_inArray_Sub1_base_typeApp: category=VALUE, compu {identical}, range phys 0..255, raw 0..255
    echoInverseDynamicMultidimensionalArray_outArray_Sub1_base_typeApp: category=VALUE, compu {identical}, range phys 0..255, raw 0..255
    echoSInt16_inSInt16_typeApp: category=VALUE, compu {identical}, range phys -32768..32767, raw -32768..32767
    echoSInt16_outSInt16_typeApp: category=VALUE, compu {identical}, range phys -32768..32767, raw -32768..32767
    echoSInt32_inSInt32_typeApp: category=VALUE, compu {identical}, range phys -2147483648..2147483647, raw -2147483648..2147483647
    echoSInt32_outSInt32_typeApp: category=VALUE, compu {identical}, range phys -2147483648..2147483647, raw -2147483648..2147483647
    echoSInt64_inSInt64_typeApp: category=VALUE, compu {identical}, range phys -9223372036854775808..9223372036854775807, raw -9223372036854775808..9223372036854775807
    echoSInt64_outSInt64_typeApp: category=VALUE, compu {identical}, range phys -9223372036854775808..-9223372036854775807, raw -9223372036854775808..-9223372036854775807
    echoSInt8_inSInt8_typeApp: category=VALUE, compu {identical}, range phys -128..127, raw -128..127
    echoSInt8_outSInt8_typeApp: category=VALUE, compu {identical}, range phys -128..127, raw -128..127
    echoUInt16_inUInt16_typeApp: category=VALUE, compu {identical}, range phys 0..65535, raw 0..65535
    echoUInt16_outUInt16_typeApp: category=VALUE, compu {identical}, range phys 0..65535, raw 0..65535
    echoUInt32_inUInt32_typeApp: category=VALUE, compu {identical}, range phys 0..4294967295, raw 0..4294967295
    echoUInt32_outUInt32_typeApp: category=VALUE, compu {identical}, range phys 0..4294967295, raw 0..4294967295
    echoUInt64_inUInt64_typeApp: category=VALUE, compu {identical}, range phys 0..18446744073709551615, raw 0..18446744073709551615
    echoUInt64_outUInt64_typeApp: category=VALUE, compu {identical}, range phys 0..18446744073709551615, raw 0..18446744073709551615
    SOMEIPTestabilityReliable_echoUInt8_inUInt8_typeApp: category=VALUE, compu {identical}, range phys 0..255, raw 0..255
    SOMEIPTestabilityReliable_echoUInt8_outUInt8_typeApp: category=VALUE, compu {identical}, range phys 0..255, raw 0..255
    SOMEIPTestabilityReliable_echoUInt8UInt16UInt32_inUInt16_typeApp: category=VALUE, compu {identical}, range phys 0..65535, raw 0..65535
    SOMEIPTestabilityReliable_echoUInt8UInt16UInt32_inUInt32_typeApp: category=VALUE, compu {identical}, range phys 0..4294967295, raw 0..4294967295
    SOMEIPTestabilityReliable_echoUInt8UInt16UInt32_inUInt8_typeApp: category=VALUE, compu {identical}, range phys 0..255, raw 0..255
    SOMEIPTestabilityReliable_echoUInt8UInt16UInt32_outUInt16_typeApp: category=VALUE, compu {identical}, range phys 0..65535, raw 0..65535
    SOMEIPTestabilityReliable_echoUInt8UInt16UInt32_outUInt32_typeApp: category=VALUE, compu {identical}, range phys 0..4294967295, raw 0..4294967295
    SOMEIPTestabilityReliable_echoUInt8UInt16UInt32_outUInt8_typeApp: category=VALUE, compu {identical}, range phys 0..255, raw 0..255
    enableSubscription_eventGroupId_typeApp: category=VALUE, compu {identical}, range phys 0..65535, raw 0..65535
    getLastValueEventUInt8_outEventValue_typeApp: category=VALUE, compu {identical}, range phys 0..255, raw 0..255
    getLastValueFieldMulticast_lastValue_typeApp: category=VALUE, compu {identical}, range phys 0..65535, raw 0..65535
    getSupportedFunctions_ids_base_typeApp: category=VALUE, compu {identical}, range phys 0..65535, raw 0..65535
    SOMEIPTestabilityReliable_noResponseUInt8_inUInt8_typeApp: category=VALUE, compu {identical}, range phys 0..255, raw 0..255
    resetInterface_delay_typeApp: category=VALUE, compu {identical}, range phys 0..255, raw 0..255
    SOMEIPTestabilityReliable_RnRTestStructThreeArguments_rnrArg1_typeApp: category=VALUE, compu {identical}, range phys 0..255, raw 0..255
    SOMEIPTestabilityReliable_RnRTestStructThreeArguments_rnrArg2_typeApp: category=VALUE, compu {identical}, range phys 0..65535, raw 0..65535
    SOMEIPTestabilityReliable_RnRTestStructThreeArguments_rnrArg3_typeApp: category=VALUE, compu {identical}, range phys 0..4294967295, raw 0..4294967295
    RnRTriggerEchoLDACmdType_numElements_typeApp: category=VALUE, compu {identical}, range phys 0..1141, raw 0..1141
    SOMEIPTestabilityReliable_activateTsClient_ReturnApp: category=VALUE, compu-method=SOMEIPTestabilityReliable_activateTsClient_ReturnCM, range raw 33
    SOMEIPTestabilityReliable_deactivateTsClient_ReturnApp: category=VALUE, compu-method=SOMEIPTestabilityReliable_deactivateTsClient_ReturnCM, range raw 34
    SOMEIPTestabilityReliable_enableSubscription_ReturnApp: category=VALUE, compu-method=SOMEIPTestabilityReliable_enableSubscription_ReturnCM, range raw 32
    SOMEIPTestabilityReliable_resetInterface_ReturnApp: category=VALUE, compu-method=SOMEIPTestabilityReliable_resetInterface_ReturnCM, range raw 35
    SOMEIPTestabilityReliable_TestComplexStruct_a_typeApp: category=VALUE, compu {identical}, range phys 0..255, raw 0..255
    SOMEIPTestabilityReliable_TestComplexStruct_c_base_typeApp: category=VALUE, compu {identical}, range phys 0..255, raw 0..255
    SOMEIPTestabilityReliable_testEventUInt8_data_typeApp: category=VALUE, compu {identical}, range phys 0..255, raw 0..255
    TestFieldUInt64_typeApp: category=VALUE, compu {identical}, range phys 0..18446744073709551615, raw 0..18446744073709551615
    SOMEIPTestabilityReliable_TestFieldUInt8_typeApp: category=VALUE, compu {identical}, range phys 0..255, raw 0..255
    SOMEIPTestabilityReliable_TestStruct_a_typeApp: category=VALUE, compu {identical}, range phys 0..255, raw 0..255
    SOMEIPTestabilityReliable_TestStruct_b_typeApp: category=VALUE, compu {identical}, range phys 0..65535, raw 0..65535
    TestStructInStruct_a_typeApp: category=VALUE, compu {identical}, range phys 0..255, raw 0..255
    TestStructInStruct_b_typeApp: category=VALUE, compu {identical}, range phys 0..65535, raw 0..65535
    TestStructInStruct_c_typeApp: category=VALUE, compu {identical}, range phys 0..4294967295, raw 0..4294967295
    TestStructInStruct_d_typeApp: category=VALUE, compu {identical}, range phys -1000..1000, raw -1000..1000, sw-intended-resolution=0.00001
    triggerEchoFloat32_arg1Float32_typeApp: category=VALUE, compu {identical}, range phys -1000..1000, raw -1000..1000, sw-intended-resolution=0.00001
    triggerEchoUInt8_inUInt8_typeApp: category=VALUE, compu {identical}, range phys 0..255, raw 0..255
    triggerEventUInt8_n_typeApp: category=VALUE, compu {identical}, range phys 0..255, raw 0..255
    triggerFieldMulticast_n_typeApp: category=VALUE, compu {identical}, range phys 0..1141, raw 0..1141
    triggerFireForgetUInt8_inUInt8_typeApp: category=VALUE, compu {identical}, range phys 0..255, raw 0..255
    triggerSetterUInt8_inUInt8_typeApp: category=VALUE, compu {identical}, range phys 0..255, raw 0..255
    SOMEIPTestabilityReliable_uint8App: category=VALUE
    echoUTF8String_inString_typeApp: category=STRING, sw-text-props={array-size-semantics=VARIABLE-SIZE, sw-max-text-size=16, base-type=string}, sw-record-layout=StringDescriptor
    echoUTF8String_outString_typeApp: category=STRING, sw-text-props={array-size-semantics=VARIABLE-SIZE, sw-max-text-size=16, base-type=string}, sw-record-layout=StringDescriptor
    SOMEIPTestabilityReliable_TestComplexStruct_b_typeApp: category=STRING, sw-text-props={array-size-semantics=VARIABLE-SIZE, sw-max-text-size=16, base-type=string}, sw-record-layout=StringDescriptor
  5 x application record data type, all with category=STRUCTURE:
    SOMEIPTestabilityReliable_AT_RnRTestStructThreeArgumentsApp
      application record element rnrArg{1..3}: category=VALUE, type=SOMEIPTestabilityReliable_RnRTestStructThreeArguments_rnrArg{1..3}_typeApp
    AT_RnRTriggerEchoLDACmdTypeApp
      application record element client: category=VALUE, type=AT_EnumTsClientTypeApp
      application record element numElements: category=VALUE, type=RnRTriggerEchoLDACmdType_numElements_typeApp
    SOMEIPTestabilityReliable_AT_TestComplexStructApp
      application record element a: category=VALUE, type=SOMEIPTestabilityReliable_TestComplexStruct_a_typeApp
      application record element b: category=STRING, type=SOMEIPTestabilityReliable_TestComplexStruct_b_typeApp
      application record element c: category=ARRAY, type=SOMEIPTestabilityReliable_TestComplexStruct_cApp
    SOMEIPTestabilityReliable_AT_TestStructApp
      application record element a: category=VALUE, type=SOMEIPTestabilityReliable_TestStruct_a_typeApp
      application record element b: category=VALUE, type=SOMEIPTestabilityReliable_TestStruct_b_typeApp
    AT_TestStructInStructApp
      5 x application record element:
        a: category=VALUE, type=TestStructInStruct_a_typeApp
        b: category=VALUE, type=TestStructInStruct_b_typeApp
        c: category=VALUE, type=TestStructInStruct_c_typeApp
        d: category=VALUE, type=TestStructInStruct_d_typeApp
        e: category=STRUCTURE, type=SOMEIPTestabilityReliable_AT_TestStructApp
package /vwg/services/SOMEIPTestabilityReliable/deployment
  data type mapping set SOMEIPTestabilityReliableMappings
    data-type-maps:
      application-data-type=SOMEIPTestabilityReliable_echoComplexDynamicArray_inArrayApp, implementation-data-type=SOMEIPTestabilityReliable_echoComplexDynamicArray_inArray
      application-data-type=SOMEIPTestabilityReliable_echoComplexDynamicArray_outArrayApp, implementation-data-type=SOMEIPTestabilityReliable_echoComplexDynamicArray_outArray
      application-data-type=echoInverseDynamicArray_inArrayApp, implementation-data-type=echoInverseDynamicArray_inArray
      application-data-type=echoInverseDynamicArray_outArrayApp, implementation-data-type=echoInverseDynamicArray_outArray
      application-data-type=echoInverseDynamicMultidimensionalArray_inArrayApp, implementation-data-type=echoInverseDynamicMultidimensionalArray_inArray
      application-data-type=echoInverseDynamicMultidimensionalArray_outArrayApp, implementation-data-type=echoInverseDynamicMultidimensionalArray_outArray
      application-data-type=getSupportedFunctions_idsApp, implementation-data-type=getSupportedFunctions_ids
      application-data-type=SOMEIPTestabilityReliable_TestComplexStruct_cApp, implementation-data-type=SOMEIPTestabilityReliable_TestComplexStruct_c
      application-data-type=triggerEchoComplexDynamicArray_arg1ComplexDynArrayApp, implementation-data-type=triggerEchoComplexDynamicArray_arg1ComplexDynArray
      application-data-type=SOMEIPTestabilityReliable_UUIDAppApp, implementation-data-type=SOMEIPTestabilityReliable_UUIDApp
      application-data-type=activateTsClient_startDelay_typeApp, implementation-data-type=activateTsClient_startDelay_type
      application-data-type=AT_EnumOperationTypeApp, implementation-data-type=AT_EnumOperationType
      application-data-type=AT_EnumTsClientTypeApp, implementation-data-type=AT_EnumTsClientType
      application-data-type=checkByteOrder_inUInt16_typeApp, implementation-data-type=checkByteOrder_inUInt16_type
      application-data-type=checkByteOrder_inUInt32_typeApp, implementation-data-type=checkByteOrder_inUInt32_type
      application-data-type=checkByteOrder_outUInt16_typeApp, implementation-data-type=checkByteOrder_outUInt16_type
      application-data-type=checkByteOrder_outUInt32_typeApp, implementation-data-type=checkByteOrder_outUInt32_type
      application-data-type=deactivateTsClient_delay_typeApp, implementation-data-type=deactivateTsClient_delay_type
      application-data-type=SOMEIPTestabilityReliable_echoFloat32_inFloat32_typeApp, implementation-data-type=SOMEIPTestabilityReliable_echoFloat32_inFloat32_type
      application-data-type=SOMEIPTestabilityReliable_echoFloat32_outFloat32_typeApp, implementation-data-type=SOMEIPTestabilityReliable_echoFloat32_outFloat32_type
      application-data-type=echoFloat64_inFloat64_typeApp, implementation-data-type=echoFloat64_inFloat64_type
      application-data-type=echoFloat64_outFloat64_typeApp, implementation-data-type=echoFloat64_outFloat64_type
      application-data-type=echoInverseBitField_inBitfield1_typeApp, implementation-data-type=echoInverseBitField_inBitfield1_type
      application-data-type=echoInverseBitField_inBitfield2_typeApp, implementation-data-type=echoInverseBitField_inBitfield2_type
      application-data-type=echoInverseBitField_outBitfield1_typeApp, implementation-data-type=echoInverseBitField_outBitfield1_type
      application-data-type=echoInverseBitField_outBitfield2_typeApp, implementation-data-type=echoInverseBitField_outBitfield2_type
      application-data-type=echoInverseDynamicArray_inArray_base_typeApp, implementation-data-type=echoInverseDynamicArray_inArray_base_type
      application-data-type=echoInverseDynamicArray_outArray_base_typeApp, implementation-data-type=echoInverseDynamicArray_outArray_base_type
      application-data-type=echoSInt16_inSInt16_typeApp, implementation-data-type=echoSInt16_inSInt16_type
      application-data-type=echoSInt16_outSInt16_typeApp, implementation-data-type=echoSInt16_outSInt16_type
      application-data-type=echoSInt32_inSInt32_typeApp, implementation-data-type=echoSInt32_inSInt32_type
      application-data-type=echoSInt32_outSInt32_typeApp, implementation-data-type=echoSInt32_outSInt32_type
      application-data-type=echoSInt64_inSInt64_typeApp, implementation-data-type=echoSInt64_inSInt64_type
      application-data-type=echoSInt64_outSInt64_typeApp, implementation-data-type=echoSInt64_outSInt64_type
      application-data-type=echoSInt8_inSInt8_typeApp, implementation-data-type=echoSInt8_inSInt8_type
      application-data-type=echoSInt8_outSInt8_typeApp, implementation-data-type=echoSInt8_outSInt8_type
      application-data-type=echoUInt16_inUInt16_typeApp, implementation-data-type=echoUInt16_inUInt16_type
      application-data-type=echoUInt16_outUInt16_typeApp, implementation-data-type=echoUInt16_outUInt16_type
      application-data-type=echoUInt32_inUInt32_typeApp, implementation-data-type=echoUInt32_inUInt32_type
      application-data-type=echoUInt32_outUInt32_typeApp, implementation-data-type=echoUInt32_outUInt32_type
      application-data-type=echoUInt64_inUInt64_typeApp, implementation-data-type=echoUInt64_inUInt64_type
      application-data-type=echoUInt64_outUInt64_typeApp, implementation-data-type=echoUInt64_outUInt64_type
      application-data-type=SOMEIPTestabilityReliable_echoUInt8_inUInt8_typeApp, implementation-data-type=SOMEIPTestabilityReliable_echoUInt8_inUInt8_type
      application-data-type=SOMEIPTestabilityReliable_echoUInt8_outUInt8_typeApp, implementation-data-type=SOMEIPTestabilityReliable_echoUInt8_outUInt8_type
      application-data-type=SOMEIPTestabilityReliable_echoUInt8UInt16UInt32_inUInt16_typeApp, implementation-data-type=SOMEIPTestabilityReliable_echoUInt8UInt16UInt32_inUInt16_type
      application-data-type=SOMEIPTestabilityReliable_echoUInt8UInt16UInt32_inUInt32_typeApp, implementation-data-type=SOMEIPTestabilityReliable_echoUInt8UInt16UInt32_inUInt32_type
      application-data-type=SOMEIPTestabilityReliable_echoUInt8UInt16UInt32_inUInt8_typeApp, implementation-data-type=SOMEIPTestabilityReliable_echoUInt8UInt16UInt32_inUInt8_type
      application-data-type=SOMEIPTestabilityReliable_echoUInt8UInt16UInt32_outUInt16_typeApp, implementation-data-type=SOMEIPTestabilityReliable_echoUInt8UInt16UInt32_outUInt16_type
      application-data-type=SOMEIPTestabilityReliable_echoUInt8UInt16UInt32_outUInt32_typeApp, implementation-data-type=SOMEIPTestabilityReliable_echoUInt8UInt16UInt32_outUInt32_type
      application-data-type=SOMEIPTestabilityReliable_echoUInt8UInt16UInt32_outUInt8_typeApp, implementation-data-type=SOMEIPTestabilityReliable_echoUInt8UInt16UInt32_outUInt8_type
      application-data-type=enableSubscription_eventGroupId_typeApp, implementation-data-type=enableSubscription_eventGroupId_type
      application-data-type=getLastValueEventUInt8_outEventValue_typeApp, implementation-data-type=getLastValueEventUInt8_outEventValue_type
      application-data-type=getLastValueFieldMulticast_lastValue_typeApp, implementation-data-type=getLastValueFieldMulticast_lastValue_type
      application-data-type=getSupportedFunctions_ids_base_typeApp, implementation-data-type=getSupportedFunctions_ids_base_type
      application-data-type=SOMEIPTestabilityReliable_noResponseUInt8_inUInt8_typeApp, implementation-data-type=SOMEIPTestabilityReliable_noResponseUInt8_inUInt8_type
      application-data-type=resetInterface_delay_typeApp, implementation-data-type=resetInterface_delay_type
      application-data-type=SOMEIPTestabilityReliable_RnRTestStructThreeArguments_rnrArg{1..3}_typeApp, implementation-data-type=SOMEIPTestabilityReliable_RnRTestStructThreeArguments_rnrArg{1..3}_type
      application-data-type=RnRTriggerEchoLDACmdType_numElements_typeApp, implementation-data-type=RnRTriggerEchoLDACmdType_numElements_type
      application-data-type=SOMEIPTestabilityReliable_activateTsClient_ReturnApp, implementation-data-type=SOMEIPTestabilityReliable_activateTsClient_Return
      application-data-type=SOMEIPTestabilityReliable_deactivateTsClient_ReturnApp, implementation-data-type=SOMEIPTestabilityReliable_deactivateTsClient_Return
      application-data-type=SOMEIPTestabilityReliable_enableSubscription_ReturnApp, implementation-data-type=SOMEIPTestabilityReliable_enableSubscription_Return
      application-data-type=SOMEIPTestabilityReliable_resetInterface_ReturnApp, implementation-data-type=SOMEIPTestabilityReliable_resetInterface_Return
      application-data-type=SOMEIPTestabilityReliable_TestComplexStruct_a_typeApp, implementation-data-type=SOMEIPTestabilityReliable_TestComplexStruct_a_type
      application-data-type=SOMEIPTestabilityReliable_TestComplexStruct_c_base_typeApp, implementation-data-type=SOMEIPTestabilityReliable_TestComplexStruct_c_base_type
      application-data-type=SOMEIPTestabilityReliable_testEventUInt8_data_typeApp, implementation-data-type=SOMEIPTestabilityReliable_testEventUInt8_data_type
      application-data-type=TestFieldUInt64_typeApp, implementation-data-type=TestFieldUInt64_type
      application-data-type=SOMEIPTestabilityReliable_TestFieldUInt8_typeApp, implementation-data-type=SOMEIPTestabilityReliable_TestFieldUInt8_type
      application-data-type=SOMEIPTestabilityReliable_TestStruct_a_typeApp, implementation-data-type=SOMEIPTestabilityReliable_TestStruct_a_type
      application-data-type=SOMEIPTestabilityReliable_TestStruct_b_typeApp, implementation-data-type=SOMEIPTestabilityReliable_TestStruct_b_type
      application-data-type=TestStructInStruct_a_typeApp, implementation-data-type=TestStructInStruct_a_type
      application-data-type=TestStructInStruct_b_typeApp, implementation-data-type=TestStructInStruct_b_type
      application-data-type=TestStructInStruct_c_typeApp, implementation-data-type=TestStructInStruct_c_type
      application-data-type=TestStructInStruct_d_typeApp, implementation-data-type=TestStructInStruct_d_type
      application-data-type=triggerEchoFloat32_arg1Float32_typeApp, implementation-data-type=triggerEchoFloat32_arg1Float32_type
      application-data-type=triggerEchoUInt8_inUInt8_typeApp, implementation-data-type=triggerEchoUInt8_inUInt8_type
      application-data-type=triggerEventUInt8_n_typeApp, implementation-data-type=triggerEventUInt8_n_type
      application-data-type=triggerFieldMulticast_n_typeApp, implementation-data-type=triggerFieldMulticast_n_type
      application-data-type=triggerFireForgetUInt8_inUInt8_typeApp, implementation-data-type=triggerFireForgetUInt8_inUInt8_type
      application-data-type=triggerSetterUInt8_inUInt8_typeApp, implementation-data-type=triggerSetterUInt8_inUInt8_type
      application-data-type=SOMEIPTestabilityReliable_uint8App, implementation-data-type=uint8
      application-data-type=echoUTF8String_inString_typeApp, implementation-data-type=echoUTF8String_inString_type
      application-data-type=echoUTF8String_outString_typeApp, implementation-data-type=echoUTF8String_outString_type
      application-data-type=SOMEIPTestabilityReliable_TestComplexStruct_b_typeApp, implementation-data-type=SOMEIPTestabilityReliable_TestComplexStruct_b_type
      application-data-type=SOMEIPTestabilityReliable_AT_RnRTestStructThreeArgumentsApp, implementation-data-type=SOMEIPTestabilityReliable_AT_RnRTestStructThreeArguments
      application-data-type=AT_RnRTriggerEchoLDACmdTypeApp, implementation-data-type=AT_RnRTriggerEchoLDACmdType
      application-data-type=SOMEIPTestabilityReliable_AT_TestComplexStructApp, implementation-data-type=SOMEIPTestabilityReliable_AT_TestComplexStruct
      application-data-type=SOMEIPTestabilityReliable_AT_TestStructApp, implementation-data-type=SOMEIPTestabilityReliable_AT_TestStruct
      application-data-type=AT_TestStructInStructApp, implementation-data-type=AT_TestStructInStruct
package /vwg/services/IdsCanSensor/datatypes
  compu method IdsCanSensor_AT_OperationStatusCM: 0=Cx0_success (IdsCanSensor_AT_OperationStatusCM_Cx0_success), 202=Cxca_accepted (IdsCanSensor_AT_OperationStatusCM_Cxca_accepted), 300=Cx12c_multiple_choice (IdsCanSensor_AT_OperationStatusCM_Cx12c_multiple_choice), 304=Cx130_not_modified (IdsCanSensor_AT_OperationStatusCM_Cx130_not_modified), 401=Cx191_unauthorized (IdsCanSensor_AT_OperationStatusCM_Cx191_unauthorized), 403=Cx193_forbidden (IdsCanSensor_AT_OperationStatusCM_Cx193_forbidden), 404=Cx194_not_found (IdsCanSensor_AT_OperationStatusCM_Cx194_not_found), 408=Cx198_request_time_out (IdsCanSensor_AT_OperationStatusCM_Cx198_request_time_out), 409=Cx199_conflict (IdsCanSensor_AT_OperationStatusCM_Cx199_conflict), 414=Cx19e_request_too_large (IdsCanSensor_AT_OperationStatusCM_Cx19e_request_too_large), 429=Cx1ad_too_many_requests (IdsCanSensor_AT_OperationStatusCM_Cx1ad_too_many_requests), 431=Cx1af_request_header_fields_too_large (IdsCanSensor_AT_OperationStatusCM_Cx1af_request_header_fields_too_large), 451=Cx1c3_unavailable_for_legal_reasons (IdsCanSensor_AT_OperationStatusCM_Cx1c3_unavailable_for_legal_reasons), 500=Cx1f4_internal_server_error (IdsCanSensor_AT_OperationStatusCM_Cx1f4_internal_server_error), 503=Cx1f7_service_unavailable (IdsCanSensor_AT_OperationStatusCM_Cx1f7_service_unavailable), 504=Cx1f8_gateway_time_out (IdsCanSensor_AT_OperationStatusCM_Cx1f8_gateway_time_out), 511=Cx1ff_network_authentication_required (IdsCanSensor_AT_OperationStatusCM_Cx1ff_network_authentication_required), 65534=Cxfffe_operation_timeout (IdsCanSensor_AT_OperationStatusCM_Cxfffe_operation_timeout), 65535=Cxffff_protocol_error (IdsCanSensor_AT_OperationStatusCM_Cxffff_protocol_error)
  48 x impl type:
    AT_AnomalyData: category=STRUCTURE
      5 x element, all with category=TYPE_REFERENCE:
        sensorIdentifier: implementation-data-type=AnomalyData_sensorIdentifier
        timestamp: implementation-data-type=AnomalyData_timestamp_type
        canIdentifierType: implementation-data-type=AnomalyData_canIdentifierType_type
        communicationServerIdentifier: implementation-data-type=AnomalyData_communicationServerIdentifier_type
        messagePayload: implementation-data-type=AnomalyData_messagePayload
      symbol props SymbolProps: symbol=IdsCanSensor_AT_AnomalyData
    AT_CanSensorFeaturesSet: category=STRUCTURE
      element availabilityBitfield: category=ARRAY, array-size-semantics=FIXED-SIZE
        element availabilityBitfieldArrayType: array-size=1, implementation-data-type=uint8
      element configurationSettings: implementation-data-type=AT_ConfigurationSettings
      symbol props SymbolProps: symbol=IdsCanSensor_AT_CanSensorFeaturesSet
    AT_CanSensorFeaturesType: category=STRUCTURE
      8 x element:
        availabilityBitfield: category=ARRAY, array-size-semantics=FIXED-SIZE
          element availabilityBitfieldArrayType: array-size=1, implementation-data-type=uint8
        configurationSettings: implementation-data-type=AT_ConfigurationSettings
        controlCommands: implementation-data-type=AT_ControlCommands
        protocalFrameData: implementation-data-type=AT_ProtocolFrameData
        anomalyData: implementation-data-type=AT_AnomalyData
        gatewayExceptionalData: implementation-data-type=AT_GatewayExceptionalData
        gatewayDiagnosticFilterEvent: implementation-data-type=AT_GatewayDiagnosticFilterEvent
        elementId: implementation-data-type=CanSensorFeaturesType_elementId_type
      symbol props SymbolProps: symbol=IdsCanSensor_AT_CanSensorFeaturesType
    AT_CanSensorFeaturesUndefine: category=STRUCTURE
      element availabilityBitfield: category=ARRAY, array-size-semantics=FIXED-SIZE
        element availabilityBitfieldArrayType: array-size=1, implementation-data-type=uint8
      element configurationSettings: implementation-data-type=boolean
      symbol props SymbolProps: symbol=IdsCanSensor_AT_CanSensorFeaturesUndefine
    AT_ConfigurationSettings: category=STRUCTURE
      element sensorIdentifier: implementation-data-type=ConfigurationSettings_sensorIdentifier
      element timestamp: implementation-data-type=ConfigurationSettings_timestamp_type
      element configurationData: implementation-data-type=ConfigurationSettings_configurationData
      symbol props SymbolProps: symbol=IdsCanSensor_AT_ConfigurationSettings
    AT_ControlCommands: category=STRUCTURE
      element sourceIdentifier: implementation-data-type=ControlCommands_sourceIdentifier
      element timestamp: implementation-data-type=ControlCommands_timestamp_type
      element commandIdentifier: implementation-data-type=ControlCommands_commandIdentifier_type
      symbol props SymbolProps: symbol=IdsCanSensor_AT_ControlCommands
    AT_CycleCounter: category=STRUCTURE
      element counter: implementation-data-type=CycleCounter_counter_type
      symbol props SymbolProps: symbol=IdsCanSensor_AT_CycleCounter
    AT_GatewayDiagnosticFilterEvent: category=STRUCTURE
      element sensorIdentifier: implementation-data-type=GatewayDiagnosticFilterEvent_sensorIdentifier
      element timestamp: implementation-data-type=GatewayDiagnosticFilterEvent_timestamp_type
      element filterState: implementation-data-type=boolean
      symbol props SymbolProps: symbol=IdsCanSensor_AT_GatewayDiagnosticFilterEvent
    AT_GatewayExceptionalData: category=STRUCTURE
      5 x element, all with category=TYPE_REFERENCE:
        sensorIdentifier: implementation-data-type=GatewayExceptionalData_sensorIdentifier
        timestamp: implementation-data-type=GatewayExceptionalData_timestamp_type
        canIdentifierType: implementation-data-type=GatewayExceptionalData_canIdentifierType_type
        canBusIdentifier: implementation-data-type=GatewayExceptionalData_canBusIdentifier_type
        messagePayload: implementation-data-type=GatewayExceptionalData_messagePayload
      symbol props SymbolProps: symbol=IdsCanSensor_AT_GatewayExceptionalData
    IdsCanSensor_AT_OperationStatus: compu-method=IdsCanSensor_AT_OperationStatusCM, range raw 0..65535, implementation-data-type=uint16
      symbol props SymbolProps: symbol=IdsCanSensor_AT_OperationStatus
    AT_PeriodicSignalType: category=STRUCTURE
      element keepAlive: implementation-data-type=AT_CycleCounter
      element elementId: implementation-data-type=PeriodicSignalType_elementId_type
      symbol props SymbolProps: symbol=IdsCanSensor_AT_PeriodicSignalType
    AT_ProtocolFrameData: category=STRUCTURE
      4 x element, all with category=TYPE_REFERENCE:
        sensorIdentifier: implementation-data-type=ProtocolFrameData_sensorIdentifier
        timestamp: implementation-data-type=ProtocolFrameData_timestamp_type
        protocolName: implementation-data-type=ProtocolFrameData_protocolName_type
        protocolFrameContents: implementation-data-type=ProtocolFrameData_protocolFrameContents
      symbol props SymbolProps: symbol=IdsCanSensor_AT_ProtocolFrameData
    AnomalyData_canIdentifierType_type: range phys 0..255, raw 0..255, implementation-data-type=uint8
      symbol props SymbolProps: symbol=IdsCanSensor_AnomalyData_canIdentifierType_type
    AnomalyData_communicationServerIdentifier_type: range phys 0..65535, raw 0..65535, implementation-data-type=uint16
      symbol props SymbolProps: symbol=IdsCanSensor_AnomalyData_communicationServerIdentifier_type
    AnomalyData_messagePayload: category=STRUCTURE, dynamic-array-size-profile=VSA_LINEAR
      element size: implementation-data-type=uint8
      element payload: category=ARRAY
        element AnomalyData_messagePayload_base_type: array-size=63, array-size-handling=ALL-INDICES-SAME-ARRAY-SIZE, array-size-semantics=VARIABLE-SIZE, implementation-data-type=AnomalyData_messagePayload_base_type
      symbol props SymbolProps: symbol=IdsCanSensor_AnomalyData_messagePayload
    AnomalyData_messagePayload_base_type: range phys 0..255, raw 0..255, implementation-data-type=uint8
      symbol props SymbolProps: symbol=IdsCanSensor_AnomalyData_messagePayload_base_type
    AnomalyData_sensorIdentifier: category=STRUCTURE, dynamic-array-size-profile=VSA_LINEAR
      element size: implementation-data-type=uint8
      element payload: category=ARRAY
        element AnomalyData_sensorIdentifier_base_type: array-size=7, array-size-handling=ALL-INDICES-SAME-ARRAY-SIZE, array-size-semantics=VARIABLE-SIZE, implementation-data-type=AnomalyData_sensorIdentifier_base_type
      symbol props SymbolProps: symbol=IdsCanSensor_AnomalyData_sensorIdentifier
    AnomalyData_sensorIdentifier_base_type: range phys 0..255, raw 0..255, implementation-data-type=uint16
      symbol props SymbolProps: symbol=IdsCanSensor_AnomalyData_sensorIdentifier_base_type
    AnomalyData_timestamp_type: range phys 0..18446744073709551615, raw 0..18446744073709551615, implementation-data-type=uint64
      symbol props SymbolProps: symbol=IdsCanSensor_AnomalyData_timestamp_type
    CanSensorFeaturesType_elementId_type: range phys 0, raw 0, implementation-data-type=uint8
      symbol props SymbolProps: symbol=IdsCanSensor_CanSensorFeaturesType_elementId_type
    ConfigurationSettings_configurationData: category=STRUCTURE, dynamic-array-size-profile=VSA_LINEAR
      element size: implementation-data-type=uint16
      element payload: category=ARRAY
        element ConfigurationSettings_configurationData_base_type: array-size=65535, array-size-handling=ALL-INDICES-SAME-ARRAY-SIZE, array-size-semantics=VARIABLE-SIZE, implementation-data-type=ConfigurationSettings_configurationData_base_type
      symbol props SymbolProps: symbol=IdsCanSensor_ConfigurationSettings_configurationData
    ConfigurationSettings_configurationData_base_type: range phys 0..255, raw 0..255, implementation-data-type=uint8
      symbol props SymbolProps: symbol=IdsCanSensor_ConfigurationSettings_configurationData_base_type
    ConfigurationSettings_sensorIdentifier: category=STRUCTURE, dynamic-array-size-profile=VSA_LINEAR
      element size: implementation-data-type=uint8
      element payload: category=ARRAY
        element ConfigurationSettings_sensorIdentifier_base_type: array-size=7, array-size-handling=ALL-INDICES-SAME-ARRAY-SIZE, array-size-semantics=VARIABLE-SIZE, implementation-data-type=ConfigurationSettings_sensorIdentifier_base_type
      symbol props SymbolProps: symbol=IdsCanSensor_ConfigurationSettings_sensorIdentifier
    ConfigurationSettings_sensorIdentifier_base_type: range phys 0..255, raw 0..255, implementation-data-type=uint8
      symbol props SymbolProps: symbol=IdsCanSensor_ConfigurationSettings_sensorIdentifier_base_type
    ConfigurationSettings_timestamp_type: range phys 0..18446744073709551615, raw 0..18446744073709551615, implementation-data-type=uint64
      symbol props SymbolProps: symbol=IdsCanSensor_ConfigurationSettings_timestamp_type
    ControlCommands_commandIdentifier_type: range phys 0..65535, raw 0..65535, implementation-data-type=uint16
      symbol props SymbolProps: symbol=IdsCanSensor_ControlCommands_commandIdentifier_type
    ControlCommands_sourceIdentifier: category=STRUCTURE, dynamic-array-size-profile=VSA_LINEAR
      element size: implementation-data-type=uint8
      element payload: category=ARRAY
        element ControlCommands_sourceIdentifier_base_type: array-size=7, array-size-handling=ALL-INDICES-SAME-ARRAY-SIZE, array-size-semantics=VARIABLE-SIZE, implementation-data-type=ControlCommands_sourceIdentifier_base_type
      symbol props SymbolProps: symbol=IdsCanSensor_ControlCommands_sourceIdentifier
    ControlCommands_sourceIdentifier_base_type: range phys 0..255, raw 0..255, implementation-data-type=uint16
      symbol props SymbolProps: symbol=IdsCanSensor_ControlCommands_sourceIdentifier_base_type
    ControlCommands_timestamp_type: range phys 0..18446744073709551615, raw 0..18446744073709551615, implementation-data-type=uint64
      symbol props SymbolProps: symbol=IdsCanSensor_ControlCommands_timestamp_type
    CycleCounter_counter_type: range phys 0..10000000000, raw 0..10000000000, implementation-data-type=uint64
      symbol props SymbolProps: symbol=IdsCanSensor_CycleCounter_counter_type
    GatewayDiagnosticFilterEvent_sensorIdentifier: category=STRUCTURE, dynamic-array-size-profile=VSA_LINEAR
      element size: implementation-data-type=uint8
      element payload: category=ARRAY
        element GatewayDiagnosticFilterEvent_sensorIdentifier_base_type: array-size=7, array-size-handling=ALL-INDICES-SAME-ARRAY-SIZE, array-size-semantics=VARIABLE-SIZE, implementation-data-type=GatewayDiagnosticFilterEvent_sensorIdentifier_base_type
      symbol props SymbolProps: symbol=IdsCanSensor_GatewayDiagnosticFilterEvent_sensorIdentifier
    GatewayDiagnosticFilterEvent_sensorIdentifier_base_type: range phys 0..255, raw 0..255, implementation-data-type=uint16
      symbol props SymbolProps: symbol=IdsCanSensor_GatewayDiagnosticFilterEvent_sensorIdentifier_base_type
    GatewayDiagnosticFilterEvent_timestamp_type: range phys 0..18446744073709551615, raw 0..18446744073709551615, implementation-data-type=uint64
      symbol props SymbolProps: symbol=IdsCanSensor_GatewayDiagnosticFilterEvent_timestamp_type
    GatewayExceptionalData_canBusIdentifier_type: range phys 0..65535, raw 0..65535, implementation-data-type=uint16
      symbol props SymbolProps: symbol=IdsCanSensor_GatewayExceptionalData_canBusIdentifier_type
    GatewayExceptionalData_canIdentifierType_type: range phys 0..255, raw 0..255, implementation-data-type=uint8
      symbol props SymbolProps: symbol=IdsCanSensor_GatewayExceptionalData_canIdentifierType_type
    GatewayExceptionalData_messagePayload: category=STRUCTURE, dynamic-array-size-profile=VSA_LINEAR
      element size: implementation-data-type=uint8
      element payload: category=ARRAY
        element GatewayExceptionalData_messagePayload_base_type: array-size=63, array-size-handling=ALL-INDICES-SAME-ARRAY-SIZE, array-size-semantics=VARIABLE-SIZE, implementation-data-type=GatewayExceptionalData_messagePayload_base_type
      symbol props SymbolProps: symbol=IdsCanSensor_GatewayExceptionalData_messagePayload
    GatewayExceptionalData_messagePayload_base_type: range phys 0..255, raw 0..255, implementation-data-type=uint8
      symbol props SymbolProps: symbol=IdsCanSensor_GatewayExceptionalData_messagePayload_base_type
    GatewayExceptionalData_sensorIdentifier: category=STRUCTURE, dynamic-array-size-profile=VSA_LINEAR
      element size: implementation-data-type=uint8
      element payload: category=ARRAY
        element GatewayExceptionalData_sensorIdentifier_base_type: array-size=7, array-size-handling=ALL-INDICES-SAME-ARRAY-SIZE, array-size-semantics=VARIABLE-SIZE, implementation-data-type=GatewayExceptionalData_sensorIdentifier_base_type
      symbol props SymbolProps: symbol=IdsCanSensor_GatewayExceptionalData_sensorIdentifier
    GatewayExceptionalData_sensorIdentifier_base_type: range phys 0..255, raw 0..255, implementation-data-type=uint16
      symbol props SymbolProps: symbol=IdsCanSensor_GatewayExceptionalData_sensorIdentifier_base_type
    GatewayExceptionalData_timestamp_type: range phys 0..18446744073709551615, raw 0..18446744073709551615, implementation-data-type=uint64
      symbol props SymbolProps: symbol=IdsCanSensor_GatewayExceptionalData_timestamp_type
    PeriodicSignalType_elementId_type: range phys 0, raw 0, implementation-data-type=uint8
      symbol props SymbolProps: symbol=IdsCanSensor_PeriodicSignalType_elementId_type
    ProtocolFrameData_protocolFrameContents: category=STRUCTURE, dynamic-array-size-profile=VSA_LINEAR
      element size: implementation-data-type=uint8
      element payload: category=ARRAY
        element ProtocolFrameData_protocolFrameContents_base_type: array-size=63, array-size-handling=ALL-INDICES-SAME-ARRAY-SIZE, array-size-semantics=VARIABLE-SIZE, implementation-data-type=ProtocolFrameData_protocolFrameContents_base_type
      symbol props SymbolProps: symbol=IdsCanSensor_ProtocolFrameData_protocolFrameContents
    ProtocolFrameData_protocolFrameContents_base_type: range phys 0..255, raw 0..255, implementation-data-type=uint8
      symbol props SymbolProps: symbol=IdsCanSensor_ProtocolFrameData_protocolFrameContents_base_type
    ProtocolFrameData_protocolName_type: range phys 0..255, raw 0..255, implementation-data-type=uint8
      symbol props SymbolProps: symbol=IdsCanSensor_ProtocolFrameData_protocolName_type
    ProtocolFrameData_sensorIdentifier: category=STRUCTURE, dynamic-array-size-profile=VSA_LINEAR
      element size: implementation-data-type=uint8
      element payload: category=ARRAY
        element ProtocolFrameData_sensorIdentifier_base_type: array-size=7, array-size-handling=ALL-INDICES-SAME-ARRAY-SIZE, array-size-semantics=VARIABLE-SIZE, implementation-data-type=ProtocolFrameData_sensorIdentifier_base_type
      symbol props SymbolProps: symbol=IdsCanSensor_ProtocolFrameData_sensorIdentifier
    ProtocolFrameData_sensorIdentifier_base_type: range phys 0..255, raw 0..255, implementation-data-type=uint16
      symbol props SymbolProps: symbol=IdsCanSensor_ProtocolFrameData_sensorIdentifier_base_type
    ProtocolFrameData_timestamp_type: range phys 0..18446744073709551615, raw 0..18446744073709551615, implementation-data-type=uint64
      symbol props SymbolProps: symbol=IdsCanSensor_ProtocolFrameData_timestamp_type
    IdsCanSensor_UUIDApp: category=ARRAY
      element UUIDAppBase: array-size=16, array-size-semantics=FIXED-SIZE, implementation-data-type=uint8
      symbol props SymbolProps: symbol=IdsCanSensor_UUIDApp
  11 x application array data type, all with category=ARRAY:
    AnomalyData_messagePayloadApp: dynamic-array-size-profile=VSA_LINEAR
      element AnomalyData_messagePayload_base_type: category=VALUE, type=AnomalyData_messagePayload_base_typeApp, array-size-handling=ALL-INDICES-SAME-ARRAY-SIZE, array-size-semantics=VARIABLE-SIZE, max-number-of-elements=63
    AnomalyData_sensorIdentifierApp: dynamic-array-size-profile=VSA_LINEAR
      element AnomalyData_sensorIdentifier_base_type: category=VALUE, type=AnomalyData_sensorIdentifier_base_typeApp, array-size-handling=ALL-INDICES-SAME-ARRAY-SIZE, array-size-semantics=VARIABLE-SIZE, max-number-of-elements=7
    ConfigurationSettings_configurationDataApp: dynamic-array-size-profile=VSA_LINEAR
      element ConfigurationSettings_configurationData_base_type: category=VALUE, type=ConfigurationSettings_configurationData_base_typeApp, array-size-handling=ALL-INDICES-SAME-ARRAY-SIZE, array-size-semantics=VARIABLE-SIZE, max-number-of-elements=65535
    ConfigurationSettings_sensorIdentifierApp: dynamic-array-size-profile=VSA_LINEAR
      element ConfigurationSettings_sensorIdentifier_base_type: category=VALUE, type=ConfigurationSettings_sensorIdentifier_base_typeApp, array-size-handling=ALL-INDICES-SAME-ARRAY-SIZE, array-size-semantics=VARIABLE-SIZE, max-number-of-elements=7
    ControlCommands_sourceIdentifierApp: dynamic-array-size-profile=VSA_LINEAR
      element ControlCommands_sourceIdentifier_base_type: category=VALUE, type=ControlCommands_sourceIdentifier_base_typeApp, array-size-handling=ALL-INDICES-SAME-ARRAY-SIZE, array-size-semantics=VARIABLE-SIZE, max-number-of-elements=7
    GatewayDiagnosticFilterEvent_sensorIdentifierApp: dynamic-array-size-profile=VSA_LINEAR
      element GatewayDiagnosticFilterEvent_sensorIdentifier_base_type: category=VALUE, type=GatewayDiagnosticFilterEvent_sensorIdentifier_base_typeApp, array-size-handling=ALL-INDICES-SAME-ARRAY-SIZE, array-size-semantics=VARIABLE-SIZE, max-number-of-elements=7
    GatewayExceptionalData_messagePayloadApp: dynamic-array-size-profile=VSA_LINEAR
      element GatewayExceptionalData_messagePayload_base_type: category=VALUE, type=GatewayExceptionalData_messagePayload_base_typeApp, array-size-handling=ALL-INDICES-SAME-ARRAY-SIZE, array-size-semantics=VARIABLE-SIZE, max-number-of-elements=63
    GatewayExceptionalData_sensorIdentifierApp: dynamic-array-size-profile=VSA_LINEAR
      element GatewayExceptionalData_sensorIdentifier_base_type: category=VALUE, type=GatewayExceptionalData_sensorIdentifier_base_typeApp, array-size-handling=ALL-INDICES-SAME-ARRAY-SIZE, array-size-semantics=VARIABLE-SIZE, max-number-of-elements=7
    ProtocolFrameData_protocolFrameContentsApp: dynamic-array-size-profile=VSA_LINEAR
      element ProtocolFrameData_protocolFrameContents_base_type: category=VALUE, type=ProtocolFrameData_protocolFrameContents_base_typeApp, array-size-handling=ALL-INDICES-SAME-ARRAY-SIZE, array-size-semantics=VARIABLE-SIZE, max-number-of-elements=63
    ProtocolFrameData_sensorIdentifierApp: dynamic-array-size-profile=VSA_LINEAR
      element ProtocolFrameData_sensorIdentifier_base_type: category=VALUE, type=ProtocolFrameData_sensorIdentifier_base_typeApp, array-size-handling=ALL-INDICES-SAME-ARRAY-SIZE, array-size-semantics=VARIABLE-SIZE, max-number-of-elements=7
    IdsCanSensor_UUIDAppApp
      element uint8: category=VALUE, type=IdsCanSensor_uint8App, array-size-semantics=FIXED-SIZE, max-number-of-elements=16
  27 x app type, all with category=VALUE:
    AnomalyData_canIdentifierType_typeApp: compu {identical}, range phys 0..255, raw 0..255
    AnomalyData_communicationServerIdentifier_typeApp: compu {identical}, range phys 0..65535, raw 0..65535
    AnomalyData_messagePayload_base_typeApp: compu {identical}, range phys 0..255, raw 0..255
    AnomalyData_sensorIdentifier_base_typeApp: compu {identical}, range phys 0..255, raw 0..255
    AnomalyData_timestamp_typeApp: compu {identical}, range phys 0..18446744073709551615, raw 0..18446744073709551615
    IdsCanSensor_AT_OperationStatusApp: compu-method=IdsCanSensor_AT_OperationStatusCM, range raw 0..65535
    CanSensorFeaturesType_elementId_typeApp: compu {identical}, range phys 0, raw 0
    ConfigurationSettings_configurationData_base_typeApp: compu {identical}, range phys 0..255, raw 0..255
    ConfigurationSettings_sensorIdentifier_base_typeApp: compu {identical}, range phys 0..255, raw 0..255
    ConfigurationSettings_timestamp_typeApp: compu {identical}, range phys 0..18446744073709551615, raw 0..18446744073709551615
    ControlCommands_commandIdentifier_typeApp: compu {identical}, range phys 0..65535, raw 0..65535
    ControlCommands_sourceIdentifier_base_typeApp: compu {identical}, range phys 0..255, raw 0..255
    ControlCommands_timestamp_typeApp: compu {identical}, range phys 0..18446744073709551615, raw 0..18446744073709551615
    CycleCounter_counter_typeApp: compu {identical}, range phys 0..10000000000, raw 0..10000000000
    GatewayDiagnosticFilterEvent_sensorIdentifier_base_typeApp: compu {identical}, range phys 0..255, raw 0..255
    GatewayDiagnosticFilterEvent_timestamp_typeApp: compu {identical}, range phys 0..18446744073709551615, raw 0..18446744073709551615
    GatewayExceptionalData_canBusIdentifier_typeApp: compu {identical}, range phys 0..65535, raw 0..65535
    GatewayExceptionalData_canIdentifierType_typeApp: compu {identical}, range phys 0..255, raw 0..255
    GatewayExceptionalData_messagePayload_base_typeApp: compu {identical}, range phys 0..255, raw 0..255
    GatewayExceptionalData_sensorIdentifier_base_typeApp: compu {identical}, range phys 0..255, raw 0..255
    GatewayExceptionalData_timestamp_typeApp: compu {identical}, range phys 0..18446744073709551615, raw 0..18446744073709551615
    PeriodicSignalType_elementId_typeApp: compu {identical}, range phys 0, raw 0
    ProtocolFrameData_protocolFrameContents_base_typeApp: compu {identical}, range phys 0..255, raw 0..255
    ProtocolFrameData_protocolName_typeApp: compu {identical}, range phys 0..255, raw 0..255
    ProtocolFrameData_sensorIdentifier_base_typeApp: compu {identical}, range phys 0..255, raw 0..255
    ProtocolFrameData_timestamp_typeApp: compu {identical}, range phys 0..18446744073709551615, raw 0..18446744073709551615
    IdsCanSensor_uint8App
  11 x application record data type, all with category=STRUCTURE:
    AT_AnomalyDataApp
      5 x application record element:
        sensorIdentifier: category=ARRAY, type=AnomalyData_sensorIdentifierApp
        timestamp: category=VALUE, type=AnomalyData_timestamp_typeApp
        canIdentifierType: category=VALUE, type=AnomalyData_canIdentifierType_typeApp
        communicationServerIdentifier: category=VALUE, type=AnomalyData_communicationServerIdentifier_typeApp
        messagePayload: category=ARRAY, type=AnomalyData_messagePayloadApp
    AT_CanSensorFeaturesSetApp
      application record element configurationSettings: category=STRUCTURE, type=AT_ConfigurationSettingsApp
    AT_CanSensorFeaturesTypeApp
      7 x application record element:
        configurationSettings: category=STRUCTURE, type=AT_ConfigurationSettingsApp
        controlCommands: category=STRUCTURE, type=AT_ControlCommandsApp
        protocalFrameData: category=STRUCTURE, type=AT_ProtocolFrameDataApp
        anomalyData: category=STRUCTURE, type=AT_AnomalyDataApp
        gatewayExceptionalData: category=STRUCTURE, type=AT_GatewayExceptionalDataApp
        gatewayDiagnosticFilterEvent: category=STRUCTURE, type=AT_GatewayDiagnosticFilterEventApp
        elementId: category=VALUE, type=CanSensorFeaturesType_elementId_typeApp
    AT_CanSensorFeaturesUndefineApp
      application record element configurationSettings: category=BOOLEAN, type=booleanApp
    AT_ConfigurationSettingsApp
      application record element sensorIdentifier: category=ARRAY, type=ConfigurationSettings_sensorIdentifierApp
      application record element timestamp: category=VALUE, type=ConfigurationSettings_timestamp_typeApp
      application record element configurationData: category=ARRAY, type=ConfigurationSettings_configurationDataApp
    AT_ControlCommandsApp
      application record element sourceIdentifier: category=ARRAY, type=ControlCommands_sourceIdentifierApp
      application record element timestamp: category=VALUE, type=ControlCommands_timestamp_typeApp
      application record element commandIdentifier: category=VALUE, type=ControlCommands_commandIdentifier_typeApp
    AT_CycleCounterApp
      application record element counter: category=VALUE, type=CycleCounter_counter_typeApp
    AT_GatewayDiagnosticFilterEventApp
      application record element sensorIdentifier: category=ARRAY, type=GatewayDiagnosticFilterEvent_sensorIdentifierApp
      application record element timestamp: category=VALUE, type=GatewayDiagnosticFilterEvent_timestamp_typeApp
      application record element filterState: category=BOOLEAN, type=booleanApp
    AT_GatewayExceptionalDataApp
      5 x application record element:
        sensorIdentifier: category=ARRAY, type=GatewayExceptionalData_sensorIdentifierApp
        timestamp: category=VALUE, type=GatewayExceptionalData_timestamp_typeApp
        canIdentifierType: category=VALUE, type=GatewayExceptionalData_canIdentifierType_typeApp
        canBusIdentifier: category=VALUE, type=GatewayExceptionalData_canBusIdentifier_typeApp
        messagePayload: category=ARRAY, type=GatewayExceptionalData_messagePayloadApp
    AT_PeriodicSignalTypeApp
      application record element keepAlive: category=STRUCTURE, type=AT_CycleCounterApp
      application record element elementId: category=VALUE, type=PeriodicSignalType_elementId_typeApp
    AT_ProtocolFrameDataApp
      4 x application record element:
        sensorIdentifier: category=ARRAY, type=ProtocolFrameData_sensorIdentifierApp
        timestamp: category=VALUE, type=ProtocolFrameData_timestamp_typeApp
        protocolName: category=VALUE, type=ProtocolFrameData_protocolName_typeApp
        protocolFrameContents: category=ARRAY, type=ProtocolFrameData_protocolFrameContentsApp
package /vwg/services/IdsCanSensor/deployment
  data type mapping set IdsCanSensorMappings
    data-type-maps:
      application-data-type=AnomalyData_messagePayloadApp, implementation-data-type=AnomalyData_messagePayload
      application-data-type=AnomalyData_sensorIdentifierApp, implementation-data-type=AnomalyData_sensorIdentifier
      application-data-type=ConfigurationSettings_configurationDataApp, implementation-data-type=ConfigurationSettings_configurationData
      application-data-type=ConfigurationSettings_sensorIdentifierApp, implementation-data-type=ConfigurationSettings_sensorIdentifier
      application-data-type=ControlCommands_sourceIdentifierApp, implementation-data-type=ControlCommands_sourceIdentifier
      application-data-type=GatewayDiagnosticFilterEvent_sensorIdentifierApp, implementation-data-type=GatewayDiagnosticFilterEvent_sensorIdentifier
      application-data-type=GatewayExceptionalData_messagePayloadApp, implementation-data-type=GatewayExceptionalData_messagePayload
      application-data-type=GatewayExceptionalData_sensorIdentifierApp, implementation-data-type=GatewayExceptionalData_sensorIdentifier
      application-data-type=ProtocolFrameData_protocolFrameContentsApp, implementation-data-type=ProtocolFrameData_protocolFrameContents
      application-data-type=ProtocolFrameData_sensorIdentifierApp, implementation-data-type=ProtocolFrameData_sensorIdentifier
      application-data-type=IdsCanSensor_UUIDAppApp, implementation-data-type=IdsCanSensor_UUIDApp
      application-data-type=AnomalyData_canIdentifierType_typeApp, implementation-data-type=AnomalyData_canIdentifierType_type
      application-data-type=AnomalyData_communicationServerIdentifier_typeApp, implementation-data-type=AnomalyData_communicationServerIdentifier_type
      application-data-type=AnomalyData_messagePayload_base_typeApp, implementation-data-type=AnomalyData_messagePayload_base_type
      application-data-type=AnomalyData_sensorIdentifier_base_typeApp, implementation-data-type=AnomalyData_sensorIdentifier_base_type
      application-data-type=AnomalyData_timestamp_typeApp, implementation-data-type=AnomalyData_timestamp_type
      application-data-type=IdsCanSensor_AT_OperationStatusApp, implementation-data-type=IdsCanSensor_AT_OperationStatus
      application-data-type=CanSensorFeaturesType_elementId_typeApp, implementation-data-type=CanSensorFeaturesType_elementId_type
      application-data-type=ConfigurationSettings_configurationData_base_typeApp, implementation-data-type=ConfigurationSettings_configurationData_base_type
      application-data-type=ConfigurationSettings_sensorIdentifier_base_typeApp, implementation-data-type=ConfigurationSettings_sensorIdentifier_base_type
      application-data-type=ConfigurationSettings_timestamp_typeApp, implementation-data-type=ConfigurationSettings_timestamp_type
      application-data-type=ControlCommands_commandIdentifier_typeApp, implementation-data-type=ControlCommands_commandIdentifier_type
      application-data-type=ControlCommands_sourceIdentifier_base_typeApp, implementation-data-type=ControlCommands_sourceIdentifier_base_type
      application-data-type=ControlCommands_timestamp_typeApp, implementation-data-type=ControlCommands_timestamp_type
      application-data-type=CycleCounter_counter_typeApp, implementation-data-type=CycleCounter_counter_type
      application-data-type=GatewayDiagnosticFilterEvent_sensorIdentifier_base_typeApp, implementation-data-type=GatewayDiagnosticFilterEvent_sensorIdentifier_base_type
      application-data-type=GatewayDiagnosticFilterEvent_timestamp_typeApp, implementation-data-type=GatewayDiagnosticFilterEvent_timestamp_type
      application-data-type=GatewayExceptionalData_canBusIdentifier_typeApp, implementation-data-type=GatewayExceptionalData_canBusIdentifier_type
      application-data-type=GatewayExceptionalData_canIdentifierType_typeApp, implementation-data-type=GatewayExceptionalData_canIdentifierType_type
      application-data-type=GatewayExceptionalData_messagePayload_base_typeApp, implementation-data-type=GatewayExceptionalData_messagePayload_base_type
      application-data-type=GatewayExceptionalData_sensorIdentifier_base_typeApp, implementation-data-type=GatewayExceptionalData_sensorIdentifier_base_type
      application-data-type=GatewayExceptionalData_timestamp_typeApp, implementation-data-type=GatewayExceptionalData_timestamp_type
      application-data-type=PeriodicSignalType_elementId_typeApp, implementation-data-type=PeriodicSignalType_elementId_type
      application-data-type=ProtocolFrameData_protocolFrameContents_base_typeApp, implementation-data-type=ProtocolFrameData_protocolFrameContents_base_type
      application-data-type=ProtocolFrameData_protocolName_typeApp, implementation-data-type=ProtocolFrameData_protocolName_type
      application-data-type=ProtocolFrameData_sensorIdentifier_base_typeApp, implementation-data-type=ProtocolFrameData_sensorIdentifier_base_type
      application-data-type=ProtocolFrameData_timestamp_typeApp, implementation-data-type=ProtocolFrameData_timestamp_type
      application-data-type=IdsCanSensor_uint8App, implementation-data-type=uint8
      application-data-type=AT_AnomalyDataApp, implementation-data-type=AT_AnomalyData
      application-data-type=AT_CanSensorFeaturesSetApp, implementation-data-type=AT_CanSensorFeaturesSet
      application-data-type=AT_CanSensorFeaturesTypeApp, implementation-data-type=AT_CanSensorFeaturesType
      application-data-type=AT_CanSensorFeaturesUndefineApp, implementation-data-type=AT_CanSensorFeaturesUndefine
      application-data-type=AT_ConfigurationSettingsApp, implementation-data-type=AT_ConfigurationSettings
      application-data-type=AT_ControlCommandsApp, implementation-data-type=AT_ControlCommands
      application-data-type=AT_CycleCounterApp, implementation-data-type=AT_CycleCounter
      application-data-type=AT_GatewayDiagnosticFilterEventApp, implementation-data-type=AT_GatewayDiagnosticFilterEvent
      application-data-type=AT_GatewayExceptionalDataApp, implementation-data-type=AT_GatewayExceptionalData
      application-data-type=AT_PeriodicSignalTypeApp, implementation-data-type=AT_PeriodicSignalType
      application-data-type=AT_ProtocolFrameDataApp, implementation-data-type=AT_ProtocolFrameData
package /vwg/services/IDSSecurityEventSmall/datatypes
  6 x impl type:
    AT_ByteType: range phys 0..255, raw 0..255, implementation-data-type=uint8
      symbol props SymbolProps: symbol=IDSSecurityEventSmall_AT_ByteType
    AT_SecurityEventStruct: category=STRUCTURE
      4 x element:
        availabilityBitfield: category=ARRAY, array-size-semantics=FIXED-SIZE
          element availabilityBitfieldArrayType: array-size=1, implementation-data-type=uint8
        eventFrame: implementation-data-type=SecurityEventStruct_eventFrame
        timestamp: implementation-data-type=SecurityEventStruct_timestamp
        contextData: implementation-data-type=SecurityEventStruct_contextData
      symbol props SymbolProps: symbol=IDSSecurityEventSmall_AT_SecurityEventStruct
    SecurityEventStruct_contextData: category=STRUCTURE, dynamic-array-size-profile=VSA_LINEAR
      element size: implementation-data-type=uint16
      element payload: category=ARRAY
        element AT_ByteType: array-size=1026, array-size-handling=ALL-INDICES-SAME-ARRAY-SIZE, array-size-semantics=VARIABLE-SIZE, implementation-data-type=AT_ByteType
      symbol props SymbolProps: symbol=IDSSecurityEventSmall_SecurityEventStruct_contextData
    SecurityEventStruct_eventFrame: category=ARRAY
      element SecurityEventStruct_eventFrameBase: array-size=8, array-size-semantics=FIXED-SIZE, implementation-data-type=AT_ByteType
      symbol props SymbolProps: symbol=IDSSecurityEventSmall_SecurityEventStruct_eventFrame
    SecurityEventStruct_timestamp: category=ARRAY
      element SecurityEventStruct_timestampBase: array-size=8, array-size-semantics=FIXED-SIZE, implementation-data-type=AT_ByteType
      symbol props SymbolProps: symbol=IDSSecurityEventSmall_SecurityEventStruct_timestamp
    IDSSecurityEventSmall_UUIDApp: category=ARRAY
      element UUIDAppBase: array-size=16, array-size-semantics=FIXED-SIZE, implementation-data-type=uint8
      symbol props SymbolProps: symbol=IDSSecurityEventSmall_UUIDApp
  4 x application array data type, all with category=ARRAY:
    SecurityEventStruct_contextDataApp: dynamic-array-size-profile=VSA_LINEAR
      element AT_ByteType: category=VALUE, type=AT_ByteTypeApp, array-size-handling=ALL-INDICES-SAME-ARRAY-SIZE, array-size-semantics=VARIABLE-SIZE, max-number-of-elements=1026
    SecurityEventStruct_eventFrameApp
      element AT_ByteType: category=VALUE, type=AT_ByteTypeApp, array-size-semantics=FIXED-SIZE, max-number-of-elements=8
    SecurityEventStruct_timestampApp
      element AT_ByteType: category=VALUE, type=AT_ByteTypeApp, array-size-semantics=FIXED-SIZE, max-number-of-elements=8
    IDSSecurityEventSmall_UUIDAppApp
      element uint8: category=VALUE, type=IDSSecurityEventSmall_uint8App, array-size-semantics=FIXED-SIZE, max-number-of-elements=16
  app type AT_ByteTypeApp: category=VALUE, compu {identical}, range phys 0..255, raw 0..255
  app type IDSSecurityEventSmall_uint8App: category=VALUE
  application record data type AT_SecurityEventStructApp: category=STRUCTURE
    application record element eventFrame: category=ARRAY, type=SecurityEventStruct_eventFrameApp
    application record element timestamp: category=ARRAY, type=SecurityEventStruct_timestampApp
    application record element contextData: category=ARRAY, type=SecurityEventStruct_contextDataApp
package /vwg/services/IDSSecurityEventSmall/deployment
  data type mapping set IDSSecurityEventSmallMappings
    data-type-maps:
      application-data-type=SecurityEventStruct_contextDataApp, implementation-data-type=SecurityEventStruct_contextData
      application-data-type=SecurityEventStruct_eventFrameApp, implementation-data-type=SecurityEventStruct_eventFrame
      application-data-type=SecurityEventStruct_timestampApp, implementation-data-type=SecurityEventStruct_timestamp
      application-data-type=IDSSecurityEventSmall_UUIDAppApp, implementation-data-type=IDSSecurityEventSmall_UUIDApp
      application-data-type=AT_ByteTypeApp, implementation-data-type=AT_ByteType
      application-data-type=IDSSecurityEventSmall_uint8App, implementation-data-type=uint8
      application-data-type=AT_SecurityEventStructApp, implementation-data-type=AT_SecurityEventStruct
package /RecDataType
  50 x impl type:
    AT_SG_ClampControl_01: category=STRUCTURE
      7 x element, all with category=TYPE_REFERENCE:
        ClampControl_01_BZ: implementation-data-type=SG_ClampControl_01_ClampControl_01_BZ_type
        ClampControl_01_CRC: implementation-data-type=SG_ClampControl_01_ClampControl_01_CRC_type
        KST_Ausstiegswunsch_Status: implementation-data-type=SG_ClampControl_01_KST_Ausstiegswunsch_Status_type
        KST_ComfortReadyStatus: implementation-data-type=SG_ClampControl_01_KST_ComfortReadyStatus_type
        KST_KL_15: implementation-data-type=SG_ClampControl_01_KST_KL_15_type
        KST_Kl_50_Startanforderung: implementation-data-type=SG_ClampControl_01_KST_Kl_50_Startanforderung_type
        KST_Kl_S: implementation-data-type=SG_ClampControl_01_KST_Kl_S_type
    SG_ClampControl_01_ClampControl_01_BZ_type: implementation-data-type=uint8
    SG_ClampControl_01_ClampControl_01_CRC_type: implementation-data-type=uint8
    SG_ClampControl_01_KST_Ausstiegswunsch_Status_type: implementation-data-type=boolean
    SG_ClampControl_01_KST_ComfortReadyStatus_type: implementation-data-type=boolean
    SG_ClampControl_01_KST_KL_15_type: implementation-data-type=boolean
    SG_ClampControl_01_KST_Kl_50_Startanforderung_type: implementation-data-type=boolean
    SG_ClampControl_01_KST_Kl_S_type: implementation-data-type=boolean
    AT_SG_HWP_01: category=STRUCTURE
      element HWP_01_BZ: implementation-data-type=SG_HWP_01_HWP_01_BZ_type
      element HWP_01_CRC: implementation-data-type=SG_HWP_01_HWP_01_CRC_type
      element HWP_HMI_ASIL_Color: implementation-data-type=SG_HWP_01_HWP_HMI_ASIL_Color_type
    SG_HWP_01_HWP_01_BZ_type: implementation-data-type=uint8
    SG_HWP_01_HWP_01_CRC_type: implementation-data-type=uint8
    SG_HWP_01_HWP_HMI_ASIL_Color_type: implementation-data-type=uint8
    AT_SG_ORU_Control_A_01: category=STRUCTURE
      5 x element, all with category=TYPE_REFERENCE:
        ORU_Control_A_01_BZ: implementation-data-type=SG_ORU_Control_A_01_ORU_Control_A_01_BZ_type
        ORU_Control_A_01_CRC: implementation-data-type=SG_ORU_Control_A_01_ORU_Control_A_01_CRC_type
        OnlineRemoteUpdateControlA: implementation-data-type=SG_ORU_Control_A_01_OnlineRemoteUpdateControlA_type
        OnlineRemoteUpdateControlOldA: implementation-data-type=SG_ORU_Control_A_01_OnlineRemoteUpdateControlOldA_type
        OruVehicleLockRequestA: implementation-data-type=SG_ORU_Control_A_01_OruVehicleLockRequestA_type
    SG_ORU_Control_A_01_ORU_Control_A_01_BZ_type: implementation-data-type=uint8
    SG_ORU_Control_A_01_ORU_Control_A_01_CRC_type: implementation-data-type=uint8
    SG_ORU_Control_A_01_OnlineRemoteUpdateControlA_type: implementation-data-type=uint8
    SG_ORU_Control_A_01_OnlineRemoteUpdateControlOldA_type: implementation-data-type=uint8
    SG_ORU_Control_A_01_OruVehicleLockRequestA_type: implementation-data-type=uint8
    AT_SG_ORU_Control_D_01: category=STRUCTURE
      4 x element, all with category=TYPE_REFERENCE:
        ORU_Control_D_01_BZ: implementation-data-type=SG_ORU_Control_D_01_ORU_Control_D_01_BZ_type
        ORU_Control_D_01_CRC: implementation-data-type=SG_ORU_Control_D_01_ORU_Control_D_01_CRC_type
        OnlineRemoteUpdateControlD: implementation-data-type=SG_ORU_Control_D_01_OnlineRemoteUpdateControlD_type
        OnlineRemoteUpdateControlOldD: implementation-data-type=SG_ORU_Control_D_01_OnlineRemoteUpdateControlOldD_type
    SG_ORU_Control_D_01_ORU_Control_D_01_BZ_type: implementation-data-type=uint8
    SG_ORU_Control_D_01_ORU_Control_D_01_CRC_type: implementation-data-type=uint8
    SG_ORU_Control_D_01_OnlineRemoteUpdateControlD_type: implementation-data-type=uint8
    SG_ORU_Control_D_01_OnlineRemoteUpdateControlOldD_type: implementation-data-type=uint8
    AT_SG_OTAMC_D_01: category=STRUCTURE
      element OTAMC_D_01_BZ: implementation-data-type=SG_OTAMC_D_01_OTAMC_D_01_BZ_type
      element OTAMC_D_01_CRC: implementation-data-type=SG_OTAMC_D_01_OTAMC_D_01_CRC_type
      element VehicleProtectedEnvironment_D: implementation-data-type=SG_OTAMC_D_01_VehicleProtectedEnvironment_D_type
    SG_OTAMC_D_01_OTAMC_D_01_BZ_type: implementation-data-type=uint8
    SG_OTAMC_D_01_OTAMC_D_01_CRC_type: implementation-data-type=uint8
    SG_OTAMC_D_01_VehicleProtectedEnvironment_D_type: implementation-data-type=uint8
    AT_SG_VDSO_05: category=STRUCTURE
      4 x element, all with category=TYPE_REFERENCE:
        VDSO_05_BZ: implementation-data-type=SG_VDSO_05_VDSO_05_BZ_type
        VDSO_05_CRC: implementation-data-type=SG_VDSO_05_VDSO_05_CRC_type
        VDSO_Vx3d: implementation-data-type=SG_VDSO_05_VDSO_Vx3d_type
        VDSO_Vx3dDisp: implementation-data-type=SG_VDSO_05_VDSO_Vx3dDisp_type
    SG_VDSO_05_VDSO_05_BZ_type: implementation-data-type=uint8
    SG_VDSO_05_VDSO_05_CRC_type: implementation-data-type=uint8
    SG_VDSO_05_VDSO_Vx3d_type: implementation-data-type=uint16
    SG_VDSO_05_VDSO_Vx3dDisp_type: implementation-data-type=uint16
    AT_SG_WFS_02: category=STRUCTURE
      17 x element, all with category=TYPE_REFERENCE:
        VIN_1: implementation-data-type=SG_WFS_02_VIN_1_type
        VIN_{10..17}: implementation-data-type=SG_WFS_02_VIN_{10..17}_type
        VIN_{2..9}: implementation-data-type=SG_WFS_02_VIN_{2..9}_type
    SG_WFS_02_VIN_1_type: implementation-data-type=uint8
    SG_WFS_02_VIN_{10..17}_type: implementation-data-type=uint8
    SG_WFS_02_VIN_{2..9}_type: implementation-data-type=uint8
